AUTOSAR XML (schema 4-2-2)
standard types defined: boolean, sint8, uint16, uint32, uint8, boolean_CompuMethod, boolean_DataConstr, sint8_DataConstr, uint16_DataConstr, uint32_DataConstr
package /ApplicationDataTypes
  7 x app type, all with category=VALUE:
    CarModSts1_2: compu-method=CarModSts1_1, range raw 0..5
    FltEgyCns1_2: compu {0=FltEgyCns1_NoFlt, 1=FltEgyCns1_Flt; unit Unitless}, range raw 0..1
    Nr2_3: compu {phys=raw for raw 0..255; unit Unitless}, range phys 0..255
    Nr5_2: compu {identical; unit Unitless}, range phys 0..7
    UInt4_2: compu {identical; unit Unitless}, range phys 0..15
    UInt8_2: compu {identical; unit Unitless}, range phys 0..255
    UsgModSts1_2: compu-method=UsgModSts1_1, range raw 0..13
  application record data type VehCfgPrm_3: category=STRUCTURE
    8 x application record element, all with category=VALUE, type=Nr2_3:
      BlkIDBytePosn1
      CCPBytePosn{2..8}
  application record data type VehModMngtGlbSafe1_2: category=STRUCTURE
    10 x application record element, all with category=VALUE:
      UsgModSts: type=UsgModSts1_2
      CarModSts1: type=CarModSts1_2
      CarModSubtypWdCarModSubtyp: type=Nr5_2
      EgyLvlElecMai: type=UInt4_2
      EgyLvlElecSubtyp: type=UInt4_2
      PwrLvlElecMai: type=UInt4_2
      PwrLvlElecSubtyp: type=UInt4_2
      FltEgyCnsWdSts: type=FltEgyCns1_2
      Chks: type=UInt8_2
      Cntr: type=UInt4_2
package /BaseTypes
  21 x base type, all with category=FIXED_LENGTH:
    Boolean_2: base-type-size=1, base-type-encoding=BOOLEAN, native-declaration=boolean
    BRMBatteRatedCp_1: base-type-size=16, base-type-encoding=NONE, native-declaration=uint16
    CarTiGlb_2: base-type-size=32, base-type-encoding=NONE, native-declaration=uint32
    HvBattCellTNr_1: base-type-size=16, base-type-encoding=NONE, native-declaration=uint16
    HvBattNr_1: base-type-size=8, base-type-encoding=NONE, native-declaration=uint8
    HvR1_1: base-type-size=16, base-type-encoding=NONE, native-declaration=uint16
    HvT1_3: base-type-size=8, base-type-encoding=NONE, native-declaration=uint8
    Liner32Ah_1: base-type-size=32, base-type-encoding=NONE, native-declaration=uint32
    NGrdt1_2: base-type-size=16, base-type-encoding=2C, native-declaration=sint16
    Nr2_3: base-type-size=8, base-type-encoding=NONE, native-declaration=uint8
    Perc2_2: base-type-size=8, base-type-encoding=NONE, native-declaration=uint8
    Perc5_2: base-type-size=8, base-type-encoding=NONE, native-declaration=uint8
    PwrAtTime_1: base-type-size=16, base-type-encoding=NONE, native-declaration=uint16
    ScrRespOnEve_2: base-type-size=32, base-type-encoding=NONE, native-declaration=uint32
    T3_2: base-type-size=8, base-type-encoding=NONE, native-declaration=uint8
    TempAtTime_1: base-type-size=8, base-type-encoding=NONE, native-declaration=uint8
    TimeDesForSWDL_2: base-type-size=16, base-type-encoding=NONE, native-declaration=uint16
    TrsmVehSpd_2: base-type-size=16, base-type-encoding=NONE, native-declaration=uint16
    U1_2: base-type-size=8, base-type-encoding=NONE, native-declaration=uint8
    UInt16_2: base-type-size=16, base-type-encoding=NONE, native-declaration=uint16
    UInt8_2: base-type-size=8, base-type-encoding=NONE, native-declaration=uint8
package /BMS_ASW/ApplicationDataTypes
  40 x application array data type, all with category=ARRAY:
    AhCpAry: sw-calibration-access=READ-ONLY
      element Element: category=VALUE, type=AhCp, array-size-semantics=FIXED-SIZE, max-number-of-elements=120
    AswCellTmpAry: sw-calibration-access=READ-ONLY
      element Element: category=VALUE, type=AswCellTmp, array-size-semantics=FIXED-SIZE, max-number-of-elements=40
    AswCellVltAry: sw-calibration-access=READ-ONLY
      element Element: category=VALUE, type=AswCellVlt, array-size-semantics=FIXED-SIZE, max-number-of-elements=120
    AswCscTmpAry: sw-calibration-access=READ-ONLY
      element Element: category=VALUE, type=AswCscTmp, array-size-semantics=FIXED-SIZE, max-number-of-elements=40
    AswCscVoltAry: sw-calibration-access=READ-ONLY
      element Element: category=VALUE, type=AswCscVolt, array-size-semantics=FIXED-SIZE, max-number-of-elements=40
    BECMdevelpsignalgroup1
      element Element: category=VALUE, type=BECMdevelpsignalgroup1Functiondevpsignalgroup1_int, array-size-semantics=FIXED-SIZE, max-number-of-elements=8
    BECMdevelpsignalgroup2
      element Element: category=VALUE, type=BECMdevelpsignalgroup2Functiondevpsignalgroup1_int, array-size-semantics=FIXED-SIZE, max-number-of-elements=8
    BECMdevelpsignalgroup3
      element Element: category=VALUE, type=BECMdevelpsignalgroup3Functiondevpsignalgroup1_int, array-size-semantics=FIXED-SIZE, max-number-of-elements=8
    BECMdevelpsignalgroup4
      element Element: category=VALUE, type=BECMdevelpsignalgroup4Functiondevpsignalgroup1_int, array-size-semantics=FIXED-SIZE, max-number-of-elements=8
    BswCellTmpAry: sw-calibration-access=READ-ONLY
      element Element: category=VALUE, type=BswCellTmp, array-size-semantics=FIXED-SIZE, max-number-of-elements=40
    BswCellVltAry: sw-calibration-access=READ-ONLY
      element Element: category=VALUE, type=BswCellVlt, array-size-semantics=FIXED-SIZE, max-number-of-elements=120
    BswCscVoltAry: sw-calibration-access=READ-ONLY
      element Element: category=VALUE, type=BswCscVolt, array-size-semantics=FIXED-SIZE, max-number-of-elements=40
    CarCfgInValVal
      element Element: category=VALUE, type=uint8_BMS, array-size-semantics=FIXED-SIZE, max-number-of-elements=2
    CeBRActvDIDAry: sw-calibration-access=READ-ONLY
      element Element: category=VALUE, type=uint32_BMS, array-size-semantics=FIXED-SIZE, max-number-of-elements=4
    CellmAhAry: sw-calibration-access=READ-ONLY
      element Element: category=VALUE, type=CellmAh, array-size-semantics=FIXED-SIZE, max-number-of-elements=120
    CellTVldAry: sw-calibration-access=READ-ONLY
      element Element: category=VALUE, type=SigVldFlg, array-size-semantics=FIXED-SIZE, max-number-of-elements=40
    CellUSamplBrkAry: sw-calibration-access=READ-ONLY
      element Element: category=VALUE, type=FltFlg, array-size-semantics=FIXED-SIZE, max-number-of-elements=120
    CellVoltVldAry: sw-calibration-access=READ-ONLY
      element Element: category=VALUE, type=SigVldFlg, array-size-semantics=FIXED-SIZE, max-number-of-elements=120
    CfgInValPosn
      element Element: category=VALUE, type=uint16_BMS, array-size-semantics=FIXED-SIZE, max-number-of-elements=2
    CpInmAsAry: sw-calibration-access=READ-ONLY
      element Element: category=VALUE, type=CpInmAs, array-size-semantics=FIXED-SIZE, max-number-of-elements=120
    CscBdTVldAry: sw-calibration-access=READ-ONLY
      element Element: category=VALUE, type=SigVldFlg, array-size-semantics=FIXED-SIZE, max-number-of-elements=40
    FlgAry: sw-calibration-access=READ-ONLY
      element Element: category=VALUE, type=boolean, array-size-semantics=FIXED-SIZE, max-number-of-elements=120
    GBCodeArray: sw-calibration-access=READ-ONLY
      element Element: category=VALUE, type=uint8_BMS, array-size-semantics=FIXED-SIZE, max-number-of-elements=24
    HSDPortAry: sw-calibration-access=READ-ONLY
      element Element: category=VALUE, type=HSDPort, array-size-semantics=FIXED-SIZE, max-number-of-elements=7
    HvBattCod
      element Element: category=VALUE, type=HvBattCodPackCodeX1_int, array-size-semantics=FIXED-SIZE, max-number-of-elements=7
    HvBattT
      element Element: category=VALUE, type=HvBattTAvg_int, array-size-semantics=FIXED-SIZE, max-number-of-elements=3
    KalPAry
      element Element: category=VALUE, type=KalP, array-size-semantics=FIXED-SIZE, max-number-of-elements=120
    nrAFERstAry: sw-calibration-access=READ-ONLY
      element Element: category=VALUE, type=uint16_BMS, array-size-semantics=FIXED-SIZE, max-number-of-elements=4
    nrCurRange: sw-calibration-access=READ-ONLY
      element Element: category=VALUE, type=uint32_BMS, array-size-semantics=FIXED-SIZE, max-number-of-elements=4
    RlyCurAry: sw-calibration-access=READ-ONLY
      element Element: category=VALUE, type=RlyCur, array-size-semantics=FIXED-SIZE, max-number-of-elements=3
    SocPercAry: sw-calibration-access=READ-ONLY
      element Element: category=VALUE, type=cellsocperc, array-size-semantics=FIXED-SIZE, max-number-of-elements=120
    SohPercAry: sw-calibration-access=READ-ONLY
      element Element: category=VALUE, type=SohPerc, array-size-semantics=FIXED-SIZE, max-number-of-elements=120
    SwtStsAry: sw-calibration-access=READ-ONLY
      element Element: category=VALUE, type=SwtSts, array-size-semantics=FIXED-SIZE, max-number-of-elements=120
    TimeInSecAry: sw-calibration-access=READ-ONLY
      element Element: category=VALUE, type=TimeInSec, array-size-semantics=FIXED-SIZE, max-number-of-elements=120
    VehCfgPrm
      element Element: category=VALUE, type=VehCfgPrmBlkIDBytePosn1_int, array-size-semantics=FIXED-SIZE, max-number-of-elements=8
    VehCfgPrmExt
      element Element: category=VALUE, type=VehCfgPrmExtBlkIDBytePosn1_int, array-size-semantics=FIXED-SIZE, max-number-of-elements=8
    VehCfgPrmToASW
      element Element: category=VALUE, type=uint8_BMS, array-size-semantics=FIXED-SIZE, max-number-of-elements=8
    Vin
      element Element: category=VALUE, type=VinBlockNr_int, array-size-semantics=FIXED-SIZE, max-number-of-elements=8
    VINCodeAry: sw-calibration-access=READ-ONLY
      element Element: category=VALUE, type=VINCode, array-size-semantics=FIXED-SIZE, max-number-of-elements=17
    VinToASW
      element Element: category=VALUE, type=uint8_BMS, array-size-semantics=FIXED-SIZE, max-number-of-elements=8
  469 x app type:
    AcChrgEgywh: category=VALUE
    AcChrgnSts: category=VALUE, compu {0=AcChrg_Start, 1=AcChrg_Finish}
    AcChrgnToTar: category=VALUE
    AcChrgPwrw: category=VALUE
    AcMod: category=VALUE, compu-method=AcMod
    AcReqCurr: category=VALUE
    AcReqVlt: category=VALUE
    ActvFlg: category=VALUE, compu {0=ActvFlgFalse, 1=ActvFlgTrue}
    AfeMdCtrl: category=VALUE, sw-calibration-access=READ-WRITE, compu {0=AfeMdCtrl_Normal, 1=AfeMdCtrl_Sleep, 2=AfeMdCtrl_ShuntDown; unit NoUint}
    AfeStsFd: category=VALUE, sw-calibration-access=READ-WRITE, compu {0=AfeStsFd_Init, 1=AfeStsFd_Ready, 2=AfeStsFd_Sleep, 3=AfeStsFd_Shutdown; unit NoUint}
    AhCp: category=VALUE, compu {phys=raw for raw -32768..32767; unit cAh}, unit=cAh
    AmbTEstimdAmbTEstimd: category=VALUE, compu {phys=raw*0.1-70 for raw 0..2047; unit degC}
    AmbTEstimdAmbTEstimd_ASW: category=VALUE
    AmbTEstimdQf: category=BOOLEAN, compu {0=HvacTIfQf_SnsrDataNotOk, 1=HvacTIfQf_SnsrDataOk; unit Unitless}
    AmbTEstimdQf_ASW: category=BOOLEAN
    AmbTRawAmbTVal: category=VALUE, compu {phys=raw*0.1-70 for raw 0..2047; unit degC}
    AmbTRawAmbTVal_ASW: category=VALUE
    AmbTRawQly: category=VALUE, compu-method=GenQf1_1
    AmbTRawQly_ASW: category=VALUE
    AswCellTmp: category=VALUE, compu {phys=raw for raw -600..1250; unit 0.1degC}
    AswCellVlt: category=VALUE, compu {phys=raw for raw 0..65535; unit mV}
    AswCscTmp: category=VALUE, sw-calibration-access=READ-ONLY, compu {phys=raw for raw -600..1250; unit mV}
    AswCscVolt: category=VALUE, sw-calibration-access=READ-ONLY, compu {phys=raw for raw -INF..INF; unit mV}
    BalOperMod: category=VALUE, compu {0=BalDefault, 1=BalIdle, 2=BalUpdateTi, 3=BalBalancing, 4=BalAbort}
    BalTiCalcMod: category=VALUE, compu {0=BalTiCalcIdle, 1..8=DriveMod1..DriveMod8, 9=RTCMod, 255=NVMInvldMod}
    BATIOperMod: category=VALUE, compu {0=Default, 1=Initial, 2=InitialFinish, 3=OfsCalFinish, 4=On}
    BattClimaPwr: category=VALUE, compu {phys=raw for raw 0..65535; unit W}
    BclCurrReq: category=VALUE, compu {phys=raw for raw 0..65535; unit A}
    BclVoltReq: category=VALUE, compu {phys=raw for raw 0..65535; unit V}
    BcpBattNomEgy: category=VALUE, sw-calibration-access=READ-ONLY, compu {phys=raw for raw 0..65535; unit kWh}
    BecmDcChgRlyCmd: category=VALUE, sw-calibration-access=READ-ONLY, compu {0=ChgRlyCmd_NoReq, 1=ChgRlyCmd_Close, 2=ChgRlyCmd_Open, 3=ChgRlyCmd_KeepSt; unit Unitless}
    BECMdevelpsignalgroup{1..4}Functiondevpsignalgroup1_int: category=VALUE, compu {identical; unit Unitless}, range phys 0..255, raw 0..255
    BkpOfDstTrvld: category=VALUE, compu {phys=raw for raw 0..2000000; unit km}
    BkpOfDstTrvld_ASW: category=VALUE
    BMSSts: category=VALUE, compu {0=BMSSts_init, 1=BMSSts_Standby, 2=BMSSts_PreChrg, 3=BMSSts_Ready, 4=BMSSts_ACChrgn, 5=BMSSts_DCChrgn, 6=BMSSts_EmgyShtDwn, 7=BMSSts_FltMod, 8=BMSSts_PreSleep, 9=BMSSts_Sleep, 10=BMSSts_IntegrityTest, 11=BMSSts_RTCWakeUp, 12=BMSSts_EOLMod}
    BookChrgTarValLnr: category=VALUE, compu {phys=raw*0.05 for raw 0..2000; unit %}
    BookChrgTarValLnr_ASW: category=VALUE, sw-calibration-access=READ-ONLY, compu {phys=raw for raw 0..2000; unit %}, unit=%
    boolean: category=VALUE, compu {0=Disable, 1=Enable}
    BpsOverAbsThresholdFlgH: category=VALUE, compu {identical}, range raw 0..1
    BpsOverAbsThresholdFlgH_ASW: category=VALUE
    BpsOverAbsThresholdFlgL: category=VALUE, compu {0=Cx0_No_Fault (No Fault), 1=Cx1_Pressure_Out_of_Absolute_Threshold_Value (Pressure Out of Absolute Threshold Value)}, range raw 0..1
    BpsOverAbsThresholdFlgL_ASW: category=VALUE
    BpsOverSlopeThresholdFlgH: category=VALUE, compu {identical}, range raw 0..1
    BpsOverSlopeThresholdFlgH_ASW: category=VALUE
    BpsOverSlopeThresholdFlgL: category=VALUE, compu {0=Cx0_No_Fault (No Fault), 1=Cx1_Over_the_Slope_Threshold_Value (Over the Slope Threshold Value)}, range raw 0..1
    BpsOverSlopeThresholdFlgL_ASW: category=VALUE
    BpsPressureDataH: category=VALUE, compu {phys=raw*0.1 for raw 0..4095; unit kPa}
    BpsPressureDataH_ASW: category=VALUE
    BpsPressureDataL: category=VALUE, compu {phys=raw*0.1 for raw 0..4095; unit kPa}
    BpsPressureDataL_ASW: category=VALUE
    BrmSysRateCp: category=VALUE, compu {phys=raw for raw 0..65535; unit Ah}
    BswCellTmp: category=VALUE, compu {phys=raw for raw -999999..999999; unit mV}
    BswCellVlt: category=VALUE, compu {phys=raw for raw -999999..999999; unit mV}
    BswCscVolt: category=VALUE, sw-calibration-access=READ-ONLY, compu {phys=raw for raw -INF..INF; unit mV}
    CarCfgModSts: category=VALUE, compu {0=VCG_stDftSts, 1=VCG_stValCfgSts, 2=VCG_stBulkSts; unit figure}
    CarTiGlb: category=VALUE, compu {phys=raw*0.1 for raw 0..4294967295; unit s}
    CarTiGlb_ASW: category=VALUE
    CellmAh: category=VALUE, compu {phys=raw for raw -INF..INF; unit mAh}
    cellsocperc: category=VALUE, compu {phys=raw for raw -32768..32767; unit %}
    CellUMax: category=VALUE, compu {phys=raw*0.001 for raw 0..5000; unit Volt}
    CellUMaxId: category=VALUE, compu {phys=raw for raw 0..250; unit Unitless}
    CellUMaxLim: category=VALUE, compu {phys=raw*0.001 for raw 0..5000; unit Volt}
    CellUMin: category=VALUE, compu {phys=raw*0.001 for raw 0..5000; unit Volt}
    CellUMinId: category=VALUE, compu {phys=raw for raw 0..250; unit Unitless}
    CellVlt: category=VALUE, sw-calibration-access=READ-ONLY, compu {phys=raw for raw 0..65535; unit mV}
    CfgPrmVal: category=VALUE, compu {phys=raw for raw 0..255; unit figure}
    Chks: category=VALUE, sw-calibration-access=READ-ONLY, compu {phys=raw for raw 0..65524; unit NoUint}
    ChrgEquipIDc: category=VALUE, compu {phys=raw*0.1-1638 for raw 0..32767; unit A}
    ChrgEquipIDcL2: category=VALUE, sw-calibration-access=READ-ONLY, compu {phys=raw*0.1-1638 for raw 0..32767; unit A}
    ChrgEquipIDcL2_ASW: category=VALUE, sw-calibration-access=READ-ONLY
    ChrgnSts: category=VALUE, sw-calibration-access=READ-ONLY
    ChrgSts: category=VALUE, compu {0=ChrgSts_NotReady, 1=ChrgSts_ReadyToChrgn, 2=ChrgSts_Chrgn, 3=ChrgSts_ChrgErr, 4=ChrgSts_ChrgOK}
    CM_SetEventStatus: category=VALUE, sw-calibration-access=READ-ONLY, compu-method=CM_SetEventStatus
    Cmd: category=VALUE, compu {0=Open, 1=Clsd}
    CmplFlg: category=VALUE, compu {0=CmplFlg_OK, 1=CmplFlg_NOK}
    CmptmtCoolgSts: category=VALUE, compu-method=CmptmtCoolgSts_1
    Cntr: category=VALUE, compu {phys=raw for raw 0..65535; unit NoUint}
    cofshnt: category=VALUE, compu {phys=raw for raw -100000000..100000000; unit figure}
    ComQly: category=VALUE, compu {0=ComQlyNOk, 1=ComQlyOk}
    CoolgLvlReq: category=VALUE, compu {0=NotReqd, 1=LoReq, 2=MedReq, 3=HiReq}
    CooltFlow: category=VALUE, compu {phys=raw for raw 0..51.1; unit L / min}
    CooltLvlFlg: category=VALUE, compu {0=Full, 1=Empty}
    CooltTSigForDtElec: category=VALUE, compu {phys=raw*0.1-40 for raw 0..1800; unit degC}
    CooltTSigForDtElec_ASW: category=VALUE
    CpInmAs: category=VALUE, compu {phys=raw for raw 0..INF; unit mAs}
    CPSRFallFlg: category=VALUE, sw-calibration-access=READ-ONLY
    CPSRU: category=VALUE, compu {phys=raw*0.1 for raw 0..250; unit Volt}
    CrashStsSafeChks: category=VALUE, compu {identical; unit Unitless}
    CrashStsSafeCntr: category=VALUE, compu {identical; unit Unitless}
    CrashStsSafeSts: category=BOOLEAN, compu {0=CrashSts2_NoCrash, 1=CrashSts2_Crash; unit Unitless}
    CurrtInA: category=VALUE, compu {phys=raw for raw -1500..1500; unit A}
    CurrtInmA: category=VALUE, compu {phys=raw for raw -1500000..1500000; unit mA}
    DCChaPwrAct: category=VALUE, sw-calibration-access=READ-ONLY, compu {phys=raw*0.25 for raw 0..2047; unit kW}
    DCChaPwrAct_ASW: category=VALUE, sw-calibration-access=READ-ONLY
    DCChgRlyStuckDetct: category=VALUE, sw-calibration-access=READ-ONLY, compu {0=RlyStuckDetct_NoReq, 1=RlyStuckDetct_RelayStuckDetect; unit Unitless}
    DCChgStopSTS: category=VALUE, compu-method=DCChgStopSTS
    DCChrgnHndlSts: category=VALUE, compu-method=DCChrgnHndlSts
    DCChrgnNegPortT: category=VALUE, compu {phys=raw-50 for raw 0..250; unit degC}
    DcChrgnOn: category=VALUE, compu {0=DcChrg_Start, 1=DcChrg_Finish}
    DCChrgnPosPortT: category=VALUE, compu {phys=raw-50 for raw 0..250; unit degC}
    DCChrgSt_ASW: category=VALUE, compu-method=DCChrgSt_ASW
    DchaPwrAllwd: category=VALUE, sw-calibration-access=READ-ONLY, compu {phys=raw*20 for raw 0..65535; unit W}
    DchrgnIntSckState: category=VALUE, sw-calibration-access=READ-ONLY
    DchrgnIntState: category=VALUE, sw-calibration-access=READ-ONLY
    DChrgTarValLnr: category=VALUE, compu {phys=raw*0.05 for raw 0..2000; unit %}
    DChrgTarValLnr_ASW: category=VALUE
    DCPreHeatgReq: category=VALUE, compu {0=NoPreHeat, 1=PreHeat, 2=PreHeatErr}
    DemFltSts: category=VALUE, sw-calibration-access=READ-WRITE, compu {phys=raw for raw 0..255; unit NoUint}
    DenoOfDiagcRateGen: category=BOOLEAN, compu {0=Boolean_FALSE, 1=Boolean_TRUE; unit Unitless}
    DispHvBattLvlOfChrg: category=VALUE, sw-calibration-access=READ-ONLY, compu {phys=raw*0.1 for raw 0..1023; unit %}
    DispHvBattLvlOfChrg_ASW: category=VALUE, sw-calibration-access=READ-ONLY
    DrvgCyc: category=BOOLEAN, compu {0=OnOff1_Off, 1=OnOff1_On; unit Unitless}
    DrvgCycToClrPrmntDtc: category=BOOLEAN, compu {0=Boolean_FALSE, 1=Boolean_TRUE; unit Unitless}
    Duty: category=VALUE, compu {phys=raw for raw 0..255; unit %}
    Egyah: category=VALUE, compu {phys=raw for raw -INF..INF; unit Ah}
    Egykwh: category=VALUE, compu {phys=raw for raw -INF..INF; unit NoUint}
    Egywh: category=VALUE, compu {phys=raw for raw -INF..INF; unit Wh}
    Egywh_uint32: category=VALUE, compu {phys=raw for raw -INF..INF; unit Wh}
    EngAmbTCalcd: category=VALUE, compu {phys=raw*0.5-60 for raw 0..511; unit Unitless}
    EngAmbTCalcd_ASW: category=VALUE
    EngNSafeEngN: category=VALUE, compu {phys=raw*0.5 for raw 0..32767; unit rpm}
    EngNSafeEngN_ASW: category=VALUE
    EngNSafeEngNChks: category=VALUE, compu {identical; unit Unitless}
    EngNSafeEngNChks_ASW: category=VALUE
    EngNSafeEngNCntr: category=VALUE, compu {identical; unit Unitless}
    EngNSafeEngNCntr_ASW: category=VALUE
    EngNSafeEngNGrdt: category=VALUE, compu {phys=raw for raw -30000..32767; unit RpmPerSec}
    EngNSafeEngNGrdt_ASW: category=VALUE
    EngOnReq: category=BOOLEAN, compu {0=OnOff1_Off, 1=OnOff1_On; unit Unitless}
    EngSt1WdStsChks: category=VALUE, compu {identical; unit Unitless}
    EngSt1WdStsCntr: category=VALUE, compu {identical; unit Unitless}
    EngSt1WdStsEngSt1WdSts: category=VALUE, compu-method=EngSt1_1
    EngTEngT: category=VALUE, compu {phys=raw-50 for raw 0..250; unit degC}
    EngTEngT_ASW: category=VALUE
    EngTiOn: category=VALUE, compu {phys=raw for raw 0..65535; unit s}
    EngTiOn_ASW: category=VALUE
    EngTQf: category=VALUE, compu-method=Qf1_1
    EngTQf_ASW: category=VALUE
    EolMod: category=VALUE, compu {0=EntryEOLCmd, 1=ExitEOLCmd}
    EOLSts: category=VALUE, compu {0=Forbid, 1=Permit}
    EstimPwr: category=VALUE, compu {phys=raw for raw 0..4294967295; unit W}
    Factor: category=VALUE, compu {phys=raw for raw 0..100; unit NoUint}
    FastChrgnLEDIndctn: category=VALUE, compu-method=FastChrgnLEDIndctn
    FastChrgnLockCtrl: category=VALUE, compu {0=OnOff1_Off, 1=OnOff1_On; unit Unitless}
    filmHeatingSts: category=VALUE, compu-method=filmHeatingSts
    float32_BMS_2: category=VALUE, sw-calibration-access=READ-ONLY
    FltFlg: category=VALUE, compu {0=False, 1=True}
    FltLvl: category=VALUE, compu {0=SigOk, 1..5=Lvl1..Lvl5}
    Frq: category=VALUE, compu {phys=raw for raw 0..65535; unit Hz}
    GpsStatus: category=VALUE, sw-calibration-access=READ-ONLY
    HeatGen: category=VALUE, compu {phys=raw for raw 0..65535; unit W}
    HeatgLvlReq: category=VALUE, compu {0=NotReqd, 1=LoReq, 2=MedReq, 3=HiReq}
    HeatModReq: category=VALUE, compu {0=Close, 1=Cool, 2=Heat, 3=Cycle}
    HiVlt: category=VALUE, compu {phys=raw for raw -INF..INF; unit mV}
    HsdFlt: category=VALUE, compu {0=HsdFlt1}
    HSDMod: category=VALUE, compu {0=GPIOMod, 1=SPIMod}
    HSDPort: category=VALUE, compu {0=False, 1=Ture}
    HvAuxActPwr: category=VALUE, sw-calibration-access=READ-ONLY, compu {phys=raw*20 for raw 0..INF; unit W}
    HvBattBalFlg: category=BOOLEAN, compu {0=OnOff1_Off, 1=OnOff1_On; unit Unitless}
    HvBattCap: category=VALUE, compu {phys=raw*0.1 for raw 0..65535; unit Ah}
    HvBattCellTInfoHvBattSnsrT: category=VALUE, compu {phys=raw-40 for raw 0..255; unit degC}
    HvBattCellTInfoHvBattTMax: category=VALUE, compu {phys=raw-40 for raw 0..255; unit degC}
    HvBattCellTInfoHvBattTMin: category=VALUE, compu {phys=raw-40 for raw 0..255; unit degC}
    HvBattCellTInfoHvBattTSnsrNr: category=VALUE, compu {identical; unit Unitless}
    HvBattCellTInfoHvTempSnsrTMaxsSerlNr: category=VALUE, compu {identical; unit Unitless}
    HvBattCellTInfoHvTempSnsrTMinSerlNr: category=VALUE, compu {identical; unit Unitless}
    HvBattCellTNr: category=VALUE, compu {phys=raw for raw 0..65531; unit Unitless}
    HvBattCellUInfoU{1..4}: category=VALUE, compu {identical; unit Unitless}
    HvBattChrgnCmd: category=VALUE, sw-calibration-access=READ-ONLY
    HvBattChrgnCmpl: category=BOOLEAN, compu {0=NoYes1_No, 1=NoYes1_Yes; unit Unitless}
    HvBattChrgnEgyCnsAllwd1: category=VALUE, compu {phys=raw*20 for raw 0..8191; unit Wh}
    HvBattChrgnILim: category=VALUE, compu {phys=raw*0.1 for raw 0..8191; unit A}
    HvBattChrgnPwrAllwd1: category=VALUE, sw-calibration-access=READ-ONLY, compu {phys=raw*20 for raw 0..8191; unit W}
    HvBattChrgnPwrCns1: category=VALUE, compu {phys=raw*100 for raw 0..2047; unit W}
    HvBattChrgnPwrCritDes1: category=VALUE, compu {phys=raw*100 for raw 0..2047; unit W}
    HvBattChrgnPwrNormDes1: category=VALUE, compu {phys=raw*100 for raw 0..2047; unit W}
    HvBattClimaPwr: category=VALUE, compu {phys=raw*100 for raw 0..2047; unit W}
    HvBattClrRdyReq: category=BOOLEAN, compu {0=OnOff1_Off, 1=OnOff1_On; unit Unitless}
    HvBattCodLen: category=VALUE, compu {phys=raw for raw 0..250; unit Unitless}
    HvBattCodPackCodeX1_int: category=VALUE, compu {identical; unit Unitless}, range phys 0..255, raw 0..255
    HvBattCoolgCmd: category=VALUE, compu-method=HVBattChargnCmd_1
    HvBattCoolgEgyCnsAllwd1: category=VALUE, compu {phys=raw*20 for raw 0..1023; unit Wh}
    HvBattCoolgEgyCnsAllwd1_ASW: category=VALUE
    HvBattCoolgEgyReq1: category=VALUE, compu {phys=raw*20 for raw 0..1023; unit Wh}
    HvBattCoolgReq: category=VALUE, compu-method=HvBattCoolgReq_1
    HvBattCoolgSts: category=BOOLEAN, compu {0=ClimaSts_Start, 1=ClimaSts_Finish; unit Unitless}
    HvBattCooltFlowReq: category=VALUE, compu {phys=raw*0.1 for raw 0..511; unit L / min}
    HvBattCooltLvl: category=BOOLEAN, compu {0=HvBattCooltLvl_Full, 1=HvBattCooltLvl_Empty; unit Unitless}
    HvBattCooltMaxTReq: category=VALUE, compu {phys=raw-50 for raw 0..250; unit degC}
    HvBattCooltMinTReq: category=VALUE, compu {phys=raw-50 for raw 0..250; unit degC}
    HvBattCooltOutletT: category=VALUE, compu {phys=raw*0.1-60 for raw 0..1850; unit degC}
    HvBattCooltT: category=VALUE, compu {phys=raw*0.1-60 for raw 0..1850; unit degC}
    HvBattCooltTReq: category=VALUE, compu {phys=raw-50 for raw 0..250; unit degC}
    HvBattEgyAvlChrg1: category=VALUE, compu {phys=raw*20 for raw 0..8191; unit Wh}
    HvBattEgyAvlDcha1: category=VALUE, compu {phys=raw*20 for raw 0..8191; unit Wh}
    HvBattEgyCdn: category=VALUE, compu {phys=raw*0.5 for raw 0..200; unit %}
    HvBattErrIndcnReq: category=BOOLEAN, compu {0=OnOff1_Off, 1=OnOff1_On; unit Unitless}
    HvBattFlwEstmd: category=VALUE, compu {phys=raw*0.1 for raw 0..511; unit L / min}
    HvBattFlwEstmd_ASW: category=VALUE
    HvBattHeatgEgyReq: category=VALUE, compu {phys=raw*20 for raw 0..1023; unit Wh}
    HvBattHeatGenn: category=VALUE, compu {phys=raw*100 for raw 0..2047; unit W}
    HvBattHeatgPwr: category=VALUE, compu {phys=raw*100 for raw 0..2047; unit W}
    HvBattIDc1: category=VALUE, compu {phys=raw*0.1-1638 for raw 0..32767; unit A}
    HvBattILim: category=VALUE, compu {phys=raw*0.1 for raw 0..8191; unit A}
    HvBattLimnIndcn: category=VALUE, compu {identical; unit Unitless}
    HvBattMismatchFlt: category=BOOLEAN, compu {0=DevErrSts2_NoFlt, 1=DevErrSts2_Flt; unit Unitless}
    HvBattNr: category=VALUE, compu {phys=raw for raw 0..250; unit Unitless}
    HvBattPreChrgReq: category=BOOLEAN, compu {0=OnOff1_Off, 1=OnOff1_On; unit Unitless}
    HvBattPulseHeatSts: category=VALUE, compu {0=HeatDefault, 1=HeatComplete, 2=HeatReserve1, 3=HeatReserve2}
    HvBattPVal: category=VALUE, compu {phys=raw*0.05 for raw 0..8191; unit KiloPa}
    HvBattPwrCdn: category=VALUE, compu {phys=raw*0.5 for raw 0..200; unit %}
    HvBattPwrLimChrg1: category=VALUE, compu {phys=raw*0.25 for raw 0..2047; unit kW}
    HvBattPwrLimDcha1: category=VALUE, compu {phys=raw*0.25 for raw 0..2047; unit kW}
    HvBattPwrLimDchaSoft: category=VALUE, compu {phys=raw*0.25 for raw 0..2047; unit kW}
    HvBattSoc: category=VALUE, compu {phys=raw*0.05 for raw 0..2000; unit %}
    HvBattSocLimHi: category=VALUE, compu {phys=raw*0.05 for raw 0..2000; unit %}
    HvBattSocLimLo: category=VALUE, compu {phys=raw*0.05 for raw 0..2000; unit %}
    HvBattSocLimMax: category=VALUE, compu {phys=raw*0.05 for raw 0..2000; unit %}
    HvBattSocLimMin: category=VALUE, compu {phys=raw*0.05 for raw 0..2000; unit %}
    HvBattTAvg_int: category=VALUE, compu {phys=raw*0.1 for raw -2560..2559; unit degC}, range phys 0..255, raw 0..255
    HvBattThermInfoInFuturePwrAtTime: category=VALUE, sw-calibration-access=READ-WRITE, compu {phys=raw*50-25000 for raw 0..1000; unit W}
    HvBattThermInfoInFuturePwrAtTime_ASW: category=VALUE, sw-calibration-access=READ-WRITE
    HvBattThermInfoInFutureSequenceNo: category=VALUE, sw-calibration-access=READ-WRITE
    HvBattThermInfoInFutureSequenceNo_ASW: category=VALUE, sw-calibration-access=READ-WRITE
    HvBattThermInfoInFutureTempAtTime: category=VALUE, sw-calibration-access=READ-ONLY, compu {phys=raw-50 for raw 0..255; unit degC}
    HvBattThermInfoInFutureTempAtTime_ASW: category=VALUE, sw-calibration-access=READ-ONLY
    HvBattThermInfoInFutureThermModAtTime: category=VALUE, sw-calibration-access=READ-WRITE
    HvBattThermInfoInFutureThermModAtTime_ASW: category=VALUE, sw-calibration-access=READ-WRITE
    HvBattThermInfoInFutureTime: category=VALUE, sw-calibration-access=READ-WRITE
    HvBattThermInfoInFutureTime_ASW: category=VALUE, sw-calibration-access=READ-WRITE
    HvBattThermInfoInFutureVersionNo: category=VALUE, sw-calibration-access=READ-WRITE
    HvBattThermInfoInFutureVersionNo_ASW: category=VALUE, sw-calibration-access=READ-WRITE
    HvBattThermMod: category=VALUE, compu-method=HvBattThermMod_2
    HvBattThermReqFb: category=VALUE, compu-method=HvBattThermReqFb_3
    HvBattTMaxSerlNr: category=VALUE, compu {phys=raw for raw 0..250; unit Unitless}
    HvBattTMinSerlNr: category=VALUE, compu {phys=raw for raw 0..250; unit Unitless}
    HvBattUDc: category=VALUE, compu {phys=raw*0.25 for raw 0..2044; unit Volt}
    HvBattUDynMaxLim: category=VALUE, compu {phys=raw*0.25 for raw 0..2044; unit Volt}
    HvBattUDynMinLim: category=VALUE, compu {phys=raw*0.25 for raw 0..2044; unit Volt}
    HvBattULim: category=VALUE, compu {phys=raw*0.25 for raw 0..2044; unit Volt}
    HvBattVoltMaxSerlNr: category=VALUE, compu {phys=raw for raw 0..250; unit Unitless}
    HvBattVoltMinSerlNr: category=VALUE, compu {phys=raw for raw 0..250; unit Unitless}
    HvBattWMDSts: category=VALUE, compu {identical; unit Unitless}
    HVCCOperMod: category=VALUE, compu {0=HVCCOperMod_Init, 1=HVCCOperMod_Standby, 2=HVCCOperMod_PrecOngoing, 3=HVCCOperMod_HVOnPrfmd, 4=HVCCOperMod_PrecTiOut, 5=HVCCOperMod_PrecOvCurr, 6=HVCCOperMod_Shutdown, 7=HVCCOperMod_IntegrityTest, 8=HVCCOperMod_RlyFlt, 9=EmgyShutdown, 10=HVCCOperMod_Reserve}
    HvCellTDifFlt: category=VALUE, compu-method=FauLevel_2
    HvCellTOverFlt: category=VALUE, compu-method=FauLevel_2
    HvCellUDifFlt: category=VALUE, compu-method=FauLevel_2
    HvCellUOverFlt: category=VALUE, compu-method=FauLevel_2
    HvCellUUnderFlt: category=VALUE, compu-method=FauLevel_2
    HvchSts: category=VALUE, sw-calibration-access=READ-ONLY
    HVCnctSts: category=VALUE, compu {0=Init, 1=HVPre, 2=HVON, 3=Invalid}
    HVIL{1..3}Sts: category=BOOLEAN, compu {0=OpenClose_Open, 1=OpenClose_Close; unit Unitless}
    HvilFlt: category=BOOLEAN, compu {0=DevErrSts2_NoFlt, 1=DevErrSts2_Flt; unit Unitless}
    HVILSts: category=VALUE, compu-method=HVILSts
    HvIsoFlt: category=VALUE, compu-method=FauLevel_2
    HvIsoR: category=VALUE, compu {phys=raw for raw 0..60000; unit kOhm}
    HvIsoSts: category=VALUE, compu-method=HvIsoSts_2
    HvOnMaiReq: category=VALUE, compu-method=HvActvnSts_1
    HvPackOverChrgFlt: category=VALUE, compu-method=FauLevel_2
    HvPackUOverFlt: category=VALUE, compu-method=FauLevel_2
    HvPackUUnderFlt: category=VALUE, compu-method=FauLevel_2
    HvSocHiFlt: category=VALUE, compu-method=FauLevel_2
    HvSocHopFlt: category=VALUE, compu-method=FauLevel_2
    HvSocLoFlt: category=VALUE, compu-method=FauLevel_2
    HVSts: category=VALUE, compu {0=HVSts_HVOff, 1=HVSts_PreChrg, 2=HVSts_HVOn, 3=HVSts_FailHVOn}
    HvSysActvnInhb: category=BOOLEAN, compu {0=OkNotOk1_Ok, 1=OkNotOk1_NotOk; unit Unitless}
    HvSysCrashFb: category=VALUE, compu-method=CrashFb_1
    HvSysLimnIndcn: category=VALUE, compu {identical; unit Unitless}
    HvSysPwrOff: category=BOOLEAN, compu {0=OkNotOk1_Ok, 1=OkNotOk1_NotOk; unit Unitless}
    HvSysRlyStsChks: category=VALUE, compu {identical; unit Unitless}
    HvSysRlyStsCntr: category=VALUE, compu {identical; unit Unitless}
    HvSysRlyStsHvSysRlySts: category=VALUE, compu-method=HvActvnSts_1
    HvSysSts: category=VALUE, compu {0=HvSysSts_Inin, 1=HvSysSts_Test, 2=HvSysSts_Rdy; unit Unitless}
    Index: category=VALUE, compu {phys=raw for raw 0..255; unit NoUint}
    InfoVers: category=VALUE, compu {phys=raw for raw 0..255; unit ver}
    IntegritTestSts: category=VALUE, compu {0=IntegritTestSts_Inin, 1=IntegritTestSts_Test, 2=IntegritTestSts_Rdy}
    IsgCooltT: category=VALUE, compu {phys=raw-40 for raw 0..255; unit degC}
    IsgCooltT_ASW: category=VALUE
    IsgModSts: category=VALUE, compu-method=IsgModTyp2_3
    IsgUDc: category=VALUE, compu {phys=raw*0.25 for raw 0..2044; unit Volt}
    IsgUDc_ASW: category=VALUE
    IsgVehPulseHeatModSts: category=VALUE, compu {0=OnOff1_Off, 1=OnOff1_On}
    IsoCrshSts: category=VALUE, compu-method=IsoCrshSts
    IsoDIDWrResSts: category=VALUE, compu {phys=raw for raw 0..255; unit figure}
    IsoFlt: category=VALUE, compu {0=IsoDefault, 1=OneLevelFlt, 2=TwoLevelFlt}
    IsoFltSts: category=VALUE, compu-method=IsoFltSts
    IsoMod: category=VALUE, compu {0=Default, 1=LvMode, 2=HvMode, 3=ChargingMode}
    IsoSts: category=VALUE, compu-method=IsoSts
    IuprDenominatorInhb: category=BOOLEAN, compu {0=InhibitSts_NotInhibited, 1=InhibitSts_Inhibited; unit Unitless}
    KalP: category=VALUE, compu {phys=raw for raw -500..500; unit NoUint}
    LoadValCalcd: category=VALUE, compu {phys=raw*0.3921568627 for raw 0..255; unit %}
    LoadValCalcd_ASW: category=VALUE
    LoDCChrgSt: category=VALUE, compu-method=LoDCChrgSt
    LosLimnIndcn: category=VALUE, compu {phys=raw for raw 0..65535; unit NoUint}
    LowVlt: category=VALUE, compu {phys=raw for raw -999999..999999; unit mV}
    LsdFlt: category=VALUE, compu {0=LsdFlt1}
    MaintainBattTCtrl: category=VALUE, sw-calibration-access=READ-ONLY
    MemQly: category=VALUE, compu {0=MemQlyNOk, 1=MemQlyOk}
    MntnBattTFbSts: category=VALUE, compu-method=MntnBattTFbSts
    MntnBattTTimin: category=VALUE
    MonrCycCmpl: category=BOOLEAN, compu {0=NotCmpl1_NotCmpl, 1=NotCmpl1_Cmpl; unit Unitless}
    MonrSts: category=VALUE, compu {0=MonrSts1, 1=MonrSts2}
    MultiCurrt: category=VALUE, compu {phys=raw for raw 0..100; unit NoUint}
    Number: category=VALUE, compu {phys=raw for raw 0..255; unit NoUint}
    OdpDcChgRlyState: category=VALUE, sw-calibration-access=READ-ONLY
    Ohm_HVIL: category=VALUE, compu {phys=raw for raw 0..100000000; unit Ohm}
    OnBdChrgrCurrA: category=VALUE, sw-calibration-access=READ-ONLY, compu {phys=raw for raw -200..200; unit A}, unit=A
    OnBdChrgrHndlSts1: category=VALUE, sw-calibration-access=READ-ONLY
    OnBdChrgrIDc: category=VALUE, sw-calibration-access=READ-ONLY, compu {phys=raw*0.1-200 for raw 0..4000; unit A}
    OnBdChrgrSt: category=VALUE, sw-calibration-access=READ-ONLY
    OnBdChrgrUDc: category=VALUE, sw-calibration-access=READ-ONLY, compu {phys=raw*0.2 for raw 0..6000; unit V}
    OnBdIntDischrgrSt: category=VALUE, sw-calibration-access=READ-ONLY, compu {0=DischrgrSt_Idle, 1=DischrgrSt_PreStrt, 2=DischrgrSt_Dischrgn, 3=DischrgrSt_Alrm, 4=DischrgrSt_ShutDown, 5=DischrgrSt_Rstrt; unit Unitless}
    OnOffNoReq: category=VALUE, compu {0=OnOffNoReq_NoReq, 1=OnOffNoReq_On, 2=OnOffNoReq_Off}
    OperMod: category=VALUE, compu {0=OperMod_init, 1=OperMod_Standby, 2=OperMod_PreChrg, 3=OperMod_Ready, 4=OperMod_ACChrgn, 5=OperMod_DCChrgn, 6=OperMod_EmgyShtDwn, 7=OperMod_FltMod, 8=OperMod_PreSleep, 9=OperMod_Sleep, 10=OperMod_IntegrityTest, 11=OperMod_StandbyOCV, 12=OperMod_UpdateSOC, 13=OperMod_EOLMod, 14=OperMod_Idle, 15=OperMod_Reinit, 16=OperMod_Cnt, 17=OperMod_RlyOpen, 18=OperMod_RlyCls}
    PackAirPVal: category=VALUE, compu {phys=raw for raw 0..65535; unit Pa}
    PackNr: category=VALUE, compu {phys=raw for raw 0..250; unit Unitless}
    PakRes: category=VALUE, sw-calibration-access=READ-ONLY, unit=Ohm
    PCHMSts: category=VALUE, compu-method=PCHMSts
    Perc: category=VALUE, compu {phys=raw for raw 0..65535; unit NoUint}
    PreHeatgReq: category=VALUE, compu {0=PreHeatgReq_Default (CompuScale), 1=PreHeatgReq_On (CompuScale), 2=PreHeatgReq_Off (CompuScale), 3=PreHeatgReq_Reserved (CompuScale)}
    PreHeatSts: category=VALUE, compu {phys=raw for raw 0..255; unit NoUint}
    PreSocOperMod: category=VALUE, compu {0=AhCalcn, 1=ChgKal, 2=DisKal}
    PressfloatVal: category=VALUE, compu {phys=raw for raw -INF..INF; unit kPa}
    PressVal: category=VALUE, compu {phys=raw for raw 0..INF; unit kPa}
    PrpsnFbLimnIndcn: category=VALUE, compu {identical; unit Unitless}
    PrpsnSysActv: category=BOOLEAN, compu {0=NotCmpl1_NotCmpl, 1=NotCmpl1_Cmpl; unit Unitless}
    PulseHeatTsts: category=VALUE, compu-method=PulseHeatTsts
    Pwr: category=VALUE, compu {phys=raw for raw -INF..INF; unit kw}
    PwrEgyMgrAvl: category=VALUE, sw-calibration-access=READ-ONLY, compu {phys=raw*20 for raw 0..2047; unit W}
    RadFanCoolgSts: category=VALUE, compu {identical; unit Unitless}
    RlyCur: category=VALUE, sw-calibration-access=READ-ONLY
    RlySts: category=VALUE, compu {0=Open, 1=Clsd, 2=KeepSt, 3=OpenAndReqActvDcha}
    RoutCtlFlg: category=VALUE, compu {0=RoutCtlFalse (RoutctlFalse), 1=RoutCtlTrue}
    RTCSleepTi: category=VALUE, compu {phys=raw for raw 0..INF; unit min}
    RTCTi: category=VALUE, compu {phys=raw for raw 0..65535; unit figure}
    Rval: category=VALUE, compu {phys=raw for raw -INF..INF; unit kOhm}
    SbcSafeStFlg: category=VALUE, compu {0=SBCNormal, 1=SBCNotNormal}
    SeqNr: category=VALUE, compu {phys=raw for raw 0..255; unit NoUint}
    SigInvldFlg: category=VALUE, compu {0=False, 1=True}
    SigQly: category=VALUE, compu {0=Default, 1=NOK, 2=Degrated, 3=OK}
    SigVldFlg: category=VALUE, compu {0=False, 1=True}
    SocOperMod: category=VALUE, compu-method=SocOperMod
    SohPerc: category=VALUE, compu {raw=phys for phys 0..65535; unit ?}, unit=?
    stsAFEFltSts: category=VALUE, sw-calibration-access=READ-WRITE, compu {phys=raw for raw 0..255; unit NoUint}
    stsPNCStatus: category=VALUE, sw-calibration-access=READ-WRITE, compu {phys=raw for raw 0..4294967296; unit NoUint}
    SwtSts: category=VALUE, compu {0=Disable, 1=Enable}
    TelmHVBattPlsHeatgReq: category=VALUE, sw-calibration-access=READ-ONLY
    ThermRunawayWakeUpCntr: category=VALUE, compu {phys=raw for raw 0..255; unit NoUint}
    THMDOperMod: category=VALUE, compu-method=THMDOperMod
    ThrPos: category=VALUE, compu {phys=raw*0.5 for raw 0..200; unit %}
    ThrPos_ASW: category=VALUE
    TimeInMin: category=VALUE, compu {phys=raw for raw 0..255; unit min}
    TimeInSec: category=VALUE, compu {phys=raw for raw 0..INF; unit s}
    Tmp: category=VALUE, compu {phys=raw for raw -600..1250; unit 0.1degC}
    TotChrgCap: category=VALUE, compu {phys=raw*0.01 for raw 0..4294967295; unit Ah}
    TotChrgDischTime: category=VALUE, sw-calibration-access=READ-ONLY
    TotChrgEgy: category=VALUE, compu {phys=raw for raw 0..4294967295; unit Unitless}
    TotDchaCap: category=VALUE, compu {phys=raw*0.01 for raw 0..4294967295; unit Ah}
    TotDchaEgy: category=VALUE, compu {phys=raw for raw 0..4294967295; unit Unitless}
    TotSingleChrgEgy: category=VALUE, sw-calibration-access=READ-ONLY, compu {phys=raw*0.1 for raw 0..2047; unit KwH_1}
    TotSingleChrgEgy_ASW: category=VALUE, sw-calibration-access=READ-ONLY
    TrsmVehSpd: category=VALUE, compu {phys=raw*0.01 for raw 0..65535; unit Km/h}
    TrsmVehSpd_ASW: category=VALUE
    uint16_BMS: category=VALUE, sw-calibration-access=READ-ONLY
    uint32_BMS: category=VALUE, sw-calibration-access=READ-ONLY, compu {phys=raw for raw 0..4294967295; unit NoUint}
    uint8_BMS: category=VALUE, sw-calibration-access=READ-ONLY, compu {phys=raw for raw 0..255; unit figure}
    VehBattUSysU: category=VALUE, compu {phys=raw*0.1 for raw 0..250; unit Volt}
    VehBattUSysU_ASW: category=VALUE
    VehBattUSysUQf: category=VALUE, compu-method=GenQf1_1
    VehBattUSysUQf_ASW: category=VALUE
    VehCfgPrmBlkIDBytePosn1_int: category=VALUE, compu {phys=raw for raw 0..255; unit Unitless}, range phys 0..255, raw 0..255
    VehCfgPrmExtBlkIDBytePosn1_int: category=VALUE, compu {phys=raw for raw 0..255; unit Unitless}, range phys 0..255, raw 0..255
    VehModMngtGlbSafe1CarModSts1: category=VALUE, compu-method=CarModSts1_1
    VehModMngtGlbSafe1CarModSubtypWdCarModSubtyp: category=VALUE, compu {identical; unit Unitless}
    VehModMngtGlbSafe1Chks: category=VALUE, compu {identical; unit Unitless}
    VehModMngtGlbSafe1Cntr: category=VALUE, compu {identical; unit Unitless}
    VehModMngtGlbSafe1EgyLvlElecMai: category=VALUE, compu {identical; unit Unitless}
    VehModMngtGlbSafe1EgyLvlElecSubtyp: category=VALUE, compu {identical; unit Unitless}
    VehModMngtGlbSafe1FltEgyCnsWdSts: category=BOOLEAN, compu {0=FltEgyCns1_NoFlt, 1=FltEgyCns1_Flt; unit Unitless}
    VehModMngtGlbSafe1PwrLvlElecMai: category=VALUE, compu {identical; unit Unitless}
    VehModMngtGlbSafe1PwrLvlElecSubtyp: category=VALUE, compu {identical; unit Unitless}
    VehModMngtGlbSafe1UsgModSts: category=VALUE, compu-method=UsgModSts1_1
    VehPulseHeatAvl: category=VALUE, sw-calibration-access=READ-ONLY
    VehSpdLgtA: category=VALUE, compu {phys=raw*0.00391 for raw 0..31970; unit m/s}
    VehSpdLgtA_ASW: category=VALUE
    VehSpdLgtChks: category=VALUE, compu {identical; unit Unitless}
    VehSpdLgtChks_ASW: category=VALUE
    VehSpdLgtCntr: category=VALUE, compu {identical; unit Unitless}
    VehSpdLgtCntr_ASW: category=VALUE
    VehSpdLgtQf: category=VALUE, compu-method=GenQf1_1
    VehSpdLgtQf_ASW: category=VALUE
    VFCInfoEna: category=BOOLEAN, compu-method=EnableDisableCoding_1
    VFCVectorBECMBlockID: category=VALUE, compu {identical; unit Unitless}
    VFCVectorBECMVFCid0: category=BOOLEAN, compu {0=VFCOnOff_Off, 1=VFCOnOff_On; unit Unitless}
    VFCVectorBECMVFCid1: category=BOOLEAN, compu {0=VFCOnOff_Off, 1=VFCOnOff_On; unit Unitless}
    VFCVectorBECMVFCid{10..19}: category=BOOLEAN, compu {0=VFCOnOff_Off, 1=VFCOnOff_On; unit Unitless}
    VFCVectorBECMVFCid2: category=BOOLEAN, compu {0=VFCOnOff_Off, 1=VFCOnOff_On; unit Unitless}
    VFCVectorBECMVFCid{20..29}: category=BOOLEAN, compu {0=VFCOnOff_Off, 1=VFCOnOff_On; unit Unitless}
    VFCVectorBECMVFCid3: category=BOOLEAN, compu {0=VFCOnOff_Off, 1=VFCOnOff_On; unit Unitless}
    VFCVectorBECMVFCid{30..39}: category=BOOLEAN, compu {0=VFCOnOff_Off, 1=VFCOnOff_On; unit Unitless}
    VFCVectorBECMVFCid4: category=BOOLEAN, compu {0=VFCOnOff_Off, 1=VFCOnOff_On; unit Unitless}
    VFCVectorBECMVFCid{40..49}: category=BOOLEAN, compu {0=VFCOnOff_Off, 1=VFCOnOff_On; unit Unitless}
    VFCVectorBECMVFCid5: category=BOOLEAN, compu {0=VFCOnOff_Off, 1=VFCOnOff_On; unit Unitless}
    VFCVectorBECMVFCid{50..59}: category=BOOLEAN, compu {0=VFCOnOff_Off, 1=VFCOnOff_On; unit Unitless}
    VFCVectorBECMVFCid6: category=BOOLEAN, compu {0=VFCOnOff_Off, 1=VFCOnOff_On; unit Unitless}
    VFCVectorBECMVFCid60: category=BOOLEAN, compu {0=VFCOnOff_Off, 1=VFCOnOff_On; unit Unitless}
    VFCVectorBECMVFCid61: category=BOOLEAN, compu {0=VFCOnOff_Off, 1=VFCOnOff_On; unit Unitless}
    VFCVectorBECMVFCid{7..9}: category=BOOLEAN, compu {0=VFCOnOff_Off, 1=VFCOnOff_On; unit Unitless}
    VinBlockNr_int: category=VALUE, compu {phys=raw for raw 0..255; unit Unitless}, range phys 0..255, raw 0..255
    VINCode: category=VALUE, sw-calibration-access=READ-ONLY
    Vlt: category=VALUE, compu {phys=raw for raw 0..1000; unit V}
    WakeUpFlg: category=VALUE, compu {0=Sleep, 1=WakeUp}
    WhlMotSysCooltT: category=VALUE, compu {phys=raw-40 for raw 0..255; unit degC}
    WhlMotSysUdc: category=VALUE, compu {phys=raw*0.25 for raw 0..2044; unit Volt}
  70 x application record data type, all with category=STRUCTURE:
    AmbTEstimd
      application record element AmbTEstimdAmbTEstimd: category=VALUE, type=AmbTEstimdAmbTEstimd
      application record element AmbTEstimdQf: category=BOOLEAN, type=AmbTEstimdQf
    AmbTEstimd_ASW
      application record element AmbTEstimdAmbTEstimd_ASW: category=VALUE, type=AmbTEstimdAmbTEstimd_ASW
      application record element AmbTEstimdQf_ASW: category=BOOLEAN, type=AmbTEstimdQf_ASW
    AmbTRaw
      application record element AmbTRawAmbTVal: category=VALUE, type=AmbTRawAmbTVal
      application record element AmbTRawQly: category=VALUE, type=AmbTRawQly
    AmbTRaw_ASW
      application record element AmbTRawAmbTVal_ASW: category=VALUE, type=AmbTRawAmbTVal_ASW
      application record element AmbTRawQly_ASW: category=VALUE, type=AmbTRawQly_ASW
    CrashStsSafe
      application record element CrashStsSafeChks: category=VALUE, type=CrashStsSafeChks
      application record element CrashStsSafeCntr: category=VALUE, type=CrashStsSafeCntr
      application record element CrashStsSafeSts: category=BOOLEAN, type=CrashStsSafeSts
    EngNSafe
      4 x application record element, all with category=VALUE:
        EngNSafeEngN: type=EngNSafeEngN
        EngNSafeEngNChks: type=EngNSafeEngNChks
        EngNSafeEngNCntr: type=EngNSafeEngNCntr
        EngNSafeEngNGrdt: type=EngNSafeEngNGrdt
    EngNSafe_ASW
      4 x application record element, all with category=VALUE:
        EngNSafeEngN_ASW: type=EngNSafeEngN_ASW
        EngNSafeEngNChks_ASW: type=EngNSafeEngNChks_ASW
        EngNSafeEngNCntr_ASW: type=EngNSafeEngNCntr_ASW
        EngNSafeEngNGrdt_ASW: type=EngNSafeEngNGrdt_ASW
    EngSt1WdSts
      application record element EngSt1WdStsChks: category=VALUE, type=EngSt1WdStsChks
      application record element EngSt1WdStsCntr: category=VALUE, type=EngSt1WdStsCntr
      application record element EngSt1WdStsEngSt1WdSts: category=VALUE, type=EngSt1WdStsEngSt1WdSts
    EngT
      application record element EngTEngT: category=VALUE, type=EngTEngT
      application record element EngTQf: category=VALUE, type=EngTQf
    EngT_ASW
      application record element EngTEngT_ASW: category=VALUE, type=EngTEngT_ASW
      application record element EngTQf_ASW: category=VALUE, type=EngTQf_ASW
    HvBattCellTInfo
      6 x application record element, all with category=VALUE:
        HvBattCellTInfoHvBattSnsrT: type=HvBattCellTInfoHvBattSnsrT
        HvBattCellTInfoHvBattTMax: type=HvBattCellTInfoHvBattTMax
        HvBattCellTInfoHvBattTMin: type=HvBattCellTInfoHvBattTMin
        HvBattCellTInfoHvBattTSnsrNr: type=HvBattCellTInfoHvBattTSnsrNr
        HvBattCellTInfoHvTempSnsrTMaxsSerlNr: type=HvBattCellTInfoHvTempSnsrTMaxsSerlNr
        HvBattCellTInfoHvTempSnsrTMinSerlNr: type=HvBattCellTInfoHvTempSnsrTMinSerlNr
    HvBattCellUInfo
      4 x application record element, all with category=VALUE:
        HvBattCellUInfoU{1..4}: type=HvBattCellUInfoU{1..4}
    HvBattThermInfoInFuture: sw-calibration-access=READ-WRITE
      6 x application record element, all with category=VALUE:
        HvBattThermInfoInFuturePwrAtTime: type=HvBattThermInfoInFuturePwrAtTime
        HvBattThermInfoInFutureSequenceNo: type=HvBattThermInfoInFutureSequenceNo
        HvBattThermInfoInFutureTempAtTime: type=HvBattThermInfoInFutureTempAtTime
        HvBattThermInfoInFutureThermModAtTime: type=HvBattThermInfoInFutureThermModAtTime
        HvBattThermInfoInFutureTime: type=HvBattThermInfoInFutureTime
        HvBattThermInfoInFutureVersionNo: type=HvBattThermInfoInFutureVersionNo
    HvBattThermInfoInFuture_ASW: sw-calibration-access=READ-WRITE
      6 x application record element, all with category=VALUE:
        HvBattThermInfoInFuturePwrAtTime_ASW: type=HvBattThermInfoInFuturePwrAtTime_ASW
        HvBattThermInfoInFutureSequenceNo_ASW: type=HvBattThermInfoInFutureSequenceNo_ASW
        HvBattThermInfoInFutureTempAtTime_ASW: type=HvBattThermInfoInFutureTempAtTime_ASW
        HvBattThermInfoInFutureThermModAtTime_ASW: type=HvBattThermInfoInFutureThermModAtTime_ASW
        HvBattThermInfoInFutureTime_ASW: type=HvBattThermInfoInFutureTime_ASW
        HvBattThermInfoInFutureVersionNo_ASW: type=HvBattThermInfoInFutureVersionNo_ASW
    HvSysRlySts
      application record element HvSysRlyStsChks: category=VALUE, type=HvSysRlyStsChks
      application record element HvSysRlyStsCntr: category=VALUE, type=HvSysRlyStsCntr
      application record element HvSysRlyStsHvSysRlySts: category=VALUE, type=HvSysRlyStsHvSysRlySts
    strAbsltCp: sw-calibration-access=READ-ONLY
      application record element ahAbsltCpToBsw: category=VALUE, type=AhCp
      application record element Chks: category=VALUE, type=Chks
    strACCH: sw-calibration-access=READ-ONLY
      application record element tiTiToEndToBsw: category=VALUE, type=MntnBattTTimin
      application record element stChrgnToTarSocrToBsw: category=VALUE, type=AcChrgnToTar
      application record element Chks: category=VALUE, type=Chks
    strAFERest: sw-calibration-access=READ-ONLY
      application record element nrAFERest: category=ARRAY, type=nrAFERstAry
      application record element Chks: category=VALUE, type=Chks
    strBalFinishTimes: sw-calibration-access=READ-ONLY
      application record element nrBalFinishTimesToBsw: category=VALUE, type=uint16_BMS
      application record element Chks: category=VALUE, type=Chks
    strBalTiCalcMod: sw-calibration-access=READ-ONLY
      application record element stBalTiCalcModeToBsw: category=VALUE, type=BalTiCalcMod
      application record element Chks: category=VALUE, type=Chks
    strBalTotTime: sw-calibration-access=READ-ONLY
      application record element tiBalTotTimeToBsw: category=VALUE, type=uint32_BMS
      application record element Chks: category=VALUE, type=Chks
    strbEKFdisabled: sw-calibration-access=READ-ONLY
      application record element bEKFdisabledToBsw: category=VALUE, type=boolean
      application record element Chks: category=VALUE, type=Chks
    strBookChrgTarValLnr: sw-calibration-access=READ-ONLY
      application record element percBookChrgTarValLnrToBsw: category=VALUE, type=uint16_BMS
      application record element Chks: category=VALUE, type=Chks
    strCANCrashFlt: sw-calibration-access=READ-ONLY
      application record element bCANCrashFlt: category=VALUE, type=boolean
      application record element Chks: category=VALUE, type=Chks
    strCarCfgInVal: sw-calibration-access=READ-ONLY
      application record element nrCarCfgInValPosn: category=ARRAY, type=CfgInValPosn
      application record element nrCarCfgInValVal: category=ARRAY, type=CarCfgInValVal
      application record element Chks: category=VALUE, type=Chks
    strCpCalcnIniSoc: sw-calibration-access=READ-ONLY
      application record element percCpCalcnIniSocToBsw: category=ARRAY, type=SocPercAry
      application record element Chks: category=VALUE, type=Chks
    strCpCalcnStrt: sw-calibration-access=READ-ONLY
      application record element bCpCalcnStrtToBsw: category=VALUE, type=boolean
      application record element Chks: category=VALUE, type=Chks
    strCpExt: sw-calibration-access=READ-ONLY
      application record element ahCpExtToBsw: category=ARRAY, type=AhCpAry
      application record element Chks: category=VALUE, type=Chks
    strCpMeasTot: sw-calibration-access=READ-ONLY
      application record element nrCpMeasTotToBsw: category=VALUE, type=Cntr
      application record element Chks: category=VALUE, type=Chks
    strCRAHOK: sw-calibration-access=READ-ONLY
      application record element bReadCRSHOKFlg: category=VALUE, type=boolean
      application record element Chks: category=VALUE, type=Chks
    strCrashEvent: sw-calibration-access=READ-ONLY
      application record element bCrashEventFlg: category=VALUE, type=boolean
      application record element Chks: category=VALUE, type=Chks
    strCurrtInA: sw-calibration-access=READ-ONLY
      application record element iZeroDriftCurrtToBsw: category=VALUE, type=CurrtInA
      application record element Chks: category=VALUE, type=Chks
    strDisKal: sw-calibration-access=READ-ONLY
      13 x application record element, all with category=VALUE:
        nrCalcnNumHiToBsw: type=Cntr
        nrCalcnNumLoToBsw: type=Cntr
        vSumVoltHiToBsw: type=Vlt
        vSumVoltLoToBsw: type=Vlt
        iSumCurHiToBsw: type=CurrtInA
        iSumCurLoToBsw: type=CurrtInA
        iBndryCurrtToBsw: type=MultiCurrt
        tSumTemToBsw: type=Tmp
        facRateToBsw: type=Factor
        percSumSocHiToBsw: type=Perc
        percSumSocLoToBsw: type=Perc
        bPatchVtgStrtFlgToBsw: type=ActvFlg
        Chks: type=Chks
    strElecDrvLinePrm: sw-calibration-access=READ-ONLY
      application record element nrElecDrvLinePrmAvlArbd: category=VALUE, type=uint8_BMS
      application record element Chks: category=VALUE, type=Chks
    strElecVehInletPrm: sw-calibration-access=READ-ONLY
      application record element nrElecVehInletPrmAvlArbd: category=VALUE, type=uint8_BMS
      application record element Chks: category=VALUE, type=Chks
    strfacKalP: sw-calibration-access=READ-ONLY
      application record element facKalPToBsw: category=ARRAY, type=KalPAry
      application record element Chks: category=VALUE, type=Chks
    strFidStopSafely: sw-calibration-access=READ-ONLY
      application record element bFidStopSafely: category=VALUE, type=boolean
      application record element Chks: category=VALUE, type=Chks
    strFlg: sw-calibration-access=READ-ONLY
      application record element bIntegrityTestFlgToBsw: category=VALUE, type=ActvFlg
      application record element Chks: category=VALUE, type=Chks
    strHvBattOptmzHintForSoc: sw-calibration-access=READ-ONLY
      application record element bHvBattOptmzHintFlag: category=VALUE, type=boolean
      application record element cAhAccum4TrgFullChrgCorr: category=VALUE, type=uint16_BMS
      application record element Chks: category=VALUE, type=Chks
    strHvBattSoc: sw-calibration-access=READ-ONLY
      application record element percHvBattSocToNrm: category=VALUE, type=Perc
      application record element Chks: category=VALUE, type=Chks
    strHvNegRlyCur: sw-calibration-access=READ-ONLY
      application record element iHvNegRlyCurAry: category=ARRAY, type=RlyCurAry
      application record element Chks: category=VALUE, type=Chks
    strHvPosRlyCur: sw-calibration-access=READ-ONLY
      application record element iHvPosRlyCurAry: category=ARRAY, type=RlyCurAry
      application record element Chks: category=VALUE, type=Chks
    strHVRlyRemLife: sw-calibration-access=READ-ONLY
      application record element nrHVPosRlyRemLife: category=VALUE, type=uint32_BMS
      application record element nrHVNegRlyRemLife: category=VALUE, type=uint32_BMS
      application record element Chks: category=VALUE, type=Chks
    strHWCrashFlt: sw-calibration-access=READ-ONLY
      application record element bHWCrashFltFlg: category=VALUE, type=boolean
      application record element Chks: category=VALUE, type=Chks
    strPrecRlyClsToOpen: sw-calibration-access=READ-ONLY
      application record element iPrecRlyClsToOpenToBsw: category=VALUE, type=CurrtInA
      application record element Chks: category=VALUE, type=Chks
    strRelCp: sw-calibration-access=READ-ONLY
      application record element ahRelCpToBsw: category=VALUE, type=AhCp
      application record element Chks: category=VALUE, type=Chks
    strRlyClsToOpen: sw-calibration-access=READ-ONLY
      application record element iMainNegRlyClsToOpenToBsw: category=VALUE, type=CurrtInA
      application record element iMainPosRlyClsToOpenToBsw: category=VALUE, type=CurrtInA
      application record element Chks: category=VALUE, type=Chks
    strRlyOpenTimes: sw-calibration-access=READ-ONLY
      7 x application record element, all with category=VALUE:
        nrHVPosRlyOpenFst: type=uint8_BMS
        nrHVPosRlyOpenSnd: type=uint32_BMS
        nrHVPosRlyOpenTrd: type=uint32_BMS
        nrHVNegRlyOpenFst: type=uint8_BMS
        nrHVNegRlyOpenSnd: type=uint32_BMS
        nrHVNegRlyOpenTrd: type=uint32_BMS
        Chks: type=Chks
    strRlyVltDrpAbnrmCnt: sw-calibration-access=READ-ONLY
      application record element RlyVltDrpAbnrmCntToBsw: category=VALUE, type=uint32_BMS
      application record element Chks: category=VALUE, type=Chks
    strRTC: sw-calibration-access=READ-ONLY
      9 x application record element, all with category=VALUE:
        tiRTCSecToBsw: type=RTCTi
        tiRTCMinToBsw: type=RTCTi
        tiRTCHrToBsw: type=RTCTi
        tiRTCDayToBsw: type=RTCTi
        tiRTCMthToBsw: type=RTCTi
        tiRTCYearToBsw: type=RTCTi
        tiRunTotTiToBsw: type=RTCTi
        stiSleepTotTiToBsw: type=RTCTi
        Chks: type=Chks
    strShutCalAByUDS: sw-calibration-access=READ-ONLY
      application record element ShutCalAByUDSToBsw: category=VALUE, type=float32_BMS_2
    strShutCalBByUDS: sw-calibration-access=READ-ONLY
      application record element ShutCalBByUDSToBsw: category=VALUE, type=float32_BMS_2
    strShutCalCByUDS: sw-calibration-access=READ-ONLY
      application record element ShutCalCByUDSToBsw: category=VALUE, type=float32_BMS_2
    strShutCalR25ByUDS: sw-calibration-access=READ-ONLY
      application record element ShutCalR25ByUDSToBsw: category=VALUE, type=uint16_BMS
    strShutDown: sw-calibration-access=READ-ONLY
      10 x application record element:
        percMinCellSohToBsw: category=VALUE, type=Perc
        percSohPwrCdnToBsw: category=VALUE, type=Perc
        percSohEgyCdnToBsw: category=ARRAY, type=SohPercAry
        percMaxCellSohToBsw: category=VALUE, type=Perc
        percAvgCellSohToBsw: category=VALUE, type=Perc
        rIsoFinalCalcValRToBsw: category=VALUE, type=Rval
        dPakCapSohToBsw: category=VALUE, type=Perc
        dPakResSohToBsw: category=VALUE, type=Perc
        oPakResToBsw: category=VALUE, type=PakRes
        Chks: category=VALUE, type=Chks
    strSocPercAry: sw-calibration-access=READ-ONLY
      application record element percCellSocToBsw: category=ARRAY, type=SocPercAry
      application record element Chks: category=VALUE, type=Chks
    strSOCRangeLearn: sw-calibration-access=READ-ONLY
      4 x application record element, all with category=VALUE:
        percChrgAvgSOC: type=uint16_BMS
        nrChrgFinsTimes: type=uint8_BMS
        percTagtSOC: type=uint16_BMS
        Chks: type=Chks
    strSocStorage: sw-calibration-access=READ-ONLY
      7 x application record element, all with category=VALUE:
        tiStaticAccumTiToNrm: type=TimeInSec
        iCurrMultiAvgToNrm: type=CurrtInA
        bChrgFullToNrm: type=boolean
        bCellURebndDirToNrm: type=boolean
        uPackUDrop1ToNrm: type=Vlt
        uPackUDrop2ToNrm: type=Vlt
        Chks: type=Chks
    strSoeStorage: sw-calibration-access=READ-ONLY
      10 x application record element, all with category=VALUE:
        ahChrgFbCpTotToBsw: type=Egyah
        ahChrgCpTotToBsw: type=Egyah
        ahDchaCpTotToBsw: type=Egyah
        whDchaEgyAvlToBsw: type=Egywh_uint32
        whChrgEgyAvlToBsw: type=Egywh_uint32
        whChrgFbEgyTotToBsw: type=Egywh_uint32
        whDchaEgyTotToBsw: type=Egywh_uint32
        whChrgEgyTotToBsw: type=Egywh_uint32
        tAbtTToBsw: type=Tmp
        Chks: type=Chks
    strTimePeriod: sw-calibration-access=READ-ONLY
      8 x application record element:
        tiTimeRemainSecToBsw: category=ARRAY, type=TimeInSecAry
        ahAbsltCpToBsw: category=ARRAY, type=AhCpAry
        ahRelCpToBsw: category=ARRAY, type=AhCpAry
        percCpCalcnIniSocToBsw: category=ARRAY, type=SocPercAry
        ahCpExtToBsw: category=ARRAY, type=AhCpAry
        nrCpMeasTotToBsw: category=VALUE, type=Cntr
        bCpCalcnStrtToBsw: category=ARRAY, type=FlgAry
        Chks: category=VALUE, type=Chks
    strTimeRemain: sw-calibration-access=READ-ONLY
      application record element tiTimeRemainSecToBsw: category=ARRAY, type=CpInmAsAry
      application record element Chks: category=VALUE, type=Chks
    strTotChrgDischTime: sw-calibration-access=READ-ONLY
      application record element minTotChrgDischTime: category=VALUE, type=uint16_BMS
      application record element Chks: category=VALUE, type=Chks
    strTotSingleChrgEgy: sw-calibration-access=READ-ONLY
      application record element whOnePlgChrgEgyTot: category=VALUE, type=uint32_BMS
      application record element Chks: category=VALUE, type=Chks
    strVINCode: sw-calibration-access=READ-ONLY
      application record element nrVINCodeAry: category=ARRAY, type=VINCodeAry
      application record element Chks: category=VALUE, type=Chks
    VehBattU
      application record element VehBattUSysU: category=VALUE, type=VehBattUSysU
      application record element VehBattUSysUQf: category=VALUE, type=VehBattUSysUQf
    VehBattU_ASW
      application record element VehBattUSysU_ASW: category=VALUE, type=VehBattUSysU_ASW
      application record element VehBattUSysUQf_ASW: category=VALUE, type=VehBattUSysUQf_ASW
    VehModMngtGlbSafe1
      10 x application record element:
        VehModMngtGlbSafe1CarModSts1: category=VALUE, type=VehModMngtGlbSafe1CarModSts1
        VehModMngtGlbSafe1CarModSubtypWdCarModSubtyp: category=VALUE, type=VehModMngtGlbSafe1CarModSubtypWdCarModSubtyp
        VehModMngtGlbSafe1Chks: category=VALUE, type=VehModMngtGlbSafe1Chks
        VehModMngtGlbSafe1Cntr: category=VALUE, type=VehModMngtGlbSafe1Cntr
        VehModMngtGlbSafe1EgyLvlElecMai: category=VALUE, type=VehModMngtGlbSafe1EgyLvlElecMai
        VehModMngtGlbSafe1EgyLvlElecSubtyp: category=VALUE, type=VehModMngtGlbSafe1EgyLvlElecSubtyp
        VehModMngtGlbSafe1FltEgyCnsWdSts: category=BOOLEAN, type=VehModMngtGlbSafe1FltEgyCnsWdSts
        VehModMngtGlbSafe1PwrLvlElecMai: category=VALUE, type=VehModMngtGlbSafe1PwrLvlElecMai
        VehModMngtGlbSafe1PwrLvlElecSubtyp: category=VALUE, type=VehModMngtGlbSafe1PwrLvlElecSubtyp
        VehModMngtGlbSafe1UsgModSts: category=VALUE, type=VehModMngtGlbSafe1UsgModSts
    VehSpdLgt
      4 x application record element, all with category=VALUE:
        VehSpdLgtA: type=VehSpdLgtA
        VehSpdLgtChks: type=VehSpdLgtChks
        VehSpdLgtCntr: type=VehSpdLgtCntr
        VehSpdLgtQf: type=VehSpdLgtQf
    VehSpdLgt_ASW
      4 x application record element, all with category=VALUE:
        VehSpdLgtA_ASW: type=VehSpdLgtA_ASW
        VehSpdLgtChks_ASW: type=VehSpdLgtChks_ASW
        VehSpdLgtCntr_ASW: type=VehSpdLgtCntr_ASW
        VehSpdLgtQf_ASW: type=VehSpdLgtQf_ASW
    VFCVectorBECM
      63 x application record element:
        VFCVectorBECMBlockID: category=VALUE, type=VFCVectorBECMBlockID
        VFCVectorBECMVFCid{0..61}: category=BOOLEAN, type=VFCVectorBECMVFCid{0..61}
package /BMS_ASW/CompuMethods
  compu method AcMod: 0=AcMod_init (CompuScale), 1=AcMod_Standby (CompuScale), 2=AcMod_Ready (CompuScale), 3=AcMod_PreHeat (CompuScale), 4=AcMod_PreChrg (CompuScale), 5=AcMod_HeatStrt (CompuScale), 6=AcMod_HeatStop (CompuScale), 7=AcMod_ChrgnStrt (CompuScale), 8=AcMod_ChrgnStop (CompuScale), 9=AcMod_ChrgnDi (CompuScale), 10=AcMod_Deactvn (CompuScale)
  compu method HVILSts: 0=HVIL_Default_C, 1=HVIL_Normal_C, 2=HVIL_HighimpdFlt_C, 3=HVIL_OpenFlt_C, 4=HVIL_ShoPwrFlt_C, 5=HVIL_ShoGNDFlt_C, 6=HVIL_CurrSrcFlt_C, 7=HVIL_CurrSrcHiFlt_C
  compu method MntnBattTFbSts: 0=MntnBattTFbSts_Default (CompuScale), 1=MntnBattTFbSts_Success (CompuScale), 2=MntnBattTFbSts_Fail (CompuScale), 3=MntnBattTFbSts_Finish (CompuScale)
  compu method PulseHeatTsts: 0=PulseHeatTsts_NoReq, 1=PulseHeatTsts_Red, 2=PulseHeatTsts_Yellow, 3=PulseHeatTsts_Blue
package /BMS_ASW/DaseType
  7 x base type, all with category=FIXED_LENGTH:
    boolean_BMS: base-type-size=1, base-type-encoding=BOOLEAN, native-declaration=boolean
    float32_BMS: base-type-size=32, base-type-encoding=IEEE754, native-declaration=float32
    sint16_BMS: base-type-size=16, base-type-encoding=2C, native-declaration=sint16
    sint32_BMS: base-type-size=32, base-type-encoding=2C, native-declaration=sint32
    uint16_BMS: base-type-size=16, base-type-encoding=NONE, native-declaration=uint16
    uint32_BMS: base-type-size=32, base-type-encoding=NONE, native-declaration=uint32
    uint8_BMS: base-type-size=8, base-type-encoding=NONE, native-declaration=uint8
package /BMS_ASW/EnumCompuMethods
  compu method CM_SetEventStatus: 0=PASSED (DEM_EVENT_STATUS_PASSED), 1=FAILED (DEM_EVENT_STATUS_FAILED), 2=PREPASSED (DEM_EVENT_STATUS_PREPASSED), 3=PREFAILED (DEM_EVENT_STATUS_PREFAILED), 4=FDC_THRESHOLD_REACHED (DEM_EVENT_STATUS_FDC_THRESHOLD_REACHED), 5=PASSED_CONDITIONS_NOT_FULFILLED (DEM_EVENT_STATUS_PASSED_CONDITIONS_NOT_FULFILLED), 6=FAILED_CONDITIONS_NOT_FULFILLED (DEM_EVENT_STATUS_FAILED_CONDITIONS_NOT_FULFILLED), 7=PREPASSED_CONDITIONS_NOT_FULFILLED (DEM_EVENT_STATUS_PREPASSED_CONDITIONS_NOT_FULFILLED), 8=PREFAILED_CONDITIONS_NOT_FULFILLED (DEM_EVENT_STATUS_PREFAILED_CONDITIONS_NOT_FULFILLED), 255=UNDEFINED (DEM_EVENT_STATUS_UNDEFINED)
  compu method DCChgStopSTS: 0=stDefault, 1=stFullStop, 2=stVCUStop, 3=stBMSStop, 4=stUserStop, 5=stChargerStop, 6=stChPgStop, 7=stConFStop
  compu method DCChrgnHndlSts: 0=Disconnected, 1=ConnectedWithoutPower, 2=PowerAvailableButNotActivated, 3=ConnectedWithPower, 4=Init, 5=Fault
  compu method DCChrgSt_ASW: 0=Idle, 1=Prestart, 2=Charging, 3=DCCharingFaultvehicleside, 4=DCCharingFaultChargersideTempFault, 5=DCCharingFaultChargersideConnectedFault, 6=DCCharingFaultChargersideOtherFault, 7=DCCharingFaultChargersideEmergencyFault, 8=DCCharingFaultChargersideCommucationFault, 9=Bookcharging, 10=Shuntdown, 11=Heating, 12=SuperCharging, 13=SuperChargingEnd
  compu method FastChrgnLEDIndctn: 0=FastChrgnLEDIndctn_Default, 1..4=FastChrgnLEDIndctn_Green1..FastChrgnLEDIndctn_Green4, 5=FastChrgnLEDIndctn_Red, 6=FastChrgnLEDIndctn_Green5, 7=FastChrgnLEDIndctn_Reserved
  compu method IsoCrshSts: 0=IsoCrshSts_Idle, 1=IsoCrshSts_Evaluating, 2=IsoCrshSts_NOK, 3=IsoCrshSts_OK
  compu method IsoFltSts: 0=IsoDefault, 1=IsoSlfChkFlt, 2=IsoHVOnLevelOneFlt, 3=IsoHVOnLevelTwoFlt, 4=IsoHVOffLevelOneFlt, 5=IsoHVOffLevelTwoFlt, 6=IsoNormal, 7=IsoRstFlt, 8=IsoQuckTstFlt, 9=IsoChrgingLevelOneFlt, 10=IsoChrgingLevelTwoFlt, 11=IsoVltSmplVldFlt
  compu method IsoSts: 0=IsoSlfChkInit, 1=IsoSlfChkFlt, 2=IsoQuickTest, 3=IsoInit, 4=IsoCalMod, 5=IsoCalU1, 6=IsoCalU2, 7=IsoCalNP
  compu method LoDCChrgSt: 0=ChgIdle, 1=ChmRcv, 2=ChmTout, 3=CrmRcv, 4=CrmTout, 5=CrmRecog, 6=CrmReTout, 7=CmlRcv, 8=CmlTout, 9=PMatch, 10=PMatTout, 11=ChgRly, 12=CroRcv, 13=CroTout, 14=CroRedy, 15=CroRedyTout, 16=DCChrging, 17=CcsTout, 18=ChrgStop, 19=CstRcv, 20=CstTout, 21=CsdTout, 22=ChrgFin, 23=AbtByUsr, 24=ChrgTOut, 25=ReCon, 26=ReConFail, 27=ChrgOver
  compu method PCHMSts: 0=Init, 1=Standby, 2=ReqNegRlyCls, 3=ReqPrecRlyCls, 4=PrecRetry, 5=OvCurr, 6=PrecFinshd, 7=PrecFaild
  compu method SocOperMod: 0=Reserve, 1=stLoadNVM, 2=stNVMLoaded, 3=stIni, 4=stIniFinshd, 5=stIdle, 6=stCnt, 7=stSocCheck, 8=stCpEstimStrt, 9=stCpEstim, 10=stForcedIni, 11=stSocCheckFinshd, 12=stSocReIni, 13=stCpEstimStrted, 14=stCpEstimFinshd
  compu method THMDOperMod: 0=Idle, 1=ThermalBalancing, 2=PassiveHeating, 3=ActiveHeating, 4=PassiveCooling, 5=ActiveCooling, 6=CombinedCooling
package /BMS_ASW/ImplementationDataTypes
  582 x impl type:
    AcChrgEgywh: implementation-data-type=uint32_BMS, type-emitter=RTE
    AcChrgnSts: compu {0=AcChrg_Start, 1=AcChrg_Finish}, implementation-data-type=uint8_BMS, type-emitter=RTE
    AcChrgnToTar: implementation-data-type=uint16_BMS, type-emitter=RTE
    AcChrgPwrw: implementation-data-type=uint32_BMS, type-emitter=RTE
    AcMod: compu-method=AcMod, implementation-data-type=uint8_BMS, type-emitter=RTE
    AcReqCurr: implementation-data-type=uint16_BMS, type-emitter=RTE
    AcReqVlt: implementation-data-type=uint16_BMS, type-emitter=RTE
    ActvFlg: compu {0=ActvFlgFalse, 1=ActvFlgTrue}, implementation-data-type=boolean_BMS, type-emitter=RTE
    AfeMdCtrl: implementation-data-type=uint8_BMS, type-emitter=RTE
    AfeStsFd: implementation-data-type=uint8_BMS, type-emitter=RTE
    AhCp: implementation-data-type=sint16_BMS, type-emitter=RTE
    AhCpAry: category=ARRAY, sw-calibration-access=READ-ONLY, type-emitter=RTE
      element Element: array-size=120, array-size-semantics=FIXED-SIZE, range raw -32768..32767, implementation-data-type=sint16_BMS
    AmbTEstimd: category=STRUCTURE
      element AmbTEstimdAmbTEstimd: implementation-data-type=AmbTEstimdAmbTEstimd
      element AmbTEstimdQf: implementation-data-type=AmbTEstimdQf
    AmbTEstimd_ASW: category=STRUCTURE
      element AmbTEstimdAmbTEstimd_ASW: implementation-data-type=AmbTEstimdAmbTEstimd_ASW
      element AmbTEstimdQf_ASW: implementation-data-type=AmbTEstimdQf_ASW
    AmbTEstimdAmbTEstimd: category=VALUE, base-type=uint16_BMS
    AmbTEstimdAmbTEstimd_ASW: category=VALUE, base-type=float32_BMS
    AmbTEstimdQf: category=VALUE, base-type=uint8_BMS, compu {0=HvacTIfQf_SnsrDataNotOk, 1=HvacTIfQf_SnsrDataOk; unit Unitless}
    AmbTEstimdQf_ASW: category=VALUE, base-type=uint8_BMS
    AmbTRaw: category=STRUCTURE
      element AmbTRawAmbTVal: implementation-data-type=AmbTRawAmbTVal
      element AmbTRawQly: implementation-data-type=AmbTRawQly
    AmbTRaw_ASW: category=STRUCTURE
      element AmbTRawAmbTVal_ASW: implementation-data-type=AmbTRawAmbTVal_ASW
      element AmbTRawQly_ASW: implementation-data-type=AmbTRawQly_ASW
    AmbTRawAmbTVal: category=VALUE, base-type=uint16_BMS
    AmbTRawAmbTVal_ASW: category=VALUE, base-type=float32_BMS
    AmbTRawQly: category=VALUE, base-type=uint8_BMS, compu-method=GenQf1_1
    AmbTRawQly_ASW: category=VALUE, base-type=uint8_BMS
    AswCellTmp: category=VALUE, base-type=sint16_BMS, sw-calibration-access=READ-ONLY, type-emitter=RTE
    AswCellTmpAry: category=ARRAY, sw-calibration-access=READ-ONLY, type-emitter=RTE
      element AswCellTmpAry: array-size=40, array-size-semantics=FIXED-SIZE, implementation-data-type=AswCellTmp
    AswCellVlt: implementation-data-type=uint16_BMS, type-emitter=RTE
    AswCellVltAry: category=ARRAY, sw-calibration-access=READ-ONLY
      element AswCellVltAry: array-size=120, array-size-semantics=FIXED-SIZE, implementation-data-type=uint16_BMS
    AswCscTmpAry: category=ARRAY, sw-calibration-access=READ-ONLY, type-emitter=RTE
      element Element: array-size=40, array-size-semantics=FIXED-SIZE, implementation-data-type=AswCscTmp
    AswCscVoltAry: category=ARRAY, sw-calibration-access=READ-ONLY, type-emitter=RTE
      element Element: array-size=40, array-size-semantics=FIXED-SIZE, implementation-data-type=float32_BMS
    BalOperMod: implementation-data-type=uint8_BMS
    BalTiCalcMod: implementation-data-type=uint8_BMS
    BATIOperMod: implementation-data-type=uint8_BMS
    BattClimaPwr: implementation-data-type=float32_BMS, type-emitter=RTE
    BclCurrReq: implementation-data-type=float32_BMS, type-emitter=RTE
    BclVoltReq: implementation-data-type=float32_BMS, type-emitter=RTE
    BcpBattNomEgy: implementation-data-type=float32_BMS, invalid-value=0, type-emitter=RTE
    BecmDcChgRlyCmd: implementation-data-type=uint8_BMS, type-emitter=RTE
    BECMdevelpsignalgroup1: category=ARRAY
      element Element: array-size=8, array-size-semantics=FIXED-SIZE, implementation-data-type=BECMdevelpsignalgroup1ElementType
    BECMdevelpsignalgroup1ElementType: category=VALUE, base-type=uint8_BMS
    BECMdevelpsignalgroup2: category=ARRAY
      element Element: array-size=8, array-size-semantics=FIXED-SIZE, implementation-data-type=BECMdevelpsignalgroup2ElementType
    BECMdevelpsignalgroup2ElementType: category=VALUE, base-type=uint8_BMS
    BECMdevelpsignalgroup3: category=ARRAY
      element Element: array-size=8, array-size-semantics=FIXED-SIZE, implementation-data-type=BECMdevelpsignalgroup3ElementType
    BECMdevelpsignalgroup3ElementType: category=VALUE, base-type=uint8_BMS
    BECMdevelpsignalgroup4: category=ARRAY
      element Element: array-size=8, array-size-semantics=FIXED-SIZE, implementation-data-type=BECMdevelpsignalgroup4ElementType
    BECMdevelpsignalgroup4ElementType: category=VALUE, base-type=uint8_BMS
    BkpOfDstTrvld: category=VALUE, base-type=uint32_BMS
    BkpOfDstTrvld_ASW: implementation-data-type=uint32
    BMSSts: implementation-data-type=uint8_BMS
    BookChrgTarValLnr: category=VALUE, base-type=uint16_BMS
    BookChrgTarValLnr_ASW: implementation-data-type=float32_BMS, type-emitter=RTE
    boolean_BMS: category=VALUE, base-type=boolean_BMS, range raw 0..1, type-emitter=RTE  # boolean has the value space required to support the mathematical concept of binary-valued logic: {true, false}.
    BpsOverAbsThresholdFlgH: category=VALUE, base-type=boolean_BMS, type-emitter=RTE
    BpsOverAbsThresholdFlgH_ASW: category=VALUE, base-type=boolean_BMS, type-emitter=RTE
    BpsOverAbsThresholdFlgL: category=VALUE, base-type=boolean_BMS, type-emitter=RTE
    BpsOverAbsThresholdFlgL_ASW: category=VALUE, base-type=boolean_BMS, type-emitter=RTE
    BpsOverSlopeThresholdFlgH: category=VALUE, base-type=boolean_BMS, type-emitter=RTE
    BpsOverSlopeThresholdFlgH_ASW: category=VALUE, base-type=boolean_BMS, type-emitter=RTE
    BpsOverSlopeThresholdFlgL: category=VALUE, base-type=boolean_BMS, type-emitter=RTE
    BpsOverSlopeThresholdFlgL_ASW: category=VALUE, base-type=boolean_BMS, type-emitter=RTE
    BpsPressureDataH: category=VALUE, base-type=uint16_BMS, type-emitter=RTE
    BpsPressureDataH_ASW: category=VALUE, base-type=float32_BMS, type-emitter=RTE
    BpsPressureDataL: category=VALUE, base-type=uint16_BMS, type-emitter=RTE
    BpsPressureDataL_ASW: category=VALUE, base-type=float32_BMS, type-emitter=RTE
    BrmSysRateCp: implementation-data-type=float32_BMS, invalid-value=0, type-emitter=RTE
    BswCellTmp: category=VALUE, base-type=uint16_BMS, sw-calibration-access=READ-ONLY, type-emitter=RTE
    BswCellTmpAry: category=ARRAY, sw-calibration-access=READ-ONLY, type-emitter=RTE
      element BswCellTmpAry: array-size=40, array-size-semantics=FIXED-SIZE, implementation-data-type=uint16_BMS
    BswCellVlt: implementation-data-type=uint16_BMS, type-emitter=RTE
    BswCellVltAry: category=ARRAY, sw-calibration-access=READ-ONLY
      element BswCellVltAry: array-size=120, array-size-semantics=FIXED-SIZE, implementation-data-type=uint16_BMS
    BswCscVolt: category=VALUE, base-type=float32_BMS, sw-calibration-access=READ-ONLY, type-emitter=RTE
    BswCscVoltAry: category=ARRAY, sw-calibration-access=READ-ONLY, type-emitter=RTE
      element Element: array-size=40, array-size-semantics=FIXED-SIZE, implementation-data-type=uint32_BMS
    CarCfgInValVal: category=ARRAY, sw-calibration-access=READ-ONLY, type-emitter=RTE
      element CarCfgInValVal: array-size=2, array-size-semantics=FIXED-SIZE, implementation-data-type=uint8_BMS
    CarCfgModSts: compu {0=VCG_stDftSts, 1=VCG_stValCfgSts, 2=VCG_stBulkSts; unit figure}, implementation-data-type=uint8_BMS, type-emitter=RTE
    CarTiGlb: category=VALUE, base-type=CarTiGlb_2
    CarTiGlb_ASW: category=VALUE, base-type=float32_BMS
    CeBRActvDIDAry: category=ARRAY, sw-calibration-access=READ-ONLY, type-emitter=RTE
      element Element: array-size=4, array-size-semantics=FIXED-SIZE, implementation-data-type=uint32_BMS
    CellmAh: implementation-data-type=float32_BMS, type-emitter=RTE
    CellmAhAry: category=ARRAY, sw-calibration-access=READ-ONLY
      element CellmAhAry: array-size=120, array-size-semantics=FIXED-SIZE, implementation-data-type=float32_BMS
    cellsocperc: implementation-data-type=sint16_BMS, type-emitter=RTE
    CellTVldAry: category=ARRAY, sw-calibration-access=READ-ONLY
      element CellTVldAry: array-size=40, array-size-semantics=FIXED-SIZE, implementation-data-type=boolean_BMS
    CellUMax: category=VALUE, base-type=uint16_BMS
    CellUMaxId: category=VALUE, base-type=HvBattNr_1
    CellUMaxLim: category=VALUE, base-type=uint16_BMS
    CellUMin: category=VALUE, base-type=uint16_BMS
    CellUMinId: category=VALUE, base-type=HvBattNr_1
    CellUSamplBrkAry: category=ARRAY, sw-calibration-access=READ-ONLY, type-emitter=RTE
      element CellUSamplBrkAry: array-size=120, array-size-semantics=FIXED-SIZE, implementation-data-type=boolean_BMS
    CellVlt: category=VALUE, base-type=uint16_BMS, sw-calibration-access=READ-ONLY, type-emitter=RTE
    CellVoltVldAry: category=ARRAY, sw-calibration-access=READ-ONLY
      element CellVoltVldAry: array-size=120, array-size-semantics=FIXED-SIZE, implementation-data-type=boolean_BMS
    CfgInValPosn: category=ARRAY, sw-calibration-access=READ-ONLY, type-emitter=RTE
      element CfgInValPosn: array-size=2, array-size-semantics=FIXED-SIZE, implementation-data-type=uint16_BMS
    CfgPrmVal: category=VALUE, base-type=uint8_BMS, sw-calibration-access=READ-ONLY, type-emitter=RTE
    Chks: category=VALUE, base-type=uint16_BMS, sw-calibration-access=READ-ONLY, type-emitter=RTE
    ChrgEquipIDc: category=VALUE, base-type=uint16_BMS
    ChrgEquipIDcL2: implementation-data-type=uint16_BMS, type-emitter=RTE
    ChrgEquipIDcL2_ASW: implementation-data-type=float32_BMS, type-emitter=RTE
    ChrgnSts: range raw 0..7, implementation-data-type=uint8
    ChrgSts: implementation-data-type=uint8_BMS
    CM_SetEventStatus: compu-method=CM_SetEventStatus, implementation-data-type=uint8_BMS, type-emitter=RTE
    Cmd: compu {0=Open, 1=Clsd}, implementation-data-type=boolean_BMS
    CmplFlg: compu {0=CmplFlg_OK, 1=CmplFlg_NOK}, implementation-data-type=boolean_BMS, type-emitter=RTE
    CmptmtCoolgSts: category=VALUE, base-type=uint8_BMS, compu-method=CmptmtCoolgSts_1
    Cntr: implementation-data-type=uint16_BMS, type-emitter=RTE
    cofshnt: category=VALUE, base-type=float32_BMS, sw-calibration-access=READ-ONLY, type-emitter=RTE
    ComQly: compu {0=ComQlyNOk, 1=ComQlyOk}, implementation-data-type=uint8_BMS, type-emitter=RTE
    CoolgLvlReq: compu {0=NotReqd, 1=LoReq, 2=MedReq, 3=HiReq}, implementation-data-type=uint8_BMS, type-emitter=RTE
    CooltFlow: implementation-data-type=float32_BMS, type-emitter=RTE
    CooltLvlFlg: compu {0=Full, 1=Empty}, implementation-data-type=boolean_BMS, type-emitter=RTE
    CooltTSigForDtElec: category=VALUE, base-type=uint16_BMS
    CooltTSigForDtElec_ASW: implementation-data-type=float32_BMS
    CpInmAs: implementation-data-type=float32_BMS
    CpInmAsAry: category=ARRAY, sw-calibration-access=READ-ONLY, type-emitter=RTE
      element Element: array-size=120, array-size-semantics=FIXED-SIZE, implementation-data-type=CpInmAs
    CPSRFallFlg: category=VALUE, base-type=boolean_BMS, sw-calibration-access=READ-ONLY, type-emitter=RTE
    CPSRU: category=VALUE, base-type=U1_2
    CrashStsSafe: category=STRUCTURE
      element CrashStsSafeChks: implementation-data-type=CrashStsSafeChks
      element CrashStsSafeCntr: implementation-data-type=CrashStsSafeCntr
      element CrashStsSafeSts: implementation-data-type=CrashStsSafeSts
    CrashStsSafeChks: category=VALUE, base-type=UInt8_2
    CrashStsSafeCntr: category=VALUE, base-type=uint8_BMS
    CrashStsSafeSts: category=VALUE, base-type=boolean_BMS, compu {0=CrashSts2_NoCrash, 1=CrashSts2_Crash; unit Unitless}
    CscBdTVldAry: category=ARRAY, sw-calibration-access=READ-ONLY
      element CscBdTVldAry: array-size=40, array-size-semantics=FIXED-SIZE, implementation-data-type=boolean_BMS
    CurrtInA: implementation-data-type=float32_BMS, type-emitter=RTE
    CurrtInmA: implementation-data-type=sint32_BMS, type-emitter=RTE
    DCChaPwrAct: implementation-data-type=uint16_BMS, type-emitter=RTE
    DCChaPwrAct_ASW: implementation-data-type=float32_BMS, type-emitter=RTE
    DCChgRlyStuckDetct: implementation-data-type=boolean_BMS, type-emitter=RTE
    DCChgStopSTS: compu-method=DCChgStopSTS, implementation-data-type=uint8_BMS, type-emitter=RTE
    DCChrgnHndlSts: compu-method=DCChrgnHndlSts, range raw 0..7, implementation-data-type=uint8
    DCChrgnNegPortT: category=VALUE, base-type=T3_2
    DcChrgnOn: compu {0=DcChrg_Start, 1=DcChrg_Finish}, implementation-data-type=uint8_BMS, type-emitter=RTE
    DCChrgnPosPortT: category=VALUE, base-type=T3_2
    DCChrgSt_ASW: compu-method=DCChrgSt_ASW, implementation-data-type=uint8_BMS
    DchaPwrAllwd: range raw 0..1023, implementation-data-type=uint16
    DchrgnIntSckState: range raw 0..1, implementation-data-type=uint8
    DchrgnIntState: range raw 0..7, implementation-data-type=uint8
    DChrgTarValLnr: category=VALUE, base-type=uint16_BMS
    DChrgTarValLnr_ASW: category=VALUE, base-type=float32_BMS
    DCPreHeatgReq: compu {0=NoPreHeat, 1=PreHeat, 2=PreHeatErr}, implementation-data-type=uint8_BMS, type-emitter=RTE
    DemFltSts: implementation-data-type=uint8_BMS, type-emitter=RTE
    DenoOfDiagcRateGen: category=VALUE, base-type=Boolean_2, compu {0=Boolean_FALSE, 1=Boolean_TRUE; unit Unitless}
    DispHvBattLvlOfChrg: range raw 0..1023, implementation-data-type=uint16
    DispHvBattLvlOfChrg_ASW: implementation-data-type=float32_BMS
    DrvgCyc: category=VALUE, base-type=boolean_BMS, compu {0=OnOff1_Off, 1=OnOff1_On; unit Unitless}
    DrvgCycToClrPrmntDtc: category=VALUE, base-type=Boolean_2, compu {0=Boolean_FALSE, 1=Boolean_TRUE; unit Unitless}
    Duty: implementation-data-type=uint8_BMS, type-emitter=RTE
    Egyah: implementation-data-type=float32_BMS
    Egykwh: implementation-data-type=single_BMS
    Egywh: implementation-data-type=float32_BMS, type-emitter=RTE
    Egywh_uint32: implementation-data-type=uint32_BMS, type-emitter=RTE
    EngAmbTCalcd: category=VALUE, base-type=uint16_BMS
    EngAmbTCalcd_ASW: implementation-data-type=float32_BMS
    EngNSafe: category=STRUCTURE
      4 x element, all with category=TYPE_REFERENCE:
        EngNSafeEngN: implementation-data-type=EngNSafeEngN
        EngNSafeEngNChks: implementation-data-type=EngNSafeEngNChks
        EngNSafeEngNCntr: implementation-data-type=EngNSafeEngNCntr
        EngNSafeEngNGrdt: implementation-data-type=EngNSafeEngNGrdt
    EngNSafe_ASW: category=STRUCTURE
      4 x element, all with category=TYPE_REFERENCE:
        EngNSafeEngN_ASW: implementation-data-type=EngNSafeEngN_ASW
        EngNSafeEngNChks_ASW: implementation-data-type=EngNSafeEngNChks_ASW
        EngNSafeEngNCntr_ASW: implementation-data-type=EngNSafeEngNCntr_ASW
        EngNSafeEngNGrdt_ASW: implementation-data-type=EngNSafeEngNGrdt_ASW
    EngNSafeEngN: category=VALUE, base-type=uint16_BMS
    EngNSafeEngN_ASW: category=VALUE, base-type=float32_BMS
    EngNSafeEngNChks: category=VALUE, base-type=UInt8_2
    EngNSafeEngNChks_ASW: category=VALUE, base-type=uint8_BMS
    EngNSafeEngNCntr: category=VALUE, base-type=uint8_BMS
    EngNSafeEngNCntr_ASW: category=VALUE, base-type=uint8_BMS
    EngNSafeEngNGrdt: category=VALUE, base-type=NGrdt1_2
    EngNSafeEngNGrdt_ASW: category=VALUE, base-type=sint16_BMS
    EngOnReq: category=VALUE, base-type=boolean_BMS, compu {0=OnOff1_Off, 1=OnOff1_On; unit Unitless}
    EngSt1WdSts: category=STRUCTURE
      element EngSt1WdStsChks: implementation-data-type=EngSt1WdStsChks
      element EngSt1WdStsCntr: implementation-data-type=EngSt1WdStsCntr
      element EngSt1WdStsEngSt1WdSts: implementation-data-type=EngSt1WdStsEngSt1WdSts
    EngSt1WdStsChks: category=VALUE, base-type=UInt8_2
    EngSt1WdStsCntr: category=VALUE, base-type=uint8_BMS
    EngSt1WdStsEngSt1WdSts: category=VALUE, base-type=uint8_BMS, compu-method=EngSt1_1
    EngT: category=STRUCTURE
      element EngTEngT: implementation-data-type=EngTEngT
      element EngTQf: implementation-data-type=EngTQf
    EngT_ASW: category=STRUCTURE
      element EngTEngT_ASW: implementation-data-type=EngTEngT_ASW
      element EngTQf_ASW: implementation-data-type=EngTQf_ASW
    EngTEngT: category=VALUE, base-type=T3_2
    EngTEngT_ASW: category=VALUE, base-type=float32_BMS
    EngTiOn: category=VALUE, base-type=TimeDesForSWDL_2
    EngTiOn_ASW: implementation-data-type=float32_BMS
    EngTQf: category=VALUE, base-type=uint8_BMS, compu-method=Qf1_1
    EngTQf_ASW: category=VALUE, base-type=uint8_BMS
    EolMod: compu {0=EntryEOLCmd, 1=ExitEOLCmd}, implementation-data-type=uint8_BMS, type-emitter=RTE
    EOLSts: implementation-data-type=uint8_BMS
    EstimPwr: implementation-data-type=uint32_BMS, type-emitter=RTE
    Factor: implementation-data-type=float32_BMS, type-emitter=RTE
    FastChrgnLEDIndctn: compu-method=FastChrgnLEDIndctn, range raw 0..7, implementation-data-type=uint8
    FastChrgnLockCtrl: category=VALUE, base-type=boolean_BMS, compu {0=OnOff1_Off, 1=OnOff1_On; unit Unitless}
    filmHeatingSts: category=VALUE, base-type=uint8_BMS, sw-calibration-access=READ-ONLY, compu-method=filmHeatingSts, type-emitter=RTE
    FlgAry: category=ARRAY, sw-calibration-access=READ-ONLY, type-emitter=RTE
      element Element: array-size=120, array-size-semantics=FIXED-SIZE, implementation-data-type=boolean_BMS
    float32_BMS: category=VALUE, base-type=float32_BMS, range raw -INF..INF, type-emitter=RTE
    float32_BMS_2: category=VALUE, base-type=float32_BMS, type-emitter=RTE
    FltFlg: compu {0=False, 1=True}, implementation-data-type=boolean_BMS, type-emitter=RTE
    FltLvl: implementation-data-type=uint8_BMS
    Frq: category=VALUE, base-type=uint16_BMS, sw-calibration-access=READ-ONLY, type-emitter=RTE
    GBCodeArray: category=ARRAY, sw-calibration-access=READ-ONLY, type-emitter=RTE
      element GBCodeArray: array-size=24, array-size-semantics=FIXED-SIZE, implementation-data-type=uint8_BMS
    GpsStatus: category=VALUE, base-type=boolean_BMS, compu {0=NoYes1_No, 1=NoYes1_Yes; unit Unitless}
    HeatGen: implementation-data-type=float32_BMS, type-emitter=RTE
    HeatgLvlReq: compu {0=NotReqd, 1=LoReq, 2=MedReq, 3=HiReq}, implementation-data-type=uint8_BMS, type-emitter=RTE
    HeatModReq: compu {0=Close, 1=Cool, 2=Heat, 3=Cycle}, implementation-data-type=uint8_BMS, type-emitter=RTE
    HiVlt: implementation-data-type=uint32_BMS, type-emitter=RTE
    HsdFlt: compu {0=HsdFlt1}, implementation-data-type=uint8_BMS, type-emitter=RTE
    HSDMod: compu {0=GPIOMod, 1=SPIMod}, implementation-data-type=uint8_BMS, type-emitter=RTE
    HSDPort: category=VALUE, base-type=boolean_BMS, sw-calibration-access=READ-ONLY, type-emitter=RTE
    HSDPortAry: category=ARRAY, sw-calibration-access=READ-ONLY, type-emitter=RTE
      element HSDPortAry: array-size=7, array-size-semantics=FIXED-SIZE, implementation-data-type=boolean_BMS
    HvAuxActPwr: range raw 0..1023, implementation-data-type=uint16
    HvBattBalFlg: category=VALUE, base-type=boolean_BMS, compu {0=OnOff1_Off, 1=OnOff1_On; unit Unitless}
    HvBattCap: category=VALUE, base-type=BRMBatteRatedCp_1
    HvBattCellTInfo: category=STRUCTURE
      6 x element, all with category=TYPE_REFERENCE:
        HvBattCellTInfoHvBattSnsrT: implementation-data-type=HvBattCellTInfoHvBattSnsrT
        HvBattCellTInfoHvBattTMax: implementation-data-type=HvBattCellTInfoHvBattTMax
        HvBattCellTInfoHvBattTMin: implementation-data-type=HvBattCellTInfoHvBattTMin
        HvBattCellTInfoHvBattTSnsrNr: implementation-data-type=HvBattCellTInfoHvBattTSnsrNr
        HvBattCellTInfoHvTempSnsrTMaxsSerlNr: implementation-data-type=HvBattCellTInfoHvTempSnsrTMaxsSerlNr
        HvBattCellTInfoHvTempSnsrTMinSerlNr: implementation-data-type=HvBattCellTInfoHvTempSnsrTMinSerlNr
    HvBattCellTInfoHvBattSnsrT: category=VALUE, base-type=HvT1_3
    HvBattCellTInfoHvBattTMax: category=VALUE, base-type=HvT1_3
    HvBattCellTInfoHvBattTMin: category=VALUE, base-type=HvT1_3
    HvBattCellTInfoHvBattTSnsrNr: category=VALUE, base-type=UInt8_2
    HvBattCellTInfoHvTempSnsrTMaxsSerlNr: category=VALUE, base-type=UInt8_2
    HvBattCellTInfoHvTempSnsrTMinSerlNr: category=VALUE, base-type=UInt8_2
    HvBattCellTNr: category=VALUE, base-type=HvBattCellTNr_1
    HvBattCellUInfo: category=STRUCTURE
      4 x element, all with category=TYPE_REFERENCE:
        HvBattCellUInfoU{1..4}: implementation-data-type=HvBattCellUInfoU{1..4}
    HvBattCellUInfoU{1..3}: category=VALUE, base-type=UInt8_2
    HvBattCellUInfoU4: category=VALUE, base-type=uint16_BMS
    HvBattChrgnCmd: category=VALUE, base-type=uint8_BMS, compu-method=HVBattChargnCmd_1
    HvBattChrgnCmpl: category=VALUE, base-type=boolean_BMS, compu {0=NoYes1_No, 1=NoYes1_Yes; unit Unitless}
    HvBattChrgnEgyCnsAllwd1: category=VALUE, base-type=uint16_BMS
    HvBattChrgnILim: category=VALUE, base-type=uint16_BMS
    HvBattChrgnPwrAllwd1: range raw 0..8191, implementation-data-type=uint16
    HvBattChrgnPwrCns1: category=VALUE, base-type=uint16_BMS
    HvBattChrgnPwrCritDes1: category=VALUE, base-type=uint16_BMS
    HvBattChrgnPwrNormDes1: category=VALUE, base-type=uint16_BMS
    HvBattClimaPwr: category=VALUE, base-type=uint16_BMS
    HvBattClrRdyReq: category=VALUE, base-type=boolean_BMS, compu {0=OnOff1_Off, 1=OnOff1_On; unit Unitless}
    HvBattCod: category=ARRAY
      element Element: array-size=7, array-size-semantics=FIXED-SIZE, implementation-data-type=HvBattCodElementType
    HvBattCodElementType: category=VALUE, base-type=UInt8_2
    HvBattCodLen: category=VALUE, base-type=HvBattNr_1
    HvBattCoolgCmd: category=VALUE, base-type=uint8_BMS, compu-method=HVBattChargnCmd_1
    HvBattCoolgEgyCnsAllwd1: category=VALUE, base-type=uint16_BMS
    HvBattCoolgEgyCnsAllwd1_ASW: implementation-data-type=float32_BMS
    HvBattCoolgEgyReq1: category=VALUE, base-type=uint16_BMS
    HvBattCoolgReq: category=VALUE, base-type=uint8_BMS, compu-method=HvBattCoolgReq_1
    HvBattCoolgSts: category=VALUE, base-type=boolean_BMS, compu {0=ClimaSts_Start, 1=ClimaSts_Finish; unit Unitless}
    HvBattCooltFlowReq: category=VALUE, base-type=uint16_BMS
    HvBattCooltLvl: category=VALUE, base-type=boolean_BMS, compu {0=HvBattCooltLvl_Full, 1=HvBattCooltLvl_Empty; unit Unitless}
    HvBattCooltMaxTReq: category=VALUE, base-type=T3_2
    HvBattCooltMinTReq: category=VALUE, base-type=T3_2
    HvBattCooltOutletT: category=VALUE, base-type=uint16_BMS
    HvBattCooltT: category=VALUE, base-type=uint16_BMS
    HvBattCooltTReq: category=VALUE, base-type=T3_2
    HvBattEgyAvlChrg1: category=VALUE, base-type=uint16_BMS
    HvBattEgyAvlDcha1: category=VALUE, base-type=uint16_BMS
    HvBattEgyCdn: category=VALUE, base-type=Perc2_2
    HvBattErrIndcnReq: category=VALUE, base-type=boolean_BMS, compu {0=OnOff1_Off, 1=OnOff1_On; unit Unitless}
    HvBattFlwEstmd: category=VALUE, base-type=uint16_BMS
    HvBattFlwEstmd_ASW: implementation-data-type=float32_BMS
    HvBattHeatgEgyReq: category=VALUE, base-type=uint16_BMS
    HvBattHeatGenn: category=VALUE, base-type=uint16_BMS
    HvBattHeatgPwr: category=VALUE, base-type=uint16_BMS
    HvBattIDc1: category=VALUE, base-type=uint16_BMS
    HvBattILim: category=VALUE, base-type=uint16_BMS
    HvBattLimnIndcn: category=VALUE, base-type=UInt16_2
    HvBattMismatchFlt: category=VALUE, base-type=boolean_BMS, compu {0=DevErrSts2_NoFlt, 1=DevErrSts2_Flt; unit Unitless}
    HvBattNr: category=VALUE, base-type=HvBattNr_1
    HvBattPreChrgReq: category=VALUE, base-type=boolean_BMS, compu {0=OnOff1_Off, 1=OnOff1_On; unit Unitless}
    HvBattPulseHeatSts: category=VALUE, base-type=uint8_BMS, compu {0=HeatDefault, 1=HeatComplete, 2=HeatReserve1, 3=HeatReserve2}, type-emitter=RTE
    HvBattPVal: category=VALUE, base-type=uint16_BMS
    HvBattPwrCdn: category=VALUE, base-type=Perc2_2
    HvBattPwrLimChrg1: category=VALUE, base-type=uint16_BMS
    HvBattPwrLimDcha1: category=VALUE, base-type=uint16_BMS
    HvBattPwrLimDchaSoft: category=VALUE, base-type=uint16_BMS
    HvBattSoc: category=VALUE, base-type=uint16_BMS
    HvBattSocLimHi: category=VALUE, base-type=uint16_BMS
    HvBattSocLimLo: category=VALUE, base-type=uint16_BMS
    HvBattSocLimMax: category=VALUE, base-type=uint16_BMS
    HvBattSocLimMin: category=VALUE, base-type=uint16_BMS
    HvBattT: category=ARRAY
      element Element: array-size=3, array-size-semantics=FIXED-SIZE, range raw 0..8191, implementation-data-type=HvBattTElementType
    HvBattTElementType: category=VALUE, base-type=sint16_BMS
    HvBattThermInfoInFuture: category=STRUCTURE
      6 x element, all with category=TYPE_REFERENCE:
        HvBattThermInfoInFuturePwrAtTime: implementation-data-type=HvBattThermInfoInFuturePwrAtTime
        HvBattThermInfoInFutureSequenceNo: range raw 0..31, implementation-data-type=HvBattThermInfoInFutureSequenceNo
        HvBattThermInfoInFutureTempAtTime: implementation-data-type=HvBattThermInfoInFutureTempAtTime
        HvBattThermInfoInFutureThermModAtTime: range raw 0..7, implementation-data-type=HvBattThermInfoInFutureThermModAtTime
        HvBattThermInfoInFutureTime: implementation-data-type=HvBattThermInfoInFutureTime
        HvBattThermInfoInFutureVersionNo: range raw 0..7, implementation-data-type=HvBattThermInfoInFutureVersionNo
    HvBattThermInfoInFuture_ASW: category=STRUCTURE
      6 x element, all with category=TYPE_REFERENCE:
        HvBattThermInfoInFuturePwrAtTime_ASW: implementation-data-type=HvBattThermInfoInFuturePwrAtTime_ASW
        HvBattThermInfoInFutureSequenceNo_ASW: implementation-data-type=HvBattThermInfoInFutureSequenceNo_ASW
        HvBattThermInfoInFutureTempAtTime_ASW: implementation-data-type=HvBattThermInfoInFutureTempAtTime_ASW
        HvBattThermInfoInFutureThermModAtTime_ASW: implementation-data-type=HvBattThermInfoInFutureThermModAtTime_ASW
        HvBattThermInfoInFutureTime_ASW: implementation-data-type=HvBattThermInfoInFutureTime_ASW
        HvBattThermInfoInFutureVersionNo_ASW: implementation-data-type=HvBattThermInfoInFutureVersionNo_ASW
    HvBattThermInfoInFuturePwrAtTime: category=VALUE, base-type=PwrAtTime_1
    HvBattThermInfoInFuturePwrAtTime_ASW: category=VALUE, base-type=sint16_BMS
    HvBattThermInfoInFutureSequenceNo: category=VALUE, base-type=uint8_BMS
    HvBattThermInfoInFutureSequenceNo_ASW: category=VALUE, base-type=uint8_BMS
    HvBattThermInfoInFutureTempAtTime: category=VALUE, base-type=TempAtTime_1
    HvBattThermInfoInFutureTempAtTime_ASW: category=VALUE, base-type=sint16_BMS
    HvBattThermInfoInFutureThermModAtTime: category=VALUE, base-type=uint8_BMS
    HvBattThermInfoInFutureThermModAtTime_ASW: category=VALUE, base-type=uint8_BMS
    HvBattThermInfoInFutureTime: category=VALUE, base-type=UInt8_2
    HvBattThermInfoInFutureTime_ASW: category=VALUE, base-type=UInt8_2
    HvBattThermInfoInFutureVersionNo: category=VALUE, base-type=uint8_BMS
    HvBattThermInfoInFutureVersionNo_ASW: category=VALUE, base-type=uint8_BMS
    HvBattThermMod: category=VALUE, base-type=uint8_BMS, compu-method=HvBattThermMod_2
    HvBattThermReqFb: category=VALUE, base-type=uint8_BMS, compu-method=HvBattThermReqFb_3
    HvBattTMaxSerlNr: category=VALUE, base-type=HvBattNr_1
    HvBattTMinSerlNr: category=VALUE, base-type=HvBattNr_1
    HvBattUDc: category=VALUE, base-type=uint16_BMS
    HvBattUDynMaxLim: category=VALUE, base-type=uint16_BMS
    HvBattUDynMinLim: category=VALUE, base-type=uint16_BMS
    HvBattULim: category=VALUE, base-type=uint16_BMS
    HvBattVoltMaxSerlNr: category=VALUE, base-type=HvBattNr_1
    HvBattVoltMinSerlNr: category=VALUE, base-type=HvBattNr_1
    HvBattWMDSts: category=VALUE, base-type=uint8_BMS
    HVCCOperMod: implementation-data-type=uint8_BMS
    HvCellTDifFlt: category=VALUE, base-type=uint8_BMS, compu-method=FauLevel_2
    HvCellTOverFlt: category=VALUE, base-type=uint8_BMS, compu-method=FauLevel_2
    HvCellUDifFlt: category=VALUE, base-type=uint8_BMS, compu-method=FauLevel_2
    HvCellUOverFlt: category=VALUE, base-type=uint8_BMS, compu-method=FauLevel_2
    HvCellUUnderFlt: category=VALUE, base-type=uint8_BMS, compu-method=FauLevel_2
    HvchSts: range raw 0..7, implementation-data-type=uint8
    HVCnctSts: implementation-data-type=uint8_BMS
    HVIL{1..3}Sts: category=VALUE, base-type=boolean_BMS, compu {0=OpenClose_Open, 1=OpenClose_Close; unit Unitless}
    HvilFlt: category=VALUE, base-type=boolean_BMS, compu {0=DevErrSts2_NoFlt, 1=DevErrSts2_Flt; unit Unitless}
    HVILSts: compu-method=HVILSts, implementation-data-type=uint8_BMS, type-emitter=RTE
    HvIsoFlt: category=VALUE, base-type=uint8_BMS, compu-method=FauLevel_2
    HvIsoR: category=VALUE, base-type=HvR1_1
    HvIsoSts: category=VALUE, base-type=uint8_BMS, compu-method=HvIsoSts_2, type-emitter=RTE
    HvOnMaiReq: category=VALUE, base-type=uint8_BMS, compu-method=HvActvnSts_1
    HvPackOverChrgFlt: category=VALUE, base-type=uint8_BMS, compu-method=FauLevel_2
    HvPackUOverFlt: category=VALUE, base-type=uint8_BMS, compu-method=FauLevel_2
    HvPackUUnderFlt: category=VALUE, base-type=uint8_BMS, compu-method=FauLevel_2
    HvSocHiFlt: category=VALUE, base-type=uint8_BMS, compu-method=FauLevel_2
    HvSocHopFlt: category=VALUE, base-type=uint8_BMS, compu-method=FauLevel_2
    HvSocLoFlt: category=VALUE, base-type=uint8_BMS, compu-method=FauLevel_2
    HVSts: implementation-data-type=uint8_BMS
    HvSysActvnInhb: category=VALUE, base-type=boolean_BMS, compu {0=OkNotOk1_Ok, 1=OkNotOk1_NotOk; unit Unitless}
    HvSysCrashFb: category=VALUE, base-type=uint8_BMS, compu-method=CrashFb_1
    HvSysLimnIndcn: category=VALUE, base-type=UInt16_2
    HvSysPwrOff: category=VALUE, base-type=boolean_BMS, compu {0=OkNotOk1_Ok, 1=OkNotOk1_NotOk; unit Unitless}
    HvSysRlySts: category=STRUCTURE
      element HvSysRlyStsChks: implementation-data-type=HvSysRlyStsChks
      element HvSysRlyStsCntr: implementation-data-type=HvSysRlyStsCntr
      element HvSysRlyStsHvSysRlySts: implementation-data-type=HvSysRlyStsHvSysRlySts
    HvSysRlyStsChks: category=VALUE, base-type=UInt8_2
    HvSysRlyStsCntr: category=VALUE, base-type=uint8_BMS
    HvSysRlyStsHvSysRlySts: category=VALUE, base-type=uint8_BMS, compu-method=HvActvnSts_1
    HvSysSts: category=VALUE, base-type=uint8_BMS, compu {0=HvSysSts_Inin, 1=HvSysSts_Test, 2=HvSysSts_Rdy; unit Unitless}
    Index: implementation-data-type=uint8_BMS
    InfoVers: implementation-data-type=uint8_BMS, type-emitter=RTE
    IntegritTestSts: implementation-data-type=uint8_BMS
    IsgCooltT: category=VALUE, base-type=HvT1_3
    IsgCooltT_ASW: implementation-data-type=float32_BMS
    IsgModSts: category=VALUE, base-type=uint8_BMS, compu-method=IsgModTyp2_3
    IsgUDc: category=VALUE, base-type=uint16_BMS
    IsgUDc_ASW: implementation-data-type=float32_BMS
    IsgVehPulseHeatModSts: category=VALUE, base-type=uint8_BMS, type-emitter=RTE
    IsoCrshSts: compu-method=IsoCrshSts, implementation-data-type=uint8_BMS, type-emitter=RTE
    IsoDIDWrResSts: category=VALUE, base-type=uint8_BMS, sw-calibration-access=READ-ONLY, type-emitter=RTE
    IsoFlt: compu {0=IsoDefault, 1=OneLevelFlt, 2=TwoLevelFlt}, implementation-data-type=uint8_BMS, type-emitter=RTE
    IsoFltSts: compu-method=IsoFltSts, implementation-data-type=uint8_BMS, type-emitter=RTE
    IsoMod: compu {0=Default, 1=LvMode, 2=HvMode, 3=ChargingMode}, implementation-data-type=uint8_BMS, type-emitter=RTE
    IsoSts: compu-method=IsoSts, implementation-data-type=uint8_BMS, type-emitter=RTE
    IuprDenominatorInhb: category=VALUE, base-type=boolean_BMS, compu {0=InhibitSts_NotInhibited, 1=InhibitSts_Inhibited; unit Unitless}
    KalP: implementation-data-type=single_BMS, type-emitter=RTE
    KalPAry: category=ARRAY, sw-calibration-access=READ-ONLY, type-emitter=RTE
      element Element: array-size=120, array-size-semantics=FIXED-SIZE, implementation-data-type=KalP
    LoadValCalcd: category=VALUE, base-type=Perc5_2
    LoadValCalcd_ASW: implementation-data-type=float32_BMS
    LoDCChrgSt: compu-method=LoDCChrgSt, implementation-data-type=uint8_BMS, type-emitter=RTE
    LosLimnIndcn: implementation-data-type=uint16_BMS, type-emitter=RTE
    LowVlt: implementation-data-type=uint16_BMS, type-emitter=RTE
    LsdFlt: compu {0=LsdFlt1}, implementation-data-type=uint8_BMS, type-emitter=RTE
    MaintainBattTCtrl: category=VALUE, base-type=boolean_BMS, compu {0=OnOff1_Off, 1=OnOff1_On; unit Unitless}
    MemQly: compu {0=MemQlyNOk, 1=MemQlyOk}, implementation-data-type=boolean_BMS, type-emitter=RTE
    MntnBattTFbSts: compu-method=MntnBattTFbSts, implementation-data-type=uint8_BMS, type-emitter=RTE
    MntnBattTTimin: implementation-data-type=uint16_BMS, type-emitter=RTE
    MonrCycCmpl: category=VALUE, base-type=boolean_BMS, compu {0=NotCmpl1_NotCmpl, 1=NotCmpl1_Cmpl; unit Unitless}
    MonrSts: compu {0=MonrSts1, 1=MonrSts2}, implementation-data-type=uint8_BMS, type-emitter=RTE
    MultiCurrt: implementation-data-type=float32_BMS, type-emitter=RTE
    nrAFERstAry: category=ARRAY, sw-calibration-access=READ-ONLY, type-emitter=RTE
      element Element: array-size=4, array-size-semantics=FIXED-SIZE, implementation-data-type=uint16_BMS
    nrCurRange: category=ARRAY, sw-calibration-access=READ-ONLY, type-emitter=RTE
      element Element: array-size=4, array-size-semantics=FIXED-SIZE, implementation-data-type=uint32_BMS
    Number: implementation-data-type=uint8_BMS
    OdpDcChgRlyState: range raw 0..15, implementation-data-type=uint8
    Ohm_HVIL: implementation-data-type=single_BMS, type-emitter=RTE
    OnBdChrgrCurrA: implementation-data-type=float32_BMS, type-emitter=RTE
    OnBdChrgrHndlSts1: range raw 0..15, implementation-data-type=uint8
    OnBdChrgrIDc: range raw 0..4095, implementation-data-type=uint16
    OnBdChrgrSt: range raw 0..15, implementation-data-type=uint8
    OnBdChrgrUDc: range raw 0..8191, implementation-data-type=uint16
    OnBdIntDischrgrSt: implementation-data-type=uint8_BMS, type-emitter=RTE
    OnOffNoReq: compu {0=OnOffNoReq_NoReq, 1=OnOffNoReq_On, 2=OnOffNoReq_Off}, implementation-data-type=uint8_BMS, type-emitter=RTE
    OperMod: implementation-data-type=uint8_BMS
    PackAirPVal: implementation-data-type=float32_BMS, type-emitter=RTE
    PackNr: category=VALUE, base-type=HvBattNr_1
    PakRes: category=VALUE, base-type=float32_BMS, sw-calibration-access=READ-ONLY, type-emitter=RTE
    PCHMSts: compu-method=PCHMSts, implementation-data-type=uint8_BMS
    Perc: range raw 0..65535, implementation-data-type=uint16_BMS, type-emitter=RTE
    PreHeatgReq: implementation-data-type=uint8_BMS, type-emitter=RTE
    PreHeatSts: implementation-data-type=uint8_BMS, type-emitter=RTE
    PreSocOperMod: compu {0=AhCalcn, 1=ChgKal, 2=DisKal}, implementation-data-type=uint8_BMS, type-emitter=RTE
    PressfloatVal: implementation-data-type=float32_BMS, type-emitter=RTE
    PressVal: implementation-data-type=uint32_BMS, type-emitter=RTE
    PrpsnFbLimnIndcn: category=VALUE, base-type=uint8_BMS
    PrpsnSysActv: category=VALUE, base-type=boolean_BMS, compu {0=NotCmpl1_NotCmpl, 1=NotCmpl1_Cmpl; unit Unitless}
    PulseHeatTsts: category=VALUE, base-type=uint8_BMS, compu-method=PulseHeatTsts, type-emitter=RTE
    Pwr: implementation-data-type=float32_BMS
    PwrEgyMgrAvl: range raw 0..2047, implementation-data-type=uint16
    RadFanCoolgSts: category=VALUE, base-type=uint8_BMS
    RlyCur: category=VALUE, base-type=sint16_BMS, sw-calibration-access=READ-ONLY, type-emitter=RTE
    RlyCurAry: category=ARRAY, sw-calibration-access=READ-ONLY, type-emitter=RTE
      element Element: array-size=3, array-size-semantics=FIXED-SIZE, implementation-data-type=RlyCur
    RlySts: implementation-data-type=uint8_BMS
    RoutCtlFlg: compu {0=RoutCtlFalse (RoutctlFalse), 1=RoutCtlTrue}, implementation-data-type=boolean_BMS, type-emitter=RTE
    RTCSleepTi: implementation-data-type=uint32_BMS
    RTCTi: implementation-data-type=uint16_BMS, type-emitter=RTE
    Rval: implementation-data-type=single_BMS, type-emitter=RTE
    SbcSafeStFlg: compu {0=SBCNormal, 1=SBCNotNormal}, implementation-data-type=boolean_BMS, type-emitter=RTE
    SeqNr: implementation-data-type=uint8_BMS, type-emitter=RTE
    SigInvldFlg: implementation-data-type=boolean_BMS
    SigQly: implementation-data-type=uint8_BMS
    SigVldFlg: implementation-data-type=boolean_BMS
    single_BMS: category=VALUE, base-type=float32_BMS, range raw -INF..INF, type-emitter=RTE
    sint16_BMS: category=VALUE, base-type=sint16_BMS, range raw -32768..32767, type-emitter=RTE
    sint32_BMS: category=VALUE, base-type=sint32_BMS, range raw 0, type-emitter=RTE
    SocOperMod: compu-method=SocOperMod, implementation-data-type=uint8_BMS, type-emitter=RTE
    SocPercAry: category=ARRAY, sw-calibration-access=READ-ONLY, type-emitter=RTE
      element Element: array-size=120, array-size-semantics=FIXED-SIZE, range raw -32768..32767, implementation-data-type=sint16_BMS
    SohPerc: implementation-data-type=float32_BMS, type-emitter=RTE
    SohPercAry: category=ARRAY, sw-calibration-access=READ-ONLY
      element Perc: array-size=120, array-size-semantics=FIXED-SIZE, range raw 0..65535, implementation-data-type=SohPerc
    strAbsltCp: category=STRUCTURE, sw-calibration-access=READ-ONLY, type-emitter=RTE
      element ahAbsltCpToBsw: implementation-data-type=AhCp
      element Chks: implementation-data-type=Chks
    strACCH: category=STRUCTURE, sw-calibration-access=READ-ONLY, type-emitter=RTE
      element tiTiToEndToBsw: implementation-data-type=MntnBattTTimin
      element stChrgnToTarSocrToBsw: implementation-data-type=AcChrgnToTar
      element Chks: implementation-data-type=Chks
    strAFERest: category=STRUCTURE, sw-calibration-access=READ-ONLY, type-emitter=RTE
      element nrAFERest: implementation-data-type=nrAFERstAry
      element Chks: implementation-data-type=Chks
    strBalFinishTimes: category=STRUCTURE, sw-calibration-access=READ-ONLY, type-emitter=RTE
      element nrBalFinishTimesToBsw: implementation-data-type=uint16_BMS
      element Chks: implementation-data-type=Chks
    strBalTiCalcMod: category=STRUCTURE, sw-calibration-access=READ-ONLY, type-emitter=RTE
      element stBalTiCalcModeToBsw: implementation-data-type=BalTiCalcMod
      element Chks: implementation-data-type=Chks
    strBalTotTime: category=STRUCTURE, sw-calibration-access=READ-ONLY, type-emitter=RTE
      element tiBalTotTimeToBsw: implementation-data-type=uint32_BMS
      element Chks: implementation-data-type=Chks
    strbEKFdisabled: category=STRUCTURE, sw-calibration-access=READ-ONLY, type-emitter=RTE
      element bEKFdisabledToBsw: implementation-data-type=ImplementationDataTypes/boolean
      element Chks: implementation-data-type=Chks
    strBookChrgTarValLnr: category=STRUCTURE, sw-calibration-access=READ-ONLY, type-emitter=RTE
      element percBookChrgTarValLnrToBsw: implementation-data-type=uint16_BMS
      element Chks: implementation-data-type=Chks
    strCANCrashFlt: category=STRUCTURE, sw-calibration-access=READ-ONLY, type-emitter=RTE
      element bCANCrashFlt: implementation-data-type=ImplementationDataTypes/boolean
      element Chks: implementation-data-type=Chks
    strCarCfgInVal: category=STRUCTURE, sw-calibration-access=READ-ONLY, type-emitter=RTE
      element nrCarCfgInValPosn: implementation-data-type=CfgInValPosn
      element nrCarCfgInValVal: implementation-data-type=CarCfgInValVal
      element Chks: implementation-data-type=Chks
    strCpCalcnIniSoc: category=STRUCTURE, sw-calibration-access=READ-ONLY, type-emitter=RTE
      element percCpCalcnIniSocToBsw: implementation-data-type=SocPercAry
      element Chks: implementation-data-type=Chks
    strCpCalcnStrt: category=STRUCTURE, sw-calibration-access=READ-ONLY, type-emitter=RTE
      element bCpCalcnStrtToBsw: implementation-data-type=ImplementationDataTypes/boolean
      element Chks: implementation-data-type=Chks
    strCpExt: category=STRUCTURE, sw-calibration-access=READ-ONLY, type-emitter=RTE
      element ahCpExtToBsw: implementation-data-type=AhCpAry
      element Chks: implementation-data-type=Chks
    strCpMeasTot: category=STRUCTURE, sw-calibration-access=READ-ONLY, type-emitter=RTE
      element nrCpMeasTotToBsw: implementation-data-type=Cntr
      element Chks: implementation-data-type=Chks
    strCRAHOK: category=STRUCTURE, sw-calibration-access=READ-ONLY, type-emitter=RTE
      element bReadCRSHOKFlg: implementation-data-type=ImplementationDataTypes/boolean
      element Chks: implementation-data-type=Chks
    strCrashEvent: category=STRUCTURE, sw-calibration-access=READ-ONLY, type-emitter=RTE
      element bCrashEventFlg: implementation-data-type=ImplementationDataTypes/boolean
      element Chks: implementation-data-type=Chks
    strCurrtInA: category=STRUCTURE, sw-calibration-access=READ-ONLY, type-emitter=RTE
      element iZeroDriftCurrtToBsw: implementation-data-type=CurrtInA
      element Chks: implementation-data-type=Chks
    strDisKal: category=STRUCTURE, sw-calibration-access=READ-ONLY, type-emitter=RTE
      13 x element, all with category=TYPE_REFERENCE:
        nrCalcnNumHiToBsw: implementation-data-type=Cntr
        nrCalcnNumLoToBsw: implementation-data-type=Cntr
        vSumVoltHiToBsw: implementation-data-type=Vlt
        vSumVoltLoToBsw: implementation-data-type=Vlt
        iSumCurHiToBsw: implementation-data-type=CurrtInA
        iSumCurLoToBsw: implementation-data-type=CurrtInA
        iBndryCurrtToBsw: implementation-data-type=MultiCurrt
        tSumTemToBsw: implementation-data-type=Tmp
        facRateToBsw: implementation-data-type=Factor
        percSumSocHiToBsw: implementation-data-type=Perc
        percSumSocLoToBsw: implementation-data-type=Perc
        bPatchVtgStrtFlgToBsw: implementation-data-type=ActvFlg
        Chks: implementation-data-type=Chks
    strElecDrvLinePrm: category=STRUCTURE, sw-calibration-access=READ-ONLY, type-emitter=RTE
      element nrElecDrvLinePrmAvlArbd: implementation-data-type=uint8_BMS
      element Chks: implementation-data-type=Chks
    strElecVehInletPrm: category=STRUCTURE, sw-calibration-access=READ-ONLY, type-emitter=RTE
      element nrElecVehInletPrmAvlArbd: implementation-data-type=uint8_BMS
      element Chks: implementation-data-type=Chks
    strfacKalP: category=STRUCTURE, sw-calibration-access=READ-ONLY, type-emitter=RTE
      element facKalPToBsw: implementation-data-type=KalPAry
      element Chks: implementation-data-type=Chks
    strFidStopSafely: category=STRUCTURE, sw-calibration-access=READ-ONLY, type-emitter=RTE
      element bFidStopSafely: implementation-data-type=ImplementationDataTypes/boolean
      element Chks: implementation-data-type=Chks
    strFlg: category=STRUCTURE, sw-calibration-access=READ-ONLY, type-emitter=RTE
      element bIntegrityTestFlgToBsw: implementation-data-type=ActvFlg
      element Chks: implementation-data-type=Chks
    strHvBattOptmzHintForSoc: category=STRUCTURE, sw-calibration-access=READ-ONLY, type-emitter=RTE
      element bHvBattOptmzHintFlag: implementation-data-type=ImplementationDataTypes/boolean
      element cAhAccum4TrgFullChrgCorr: implementation-data-type=uint16_BMS
      element Chks: implementation-data-type=Chks
    strHvBattSoc: category=STRUCTURE, sw-calibration-access=READ-ONLY, type-emitter=RTE
      element percHvBattSocToNrm: implementation-data-type=Perc
      element Chks: implementation-data-type=Chks
    strHvNegRlyCur: category=STRUCTURE, sw-calibration-access=READ-ONLY, type-emitter=RTE
      element iHvNegRlyCurAry: implementation-data-type=RlyCurAry
      element Chks: implementation-data-type=Chks
    strHvPosRlyCur: category=STRUCTURE, sw-calibration-access=READ-ONLY, type-emitter=RTE
      element iHvPosRlyCurAry: implementation-data-type=RlyCurAry
      element Chks: implementation-data-type=Chks
    strHVRlyRemLife: category=STRUCTURE, sw-calibration-access=READ-ONLY, type-emitter=RTE
      element nrHVPosRlyRemLife: implementation-data-type=uint32_BMS
      element nrHVNegRlyRemLife: implementation-data-type=uint32_BMS
      element Chks: implementation-data-type=Chks
    strHWCrashFlt: category=STRUCTURE, sw-calibration-access=READ-ONLY, type-emitter=RTE
      element bHWCrashFltFlg: implementation-data-type=ImplementationDataTypes/boolean
      element Chks: implementation-data-type=Chks
    strPrecRlyClsToOpen: category=STRUCTURE, sw-calibration-access=READ-ONLY, type-emitter=RTE
      element iPrecRlyClsToOpenToBsw: implementation-data-type=CurrtInA
      element Chks: implementation-data-type=Chks
    strRelCp: category=STRUCTURE, sw-calibration-access=READ-ONLY, type-emitter=RTE
      element ahRelCpToBsw: implementation-data-type=AhCp
      element Chks: implementation-data-type=Chks
    strRlyClsToOpen: category=STRUCTURE, sw-calibration-access=READ-ONLY, type-emitter=RTE
      element iMainNegRlyClsToOpenToBsw: implementation-data-type=CurrtInA
      element iMainPosRlyClsToOpenToBsw: implementation-data-type=CurrtInA
      element Chks: implementation-data-type=Chks
    strRlyOpenTimes: category=STRUCTURE, sw-calibration-access=READ-ONLY, type-emitter=RTE
      7 x element, all with category=TYPE_REFERENCE:
        nrHVPosRlyOpenFst: implementation-data-type=uint8_BMS
        nrHVPosRlyOpenSnd: implementation-data-type=uint32_BMS
        nrHVPosRlyOpenTrd: implementation-data-type=uint32_BMS
        nrHVNegRlyOpenFst: implementation-data-type=uint8_BMS
        nrHVNegRlyOpenSnd: implementation-data-type=uint32_BMS
        nrHVNegRlyOpenTrd: implementation-data-type=uint32_BMS
        Chks: implementation-data-type=Chks
    strRlyVltDrpAbnrmCnt: category=STRUCTURE, sw-calibration-access=READ-ONLY, type-emitter=RTE
      element RlyVltDrpAbnrmCntToBsw: implementation-data-type=uint32_BMS
      element Chks: implementation-data-type=Chks
    strRTC: category=STRUCTURE, sw-calibration-access=READ-ONLY, type-emitter=RTE
      9 x element, all with category=TYPE_REFERENCE:
        tiRTCSecToBsw: implementation-data-type=RTCTi
        tiRTCMinToBsw: implementation-data-type=RTCTi
        tiRTCHrToBsw: implementation-data-type=RTCTi
        tiRTCDayToBsw: implementation-data-type=RTCTi
        tiRTCMthToBsw: implementation-data-type=RTCTi
        tiRTCYearToBsw: implementation-data-type=RTCTi
        tiRunTotTiToBsw: implementation-data-type=RTCTi
        stiSleepTotTiToBsw: implementation-data-type=RTCTi
        Chks: implementation-data-type=Chks
    strShutCalAByUDS: category=STRUCTURE, sw-calibration-access=READ-ONLY, type-emitter=RTE
      element ShutCalAByUDSToBsw: implementation-data-type=float32_BMS_2
    strShutCalBByUDS: category=STRUCTURE, sw-calibration-access=READ-ONLY, type-emitter=RTE
      element ShutCalBByUDSToBsw: implementation-data-type=float32_BMS_2
    strShutCalCByUDS: category=STRUCTURE, sw-calibration-access=READ-ONLY, type-emitter=RTE
      element ShutCalCByUDSToBsw: implementation-data-type=float32_BMS_2
    strShutCalR25ByUDS: category=STRUCTURE, sw-calibration-access=READ-ONLY, type-emitter=RTE
      element ShutCalR25ByUDSToBsw: implementation-data-type=uint16_BMS
    strShutDown: category=STRUCTURE, sw-calibration-access=READ-ONLY, type-emitter=RTE
      10 x element, all with category=TYPE_REFERENCE:
        percMinCellSohToBsw: implementation-data-type=Perc
        percSohPwrCdnToBsw: implementation-data-type=Perc
        percSohEgyCdnToBsw: implementation-data-type=SohPercAry
        percMaxCellSohToBsw: implementation-data-type=Perc
        percAvgCellSohToBsw: implementation-data-type=Perc
        rIsoFinalCalcValRToBsw: implementation-data-type=Rval
        dPakCapSohToBsw: implementation-data-type=Perc
        dPakResSohToBsw: implementation-data-type=Perc
        oPakResToBsw: implementation-data-type=PakRes
        Chks: implementation-data-type=Chks
    strSocPercAry: category=STRUCTURE, sw-calibration-access=READ-ONLY, type-emitter=RTE
      element percCellSocToBsw: implementation-data-type=SocPercAry
      element Chks: implementation-data-type=Chks
    strSOCRangeLearn: category=STRUCTURE, sw-calibration-access=READ-ONLY, type-emitter=RTE
      4 x element, all with category=TYPE_REFERENCE:
        percChrgAvgSOC: implementation-data-type=uint16_BMS
        nrChrgFinsTimes: implementation-data-type=uint8_BMS
        percTagtSOC: implementation-data-type=uint16_BMS
        Chks: implementation-data-type=Chks
    strSocStorage: category=STRUCTURE, sw-calibration-access=READ-ONLY, type-emitter=RTE
      7 x element, all with category=TYPE_REFERENCE:
        tiStaticAccumTiToNrm: implementation-data-type=TimeInSec
        iCurrMultiAvgToNrm: implementation-data-type=CurrtInA
        bChrgFullToNrm: implementation-data-type=ImplementationDataTypes/boolean
        bCellURebndDirToNrm: implementation-data-type=ImplementationDataTypes/boolean
        uPackUDrop1ToNrm: implementation-data-type=Vlt
        uPackUDrop2ToNrm: implementation-data-type=Vlt
        Chks: implementation-data-type=Chks
    strSoeStorage: category=STRUCTURE, sw-calibration-access=READ-ONLY, type-emitter=RTE
      10 x element, all with category=TYPE_REFERENCE:
        ahChrgFbCpTotToBsw: implementation-data-type=Egyah
        ahChrgCpTotToBsw: implementation-data-type=Egyah
        ahDchaCpTotToBsw: implementation-data-type=Egyah
        whDchaEgyAvlToBsw: implementation-data-type=Egywh_uint32
        whChrgEgyAvlToBsw: implementation-data-type=Egywh_uint32
        whChrgFbEgyTotToBsw: implementation-data-type=Egywh_uint32
        whDchaEgyTotToBsw: implementation-data-type=Egywh_uint32
        whChrgEgyTotToBsw: implementation-data-type=Egywh_uint32
        tAbtTToBsw: implementation-data-type=Tmp
        Chks: implementation-data-type=Chks
    strTimePeriod: category=STRUCTURE, sw-calibration-access=READ-ONLY, type-emitter=RTE
      8 x element, all with category=TYPE_REFERENCE:
        tiTimeRemainSecToBsw: implementation-data-type=TimeInSecAry
        ahAbsltCpToBsw: implementation-data-type=AhCpAry
        ahRelCpToBsw: implementation-data-type=AhCpAry
        percCpCalcnIniSocToBsw: implementation-data-type=SocPercAry
        ahCpExtToBsw: implementation-data-type=AhCpAry
        nrCpMeasTotToBsw: implementation-data-type=Cntr
        bCpCalcnStrtToBsw: implementation-data-type=FlgAry
        Chks: implementation-data-type=Chks
    strTimeRemain: category=STRUCTURE, sw-calibration-access=READ-ONLY, type-emitter=RTE
      element tiTimeRemainSecToBsw: implementation-data-type=CpInmAsAry
      element Chks: implementation-data-type=Chks
    strTotChrgDischTime: category=STRUCTURE, sw-calibration-access=READ-ONLY, type-emitter=RTE
      element minTotChrgDischTime: implementation-data-type=uint16_BMS
      element Chks: implementation-data-type=Chks
    strTotSingleChrgEgy: category=STRUCTURE, sw-calibration-access=READ-ONLY, type-emitter=RTE
      element whOnePlgChrgEgyTot: implementation-data-type=uint32_BMS
      element Chks: implementation-data-type=Chks
    strVINCode: category=STRUCTURE, sw-calibration-access=READ-ONLY, type-emitter=RTE
      element nrVINCodeAry: implementation-data-type=VINCodeAry
      element Chks: implementation-data-type=Chks
    stsAFEFltSts: implementation-data-type=uint8_BMS, type-emitter=RTE
    stsPNCStatus: implementation-data-type=uint32_BMS, type-emitter=RTE
    SwtSts: implementation-data-type=boolean_BMS, type-emitter=RTE
    SwtStsAry: category=ARRAY, sw-calibration-access=READ-ONLY, type-emitter=RTE
      element SwtStsAry: array-size=120, array-size-semantics=FIXED-SIZE, implementation-data-type=boolean_BMS
    TelmHVBattPlsHeatgReq: range raw 0..3, implementation-data-type=uint8
    ThermRunawayWakeUpCntr: implementation-data-type=uint8_BMS, type-emitter=RTE
    THMDOperMod: compu-method=THMDOperMod, implementation-data-type=uint8_BMS, type-emitter=RTE
    ThrPos: category=VALUE, base-type=Perc2_2
    ThrPos_ASW: implementation-data-type=float32_BMS
    TimeInMin: implementation-data-type=uint8_BMS, type-emitter=RTE
    TimeInSec: implementation-data-type=float32_BMS
    TimeInSecAry: category=ARRAY, sw-calibration-access=READ-ONLY, type-emitter=RTE
      element Element: array-size=120, array-size-semantics=FIXED-SIZE, implementation-data-type=TimeInSec
    Tmp: implementation-data-type=sint16_BMS, type-emitter=RTE
    TotChrgCap: category=VALUE, base-type=Liner32Ah_1
    TotChrgDischTime: implementation-data-type=uint16_BMS, type-emitter=RTE
    TotChrgEgy: category=VALUE, base-type=ScrRespOnEve_2
    TotDchaCap: category=VALUE, base-type=Liner32Ah_1
    TotDchaEgy: category=VALUE, base-type=ScrRespOnEve_2
    TotSingleChrgEgy: implementation-data-type=uint16_BMS, type-emitter=RTE
    TotSingleChrgEgy_ASW: implementation-data-type=float32_BMS, type-emitter=RTE
    TrsmVehSpd: category=VALUE, base-type=TrsmVehSpd_2
    TrsmVehSpd_ASW: implementation-data-type=float32_BMS
    uint16_BMS: category=VALUE, base-type=uint16_BMS, range raw 0..65535, type-emitter=RTE  # uint16 represents integers with a minimum value of 0 and a maximum value of 65535. The order-relation on uint16 is: x < y if y - x is positive. uint16 has a lexical representation consisting of a finite-length sequence of decimal digits (#x30-#x39). For example: 1, 0, 1267, +10000.
    uint32_BMS: category=VALUE, base-type=uint32_BMS, range raw 0..4294967295, type-emitter=RTE
    uint8_BMS: category=VALUE, base-type=uint8_BMS, type-emitter=RTE  # uint8 represents integers with a minimum value of 0 and a maximum value of 255. The order-relation on uint8 is: x < y if y - x is positive. uint8 has a lexical representation consisting of a finite-length sequence of decimal digits (#x30-#x39). For example: 1, 0, 126, +10.
    VehBattU: category=STRUCTURE
      element VehBattUSysU: implementation-data-type=VehBattUSysU
      element VehBattUSysUQf: implementation-data-type=VehBattUSysUQf
    VehBattU_ASW: category=STRUCTURE
      element VehBattUSysU_ASW: implementation-data-type=VehBattUSysU_ASW
      element VehBattUSysUQf_ASW: implementation-data-type=VehBattUSysUQf_ASW
    VehBattUSysU: category=VALUE, base-type=U1_2
    VehBattUSysU_ASW: category=VALUE, base-type=float32_BMS
    VehBattUSysUQf: category=VALUE, base-type=uint8_BMS, compu-method=GenQf1_1
    VehBattUSysUQf_ASW: category=VALUE, base-type=uint8_BMS
    VehCfgPrm: category=ARRAY
      element Element: array-size=8, array-size-semantics=FIXED-SIZE, implementation-data-type=VehCfgPrmElementType
    VehCfgPrmElementType: category=VALUE, base-type=Nr2_3
    VehCfgPrmExt: category=ARRAY
      element Element: array-size=8, array-size-semantics=FIXED-SIZE, implementation-data-type=VehCfgPrmExtElementType
    VehCfgPrmExtElementType: category=VALUE, base-type=Nr2_3
    VehCfgPrmToASW: category=ARRAY, type-emitter=RTE
      element Element: array-size=8, array-size-semantics=FIXED-SIZE, range raw 0..255, implementation-data-type=uint8_BMS
    VehModMngtGlbSafe1: category=STRUCTURE
      10 x element, all with category=TYPE_REFERENCE:
        VehModMngtGlbSafe1CarModSts1: implementation-data-type=VehModMngtGlbSafe1CarModSts1
        VehModMngtGlbSafe1CarModSubtypWdCarModSubtyp: implementation-data-type=VehModMngtGlbSafe1CarModSubtypWdCarModSubtyp
        VehModMngtGlbSafe1Chks: implementation-data-type=VehModMngtGlbSafe1Chks
        VehModMngtGlbSafe1Cntr: implementation-data-type=VehModMngtGlbSafe1Cntr
        VehModMngtGlbSafe1EgyLvlElecMai: implementation-data-type=VehModMngtGlbSafe1EgyLvlElecMai
        VehModMngtGlbSafe1EgyLvlElecSubtyp: implementation-data-type=VehModMngtGlbSafe1EgyLvlElecSubtyp
        VehModMngtGlbSafe1FltEgyCnsWdSts: implementation-data-type=VehModMngtGlbSafe1FltEgyCnsWdSts
        VehModMngtGlbSafe1PwrLvlElecMai: implementation-data-type=VehModMngtGlbSafe1PwrLvlElecMai
        VehModMngtGlbSafe1PwrLvlElecSubtyp: implementation-data-type=VehModMngtGlbSafe1PwrLvlElecSubtyp
        VehModMngtGlbSafe1UsgModSts: implementation-data-type=VehModMngtGlbSafe1UsgModSts
    VehModMngtGlbSafe1CarModSts1: category=VALUE, base-type=uint8_BMS, compu-method=CarModSts1_1
    VehModMngtGlbSafe1CarModSubtypWdCarModSubtyp: category=VALUE, base-type=uint8_BMS
    VehModMngtGlbSafe1Chks: category=VALUE, base-type=UInt8_2
    VehModMngtGlbSafe1Cntr: category=VALUE, base-type=uint8_BMS
    VehModMngtGlbSafe1EgyLvlElecMai: category=VALUE, base-type=uint8_BMS
    VehModMngtGlbSafe1EgyLvlElecSubtyp: category=VALUE, base-type=uint8_BMS
    VehModMngtGlbSafe1FltEgyCnsWdSts: category=VALUE, base-type=boolean_BMS, compu {0=FltEgyCns1_NoFlt, 1=FltEgyCns1_Flt; unit Unitless}
    VehModMngtGlbSafe1PwrLvlElecMai: category=VALUE, base-type=uint8_BMS
    VehModMngtGlbSafe1PwrLvlElecSubtyp: category=VALUE, base-type=uint8_BMS
    VehModMngtGlbSafe1UsgModSts: category=VALUE, base-type=uint8_BMS, compu-method=UsgModSts1_1
    VehPulseHeatAvl: range raw 0..1, implementation-data-type=uint8
    VehSpdLgt: category=STRUCTURE
      4 x element, all with category=TYPE_REFERENCE:
        VehSpdLgtA: implementation-data-type=VehSpdLgtA
        VehSpdLgtChks: implementation-data-type=VehSpdLgtChks
        VehSpdLgtCntr: implementation-data-type=VehSpdLgtCntr
        VehSpdLgtQf: implementation-data-type=VehSpdLgtQf
    VehSpdLgt_ASW: category=STRUCTURE
      4 x element, all with category=TYPE_REFERENCE:
        VehSpdLgtA_ASW: implementation-data-type=VehSpdLgtA_ASW
        VehSpdLgtChks_ASW: implementation-data-type=VehSpdLgtChks_ASW
        VehSpdLgtCntr_ASW: implementation-data-type=VehSpdLgtCntr_ASW
        VehSpdLgtQf_ASW: implementation-data-type=VehSpdLgtQf_ASW
    VehSpdLgtA: category=VALUE, base-type=uint16_BMS
    VehSpdLgtA_ASW: category=VALUE, base-type=float32_BMS
    VehSpdLgtChks: category=VALUE, base-type=UInt8_2
    VehSpdLgtChks_ASW: category=VALUE, base-type=uint8_BMS
    VehSpdLgtCntr: category=VALUE, base-type=uint8_BMS
    VehSpdLgtCntr_ASW: category=VALUE, base-type=uint8_BMS
    VehSpdLgtQf: category=VALUE, base-type=uint8_BMS, compu-method=GenQf1_1
    VehSpdLgtQf_ASW: category=VALUE, base-type=uint8_BMS
    VFCInfoEna: category=VALUE, base-type=boolean_BMS, compu-method=EnableDisableCoding_1
    VFCVectorBECM: category=STRUCTURE
      63 x element, all with category=TYPE_REFERENCE:
        VFCVectorBECMBlockID: implementation-data-type=VFCVectorBECMBlockID
        VFCVectorBECMVFCid{0..61}: implementation-data-type=VFCVectorBECMVFCid{0..61}
    VFCVectorBECMBlockID: category=VALUE, base-type=uint8_BMS
    VFCVectorBECMVFCid0: category=VALUE, base-type=boolean_BMS, compu {0=VFCOnOff_Off, 1=VFCOnOff_On; unit Unitless}
    VFCVectorBECMVFCid1: category=VALUE, base-type=boolean_BMS, compu {0=VFCOnOff_Off, 1=VFCOnOff_On; unit Unitless}
    VFCVectorBECMVFCid{10..19}: category=VALUE, base-type=boolean_BMS, compu {0=VFCOnOff_Off, 1=VFCOnOff_On; unit Unitless}
    VFCVectorBECMVFCid2: category=VALUE, base-type=boolean_BMS, compu {0=VFCOnOff_Off, 1=VFCOnOff_On; unit Unitless}
    VFCVectorBECMVFCid{20..29}: category=VALUE, base-type=boolean_BMS, compu {0=VFCOnOff_Off, 1=VFCOnOff_On; unit Unitless}
    VFCVectorBECMVFCid3: category=VALUE, base-type=boolean_BMS, compu {0=VFCOnOff_Off, 1=VFCOnOff_On; unit Unitless}
    VFCVectorBECMVFCid{30..39}: category=VALUE, base-type=boolean_BMS, compu {0=VFCOnOff_Off, 1=VFCOnOff_On; unit Unitless}
    VFCVectorBECMVFCid4: category=VALUE, base-type=boolean_BMS, compu {0=VFCOnOff_Off, 1=VFCOnOff_On; unit Unitless}
    VFCVectorBECMVFCid{40..49}: category=VALUE, base-type=boolean_BMS, compu {0=VFCOnOff_Off, 1=VFCOnOff_On; unit Unitless}
    VFCVectorBECMVFCid5: category=VALUE, base-type=boolean_BMS, compu {0=VFCOnOff_Off, 1=VFCOnOff_On; unit Unitless}
    VFCVectorBECMVFCid{50..59}: category=VALUE, base-type=boolean_BMS, compu {0=VFCOnOff_Off, 1=VFCOnOff_On; unit Unitless}
    VFCVectorBECMVFCid6: category=VALUE, base-type=boolean_BMS, compu {0=VFCOnOff_Off, 1=VFCOnOff_On; unit Unitless}
    VFCVectorBECMVFCid60: category=VALUE, base-type=boolean_BMS, compu {0=VFCOnOff_Off, 1=VFCOnOff_On; unit Unitless}
    VFCVectorBECMVFCid61: category=VALUE, base-type=boolean_BMS, compu {0=VFCOnOff_Off, 1=VFCOnOff_On; unit Unitless}
    VFCVectorBECMVFCid{7..9}: category=VALUE, base-type=boolean_BMS, compu {0=VFCOnOff_Off, 1=VFCOnOff_On; unit Unitless}
    Vin: category=ARRAY
      element Element: array-size=8, array-size-semantics=FIXED-SIZE, implementation-data-type=VinElementType
    VinBlockNr_int: implementation-data-type=uint8_BMS, type-emitter=RTE
    VINCode: implementation-data-type=uint8_BMS, type-emitter=RTE
    VINCodeAry: category=ARRAY, sw-calibration-access=READ-ONLY, type-emitter=RTE
      element Element: array-size=17, array-size-semantics=FIXED-SIZE, implementation-data-type=VINCode
    VinElementType: category=VALUE, base-type=Nr2_3
    VinToASW: category=ARRAY
      element Element: array-size=8, array-size-semantics=FIXED-SIZE, range raw 0..255, implementation-data-type=uint8_BMS
    Vlt: implementation-data-type=float32_BMS, type-emitter=RTE
    WakeUpFlg: compu {0=Sleep, 1=WakeUp}, implementation-data-type=boolean_BMS, type-emitter=RTE
    WhlMotSysCooltT: category=VALUE, base-type=HvT1_3
    WhlMotSysUdc: category=VALUE, base-type=uint16_BMS
package /BMS_ASW/Interfaces
  13 x sender receiver interface:
    CarModSts: invalidation-policy{data-element=CarModSts, handle-invalid=DONT-INVALIDATE}
      data CarModSts: sw-calibration-access=READ-WRITE, type=VehModMngtGlbSafe1CarModSts1
    CrashStsSafe: invalidation-policy{data-element=CrashStsSafe, handle-invalid=DONT-INVALIDATE}
      data CrashStsSafe: sw-calibration-access=READ-WRITE, type=CrashStsSafe
    Duty: invalidation-policy{data-element=Duty, handle-invalid=DONT-INVALIDATE}
      data Duty: sw-calibration-access=READ-WRITE, type=Duty
    Flg: invalidation-policy{data-element=boolean, handle-invalid=DONT-INVALIDATE}
      data boolean: sw-calibration-access=READ-WRITE, type=boolean
    FltFlg: invalidation-policy{data-element=FltFlg, handle-invalid=DONT-INVALIDATE}
      data FltFlg: sw-calibration-access=READ-WRITE, type=FltFlg
    Frq: invalidation-policy{data-element=Frq, handle-invalid=DONT-INVALIDATE}
      data Frq: sw-calibration-access=READ-WRITE, type=Frq
    GlbWinSt: invalidation-policy{data-element=GlbWinSt, handle-invalid=DONT-INVALIDATE}
      data GlbWinSt: sw-calibration-access=READ-WRITE, type=uint16_BMS
    HvSysCrashFb: invalidation-policy{data-element=HvSysCrashFb, handle-invalid=DONT-INVALIDATE}
      data HvSysCrashFb: sw-calibration-access=READ-WRITE, type=HvSysCrashFb
    MemQly: invalidation-policy{data-element=MemQly, handle-invalid=DONT-INVALIDATE}
      data MemQly: sw-calibration-access=READ-WRITE, type=MemQly
    SigInvldFlg: invalidation-policy{data-element=SigInvldFlg, handle-invalid=DONT-INVALIDATE}
      data SigInvldFlg: sw-calibration-access=READ-WRITE, type=SigInvldFlg
    SigVldFlg: invalidation-policy{data-element=SigVldFlg, handle-invalid=DONT-INVALIDATE}
      data SigVldFlg: sw-calibration-access=READ-WRITE, type=SigVldFlg
    uint32_BMS: invalidation-policy{data-element=uint32_BMS, handle-invalid=DONT-INVALIDATE}
      data uint32_BMS: sw-calibration-access=READ-WRITE, type=uint32_BMS
    Vlt: invalidation-policy{data-element=Vlt, handle-invalid=DONT-INVALIDATE}
      data Vlt: sw-calibration-access=READ-WRITE, type=Vlt
package /BMS_ASW/Swcs
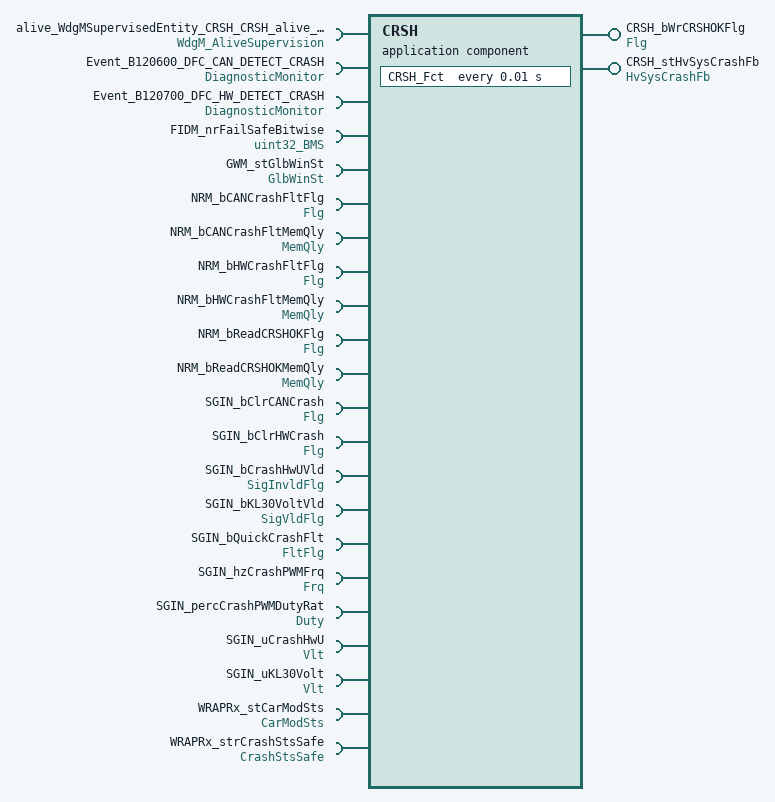
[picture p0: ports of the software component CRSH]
  application sw component type CRSH
    provide port CRSH_bWrCRSHOKFlg: nonqueued-sender-com-spec{data-element=boolean, init-value=0}, provided-interface=Flg
    provide port CRSH_stHvSysCrashFb: nonqueued-sender-com-spec{data-element=HvSysCrashFb, init-value=0}, provided-interface=HvSysCrashFb
    22 x require port:
      alive_WdgMSupervisedEntity_CRSH_CRSH_alive_CP0: client-com-spec=CheckpointReached, required-interface=WdgM_AliveSupervision
      Event_B120600_DFC_CAN_DETECT_CRASH: required-interface=DiagnosticMonitor
        required-com-specs:
          GetDTCOfEvent
          GetEventExtendedDataRecordEx
          GetEventFailed
          GetEventFreezeFrameDataEx
          GetEventStatus
          GetEventTested
          GetEventUdsStatus
          GetFaultDetectionCounter
          ResetEventDebounceStatus
          ResetEventStatus
          SetEventDisabled
          SetEventStatus
      Event_B120700_DFC_HW_DETECT_CRASH: required-interface=DiagnosticMonitor
        required-com-specs:
          GetDTCOfEvent
          GetEventExtendedDataRecordEx
          GetEventFailed
          GetEventFreezeFrameDataEx
          GetEventStatus
          GetEventTested
          GetEventUdsStatus
          GetFaultDetectionCounter
          ResetEventDebounceStatus
          ResetEventStatus
          SetEventDisabled
          SetEventStatus
      FIDM_nrFailSafeBitwise: nonqueued-receiver-com-spec{data-element=uint32_BMS, filter=data-filter-type=ALWAYS, init-value=0}, required-interface=uint32_BMS
      GWM_stGlbWinSt: nonqueued-receiver-com-spec{data-element=GlbWinSt, filter=data-filter-type=ALWAYS, init-value=0}, required-interface=GlbWinSt
      NRM_bCANCrashFltFlg: nonqueued-receiver-com-spec{data-element=boolean, filter=data-filter-type=ALWAYS, init-value=0}, required-interface=Flg
      NRM_bCANCrashFltMemQly: nonqueued-receiver-com-spec{data-element=MemQly, filter=data-filter-type=ALWAYS, init-value=0}, required-interface=MemQly
      NRM_bHWCrashFltFlg: nonqueued-receiver-com-spec{data-element=boolean, filter=data-filter-type=ALWAYS, init-value=0}, required-interface=Flg
      NRM_bHWCrashFltMemQly: nonqueued-receiver-com-spec{data-element=MemQly, filter=data-filter-type=ALWAYS, init-value=0}, required-interface=MemQly
      NRM_bReadCRSHOKFlg: nonqueued-receiver-com-spec{data-element=boolean, filter=data-filter-type=ALWAYS, init-value=0}, required-interface=Flg
      NRM_bReadCRSHOKMemQly: nonqueued-receiver-com-spec{data-element=MemQly, filter=data-filter-type=ALWAYS, init-value=0}, required-interface=MemQly
      SGIN_bClrCANCrash: nonqueued-receiver-com-spec{data-element=boolean, filter=data-filter-type=ALWAYS, init-value=0}, required-interface=Flg
      SGIN_bClrHWCrash: nonqueued-receiver-com-spec{data-element=boolean, filter=data-filter-type=ALWAYS, init-value=0}, required-interface=Flg
      SGIN_bCrashHwUVld: nonqueued-receiver-com-spec{data-element=SigInvldFlg, filter=data-filter-type=ALWAYS, init-value=0}, required-interface=SigInvldFlg
      SGIN_bKL30VoltVld: nonqueued-receiver-com-spec{data-element=SigVldFlg, filter=data-filter-type=ALWAYS, init-value=0}, required-interface=SigVldFlg
      SGIN_bQuickCrashFlt: nonqueued-receiver-com-spec{data-element=FltFlg, filter=data-filter-type=ALWAYS, init-value=0}, required-interface=FltFlg
      SGIN_hzCrashPWMFrq: nonqueued-receiver-com-spec{data-element=Frq, filter=data-filter-type=ALWAYS, init-value=0}, required-interface=Frq
      SGIN_percCrashPWMDutyRat: nonqueued-receiver-com-spec{data-element=Duty, filter=data-filter-type=ALWAYS, init-value=0}, required-interface=Duty
      SGIN_uCrashHwU: nonqueued-receiver-com-spec{data-element=Vlt, filter=data-filter-type=ALWAYS, init-value=0}, required-interface=Vlt
      SGIN_uKL30Volt: nonqueued-receiver-com-spec{data-element=Vlt, filter=data-filter-type=ALWAYS, init-value=0}, required-interface=Vlt
      WRAPRx_stCarModSts: nonqueued-receiver-com-spec{data-element=CarModSts, filter=data-filter-type=ALWAYS, init-value=0}, required-interface=CarModSts
      WRAPRx_strCrashStsSafe: nonqueued-receiver-com-spec{data-element=CrashStsSafe, filter=data-filter-type=ALWAYS, init-value=fields=[CrashStsSafeChks:255, CrashStsSafeCntr:0, CrashStsSafeSts:0]}, required-interface=CrashStsSafe
    behavior CRSH: data-type-mapping=[BMS_Map, defaultDataTypeMappingSet_CPFS, BMS_Map_1]
      timing event teCRSH10ms: start-on-event=CRSH_Fct, period=0.01
      runnable CRSH_Fct
        data-receive-point-by-arguments:
          19 x access:
            FIDM_nrFailSafeBitwise: accessed-variable=FIDM_nrFailSafeBitwise.uint32_BMS
            GWM_stGlbWinSt: accessed-variable=GWM_stGlbWinSt.GlbWinSt
            NRM_bCANCrashFltFlg: accessed-variable=NRM_bCANCrashFltFlg.boolean
            NRM_bCANCrashFltMemQly: accessed-variable=NRM_bCANCrashFltMemQly.MemQly
            NRM_bHWCrashFltFlg: accessed-variable=NRM_bHWCrashFltFlg.boolean
            NRM_bHWCrashFltMemQly: accessed-variable=NRM_bHWCrashFltMemQly.MemQly
            NRM_bReadCRSHOKFlg: accessed-variable=NRM_bReadCRSHOKFlg.boolean
            NRM_bReadCRSHOKMemQly: accessed-variable=NRM_bReadCRSHOKMemQly.MemQly
            SGIN_bClrCANCrash: accessed-variable=SGIN_bClrCANCrash.boolean
            SGIN_bClrHWCrash: accessed-variable=SGIN_bClrHWCrash.boolean
            SGIN_bCrashHwUVld: accessed-variable=SGIN_bCrashHwUVld.SigInvldFlg
            SGIN_bKL30VoltVld: accessed-variable=SGIN_bKL30VoltVld.SigVldFlg
            SGIN_bQuickCrashFlt: accessed-variable=SGIN_bQuickCrashFlt.FltFlg
            SGIN_hzCrashPWMFrq: accessed-variable=SGIN_hzCrashPWMFrq.Frq
            SGIN_percCrashPWMDutyRat: accessed-variable=SGIN_percCrashPWMDutyRat.Duty
            SGIN_uCrashHwU: accessed-variable=SGIN_uCrashHwU.Vlt
            SGIN_uKL30Volt: accessed-variable=SGIN_uKL30Volt.Vlt
            WRAPRx_stCarModSts: accessed-variable=WRAPRx_stCarModSts.CarModSts
            WRAPRx_strCrashStsSafe: accessed-variable=WRAPRx_strCrashStsSafe.CrashStsSafe
        data-send-points:
          access CRSH_bWrCRSHOKFlg: accessed-variable=CRSH_bWrCRSHOKFlg.boolean
          access CRSH_stHvSysCrashFb: accessed-variable=CRSH_stHvSysCrashFb.HvSysCrashFb
        sync call alive_WdgMSupervisedEntity_CRSH_CRSH_alive_CP0: operation=alive_WdgMSupervisedEntity_CRSH_CRSH_alive_CP0.CheckpointReached, timeout=0
        sync call SC_Event_B120600_DFC_CAN_DETECT_CRASH_SetEventStatus: operation=Event_B120600_DFC_CAN_DETECT_CRASH.SetEventStatus, timeout=0
        sync call SC_Event_B120700_DFC_HW_DETECT_CRASH_SetEventStatus: operation=Event_B120700_DFC_HW_DETECT_CRASH.SetEventStatus, timeout=0
  swc implementation CRSH_Implementation: behavior=CRSH
    code-descriptors:
      code Default: artifact-descriptors=autosar-engineering-object={short-label=Default, category=SWSRC}
package /BMS_ASW/Unit
  24 x unit, all with offset-si-to-unit=0:
    Ah: display-name=Ah, factor-si-to-unit=1
    Ampr: display-name=A, factor-si-to-unit=1
    cAh: display-name=cAh, factor-si-to-unit=1
    degC: display-name=degC, factor-si-to-unit=1
    dimi: display-name=?, factor-si-to-unit=10000  # one ten-thousandth
    Figure: display-name=figure, factor-si-to-unit=1
    Hz: display-name=Hz, factor-si-to-unit=1
    kOhm: display-name=kOhm, factor-si-to-unit=1
    kPa: factor-si-to-unit=1
    LPerMins: display-name=L / min, factor-si-to-unit=1
    mA: display-name=mA, factor-si-to-unit=1
    mAh: display-name=mAh, factor-si-to-unit=1
    mAs: display-name=mAs, factor-si-to-unit=1
    Min: display-name=min, factor-si-to-unit=1
    mVolt: display-name=mV, factor-si-to-unit=1
    NoUint: factor-si-to-unit=1
    Perc: display-name=%, factor-si-to-unit=1
    Press: display-name=Pa, factor-si-to-unit=1
    s: display-name=s, factor-si-to-unit=1
    Ver: display-name=ver, factor-si-to-unit=1
    Volt: display-name=V, factor-si-to-unit=1
    W: display-name=W, factor-si-to-unit=1
    Wh: display-name=Wh, factor-si-to-unit=1
    ZeroPointOneDegC: display-name=0.1degC, factor-si-to-unit=1
package /BSW/XcpCan/ImplementationDataTypes
  impl type CellUMaxId: implementation-data-type=uint8
package /BSWInterfaces/ApplicationDataTypes
  application array data type SecurityFixedByteArray: category=ARRAY, sw-calibration-access=READ-ONLY
    element Element: category=VALUE, type=uint8_BMS, array-size-semantics=FIXED-SIZE, max-number-of-elements=5
  5 x app type, all with category=VALUE:
    CellUMaxId: compu {phys=raw for raw 0..250; unit Unitless}
    DchaPwrAllwd_ASW: sw-calibration-access=READ-ONLY
    HvBattChrgnPwrAllwd1_ASW: sw-calibration-access=READ-ONLY
    PNC_NM_Status: sw-calibration-access=READ-ONLY, compu {0=COMM_PNC_NO_COMMUNICATION (CompuScale), 1=COMM_PNC_PREPARE_SLEEP (CompuScale), 2=COMM_PNC_READY_SLEEP (CompuScale), 3=COMM_PNC_REQUESTED (CompuScale), 4=COMM_PNC_REQUESTED_PASSIVE (CompuScale)}
    uint8: sw-calibration-access=READ-ONLY, compu {phys=raw for raw 0..255}
  application record data type strSecurityAccessAttemptCounter05: category=STRUCTURE, sw-calibration-access=READ-ONLY
    application record element SecurityAccessAttemptCounter05: category=VALUE, type=uint8_BMS
  application record data type strSecurityAccessAttemptCounter19: category=STRUCTURE, sw-calibration-access=READ-ONLY
    application record element SecurityAccessAttemptCounter19: category=VALUE, type=uint8_BMS
  application record data type strSecurityFixedByte19: category=STRUCTURE, sw-calibration-access=READ-ONLY
    application record element SecurityFixedByte19: category=ARRAY, type=SecurityFixedByteArray
    application record element Status: category=VALUE, type=uint8
package /BSWInterfaces/ImplementationDataTypes
  7 x impl type:
    DchaPwrAllwd_ASW: implementation-data-type=float32_BMS
    HvBattChrgnPwrAllwd1_ASW: implementation-data-type=float32_BMS
    PNC_NM_Status: range raw 0..255, implementation-data-type=uint8, type-emitter=RTE
    SecurityFixedByteArray: category=ARRAY, sw-calibration-access=READ-ONLY, type-emitter=RTE
      element SecurityFixedByteArray: array-size=5, array-size-semantics=FIXED-SIZE, implementation-data-type=uint8_BMS
    strSecurityAccessAttemptCounter05: category=STRUCTURE, sw-calibration-access=READ-ONLY, type-emitter=RTE
      element SecurityAccessAttemptCounter05: implementation-data-type=uint8_BMS
    strSecurityAccessAttemptCounter19: category=STRUCTURE, sw-calibration-access=READ-ONLY, type-emitter=RTE
      element SecurityAccessAttemptCounter19: implementation-data-type=uint8_BMS
    strSecurityFixedByte19: category=STRUCTURE, sw-calibration-access=READ-ONLY, type-emitter=RTE
      element SecurityFixedByte19: implementation-data-type=SecurityFixedByteArray
      element Status: implementation-data-type=uint8_BMS
package /BSWInterfaces/Units
  4 x unit, all with offset-si-to-unit=0:
    A: display-name=A, factor-si-to-unit=1
    No: display-name=-, factor-si-to-unit=1
    NoUnit: factor-si-to-unit=1
    V: display-name=V, factor-si-to-unit=0.1
package /CEVT/SharedElements/Units
  unit Ohm: display-name=Ohm, factor-si-to-unit=1, offset-si-to-unit=0
package /ComponentTypes/DataTypeMappingSets
  data type mapping set BMS_Map
  data type mapping set BMS_Map_1
    data-type-maps:
      application-data-type=VehCfgPrm_3, implementation-data-type=VehCfgPrm_3
      application-data-type=VehModMngtGlbSafe1_2, implementation-data-type=VehModMngtGlbSafe1_2
      application-data-type=AcChrgEgywh, implementation-data-type=AcChrgEgywh
      application-data-type=AcChrgnSts, implementation-data-type=AcChrgnSts
      application-data-type=AcChrgnToTar, implementation-data-type=AcChrgnToTar
      application-data-type=AcChrgPwrw, implementation-data-type=AcChrgPwrw
      application-data-type=AcMod, implementation-data-type=AcMod
      application-data-type=AcReqCurr, implementation-data-type=AcReqCurr
      application-data-type=AcReqVlt, implementation-data-type=AcReqVlt
      application-data-type=ActvFlg, implementation-data-type=ActvFlg
      application-data-type=AfeMdCtrl, implementation-data-type=AfeMdCtrl
      application-data-type=AfeStsFd, implementation-data-type=AfeStsFd
      application-data-type=AhCp, implementation-data-type=AhCp
      application-data-type=AhCpAry, implementation-data-type=AhCpAry
      application-data-type=AmbTEstimd_ASW, implementation-data-type=AmbTEstimd_ASW
      application-data-type=AmbTEstimdAmbTEstimd_ASW, implementation-data-type=AmbTEstimdAmbTEstimd_ASW
      application-data-type=AmbTEstimdQf_ASW, implementation-data-type=AmbTEstimdQf_ASW
      application-data-type=AmbTRaw_ASW, implementation-data-type=AmbTRaw_ASW
      application-data-type=AmbTRawAmbTVal_ASW, implementation-data-type=AmbTRawAmbTVal_ASW
      application-data-type=AmbTRawQly_ASW, implementation-data-type=AmbTRawQly_ASW
      application-data-type=AswCellTmp, implementation-data-type=AswCellTmp
      application-data-type=AswCellTmpAry, implementation-data-type=AswCellTmpAry
      application-data-type=AswCellVlt, implementation-data-type=AswCellVlt
      application-data-type=AswCellVltAry, implementation-data-type=AswCellVltAry
      application-data-type=AswCscTmp, implementation-data-type=AswCscTmp
      application-data-type=AswCscTmpAry, implementation-data-type=AswCscTmpAry
      application-data-type=AswCscVoltAry, implementation-data-type=AswCscVoltAry
      application-data-type=BalOperMod, implementation-data-type=BalOperMod
      application-data-type=BalTiCalcMod, implementation-data-type=BalTiCalcMod
      application-data-type=BATIOperMod, implementation-data-type=BATIOperMod
      application-data-type=BattClimaPwr, implementation-data-type=BattClimaPwr
      application-data-type=BclCurrReq, implementation-data-type=BclCurrReq
      application-data-type=BclVoltReq, implementation-data-type=BclVoltReq
      application-data-type=BcpBattNomEgy, implementation-data-type=BcpBattNomEgy
      application-data-type=BecmDcChgRlyCmd, implementation-data-type=BecmDcChgRlyCmd
      application-data-type=BkpOfDstTrvld_ASW, implementation-data-type=BkpOfDstTrvld_ASW
      application-data-type=BMSSts, implementation-data-type=BMSSts
      application-data-type=BookChrgTarValLnr, implementation-data-type=BookChrgTarValLnr
      application-data-type=BookChrgTarValLnr_ASW, implementation-data-type=BookChrgTarValLnr_ASW
      application-data-type=boolean, implementation-data-type=ImplementationDataTypes/boolean
      application-data-type=BpsOverAbsThresholdFlgH, implementation-data-type=BpsOverAbsThresholdFlgH
      application-data-type=BpsOverAbsThresholdFlgH_ASW, implementation-data-type=BpsOverAbsThresholdFlgH_ASW
      application-data-type=BpsOverAbsThresholdFlgL, implementation-data-type=BpsOverAbsThresholdFlgL
      application-data-type=BpsOverAbsThresholdFlgL_ASW, implementation-data-type=BpsOverAbsThresholdFlgL_ASW
      application-data-type=BpsOverSlopeThresholdFlgH, implementation-data-type=BpsOverSlopeThresholdFlgH
      application-data-type=BpsOverSlopeThresholdFlgH_ASW, implementation-data-type=BpsOverSlopeThresholdFlgH_ASW
      application-data-type=BpsOverSlopeThresholdFlgL, implementation-data-type=BpsOverSlopeThresholdFlgL
      application-data-type=BpsOverSlopeThresholdFlgL_ASW, implementation-data-type=BpsOverSlopeThresholdFlgL_ASW
      application-data-type=BpsPressureDataH, implementation-data-type=BpsPressureDataH
      application-data-type=BpsPressureDataH_ASW, implementation-data-type=BpsPressureDataH_ASW
      application-data-type=BpsPressureDataL, implementation-data-type=BpsPressureDataL
      application-data-type=BpsPressureDataL_ASW, implementation-data-type=BpsPressureDataL_ASW
      application-data-type=BrmSysRateCp, implementation-data-type=BrmSysRateCp
      application-data-type=BswCellTmp, implementation-data-type=BswCellTmp
      application-data-type=BswCellTmpAry, implementation-data-type=BswCellTmpAry
      application-data-type=BswCellVlt, implementation-data-type=BswCellVlt
      application-data-type=BswCellVltAry, implementation-data-type=BswCellVltAry
      application-data-type=BswCscVolt, implementation-data-type=BswCscVolt
      application-data-type=BswCscVoltAry, implementation-data-type=BswCscVoltAry
      application-data-type=CarCfgInValVal, implementation-data-type=CarCfgInValVal
      application-data-type=CarCfgModSts, implementation-data-type=CarCfgModSts
      application-data-type=CarTiGlb_ASW, implementation-data-type=CarTiGlb_ASW
      application-data-type=CeBRActvDIDAry, implementation-data-type=CeBRActvDIDAry
      application-data-type=CellmAh, implementation-data-type=CellmAh
      application-data-type=CellmAhAry, implementation-data-type=CellmAhAry
      application-data-type=cellsocperc, implementation-data-type=cellsocperc
      application-data-type=CellTVldAry, implementation-data-type=CellTVldAry
      application-data-type=CellUSamplBrkAry, implementation-data-type=CellUSamplBrkAry
      application-data-type=CellVlt, implementation-data-type=CellVlt
      application-data-type=CellVoltVldAry, implementation-data-type=CellVoltVldAry
      application-data-type=CfgInValPosn, implementation-data-type=CfgInValPosn
      application-data-type=CfgPrmVal, implementation-data-type=CfgPrmVal
      application-data-type=Chks, implementation-data-type=Chks
      application-data-type=ChrgEquipIDcL2, implementation-data-type=ChrgEquipIDcL2
      application-data-type=ChrgEquipIDcL2_ASW, implementation-data-type=ChrgEquipIDcL2_ASW
      application-data-type=ChrgnSts, implementation-data-type=ChrgnSts
      application-data-type=ChrgSts, implementation-data-type=ChrgSts
      application-data-type=CM_SetEventStatus, implementation-data-type=CM_SetEventStatus
      application-data-type=Cmd, implementation-data-type=Cmd
      application-data-type=CmplFlg, implementation-data-type=CmplFlg
      application-data-type=Cntr, implementation-data-type=Cntr
      application-data-type=cofshnt, implementation-data-type=cofshnt
      application-data-type=ComQly, implementation-data-type=ComQly
      application-data-type=CoolgLvlReq, implementation-data-type=CoolgLvlReq
      application-data-type=CooltFlow, implementation-data-type=CooltFlow
      application-data-type=CooltLvlFlg, implementation-data-type=CooltLvlFlg
      application-data-type=CooltTSigForDtElec_ASW, implementation-data-type=CooltTSigForDtElec_ASW
      application-data-type=CpInmAs, implementation-data-type=CpInmAs
      application-data-type=CpInmAsAry, implementation-data-type=CpInmAsAry
      application-data-type=CPSRFallFlg, implementation-data-type=CPSRFallFlg
      application-data-type=CscBdTVldAry, implementation-data-type=CscBdTVldAry
      application-data-type=CurrtInA, implementation-data-type=CurrtInA
      application-data-type=CurrtInmA, implementation-data-type=CurrtInmA
      application-data-type=DCChaPwrAct, implementation-data-type=DCChaPwrAct
      application-data-type=DCChaPwrAct_ASW, implementation-data-type=DCChaPwrAct_ASW
      application-data-type=DCChgRlyStuckDetct, implementation-data-type=DCChgRlyStuckDetct
      application-data-type=DCChgStopSTS, implementation-data-type=DCChgStopSTS
      application-data-type=DCChrgnHndlSts, implementation-data-type=DCChrgnHndlSts
      application-data-type=DcChrgnOn, implementation-data-type=DcChrgnOn
      application-data-type=DCChrgSt_ASW, implementation-data-type=DCChrgSt_ASW
      application-data-type=DchaPwrAllwd, implementation-data-type=DchaPwrAllwd
      application-data-type=DchrgnIntSckState, implementation-data-type=DchrgnIntSckState
      application-data-type=DchrgnIntState, implementation-data-type=DchrgnIntState
      application-data-type=DChrgTarValLnr, implementation-data-type=DChrgTarValLnr
      application-data-type=DChrgTarValLnr_ASW, implementation-data-type=DChrgTarValLnr_ASW
      application-data-type=DCPreHeatgReq, implementation-data-type=DCPreHeatgReq
      application-data-type=DemFltSts, implementation-data-type=DemFltSts
      application-data-type=DispHvBattLvlOfChrg, implementation-data-type=DispHvBattLvlOfChrg
      application-data-type=DispHvBattLvlOfChrg_ASW, implementation-data-type=DispHvBattLvlOfChrg_ASW
      application-data-type=Duty, implementation-data-type=Duty
      application-data-type=Egyah, implementation-data-type=Egyah
      application-data-type=Egykwh, implementation-data-type=Egykwh
      application-data-type=Egywh, implementation-data-type=Egywh
      application-data-type=Egywh_uint32, implementation-data-type=Egywh_uint32
      application-data-type=EngAmbTCalcd_ASW, implementation-data-type=EngAmbTCalcd_ASW
      application-data-type=EngNSafe_ASW, implementation-data-type=EngNSafe_ASW
      application-data-type=EngNSafeEngN_ASW, implementation-data-type=EngNSafeEngN_ASW
      application-data-type=EngNSafeEngNGrdt_ASW, implementation-data-type=EngNSafeEngNGrdt_ASW
      application-data-type=EngT_ASW, implementation-data-type=EngT_ASW
      application-data-type=EngTiOn_ASW, implementation-data-type=EngTiOn_ASW
      application-data-type=EolMod, implementation-data-type=EolMod
      application-data-type=EOLSts, implementation-data-type=EOLSts
      application-data-type=EstimPwr, implementation-data-type=EstimPwr
      application-data-type=Factor, implementation-data-type=Factor
      application-data-type=FastChrgnLEDIndctn, implementation-data-type=FastChrgnLEDIndctn
      application-data-type=FastChrgnLockCtrl, implementation-data-type=FastChrgnLockCtrl
      application-data-type=filmHeatingSts, implementation-data-type=filmHeatingSts
      application-data-type=FlgAry, implementation-data-type=FlgAry
      application-data-type=float32_BMS_2, implementation-data-type=float32_BMS_2
      application-data-type=FltFlg, implementation-data-type=FltFlg
      application-data-type=FltLvl, implementation-data-type=FltLvl
      application-data-type=Frq, implementation-data-type=Frq
      application-data-type=GBCodeArray, implementation-data-type=GBCodeArray
      application-data-type=GpsStatus, implementation-data-type=GpsStatus
      application-data-type=HeatGen, implementation-data-type=HeatGen
      application-data-type=HeatgLvlReq, implementation-data-type=HeatgLvlReq
      application-data-type=HeatModReq, implementation-data-type=HeatModReq
      application-data-type=HiVlt, implementation-data-type=HiVlt
      application-data-type=HsdFlt, implementation-data-type=HsdFlt
      application-data-type=HSDMod, implementation-data-type=HSDMod
      application-data-type=HSDPort, implementation-data-type=HSDPort
      application-data-type=HSDPortAry, implementation-data-type=HSDPortAry
      application-data-type=HvAuxActPwr, implementation-data-type=HvAuxActPwr
      application-data-type=HvBattChrgnCmd, implementation-data-type=HvBattChrgnCmd
      application-data-type=HvBattChrgnILim, implementation-data-type=HvBattChrgnILim
      application-data-type=HvBattChrgnPwrAllwd1, implementation-data-type=HvBattChrgnPwrAllwd1
      application-data-type=HvBattCoolgEgyCnsAllwd1_ASW, implementation-data-type=HvBattCoolgEgyCnsAllwd1_ASW
      application-data-type=HvBattFlwEstmd_ASW, implementation-data-type=HvBattFlwEstmd_ASW
      application-data-type=HvBattLimnIndcn, implementation-data-type=HvBattLimnIndcn
      application-data-type=HvBattPulseHeatSts, implementation-data-type=HvBattPulseHeatSts
      application-data-type=HvBattThermInfoInFuture, implementation-data-type=HvBattThermInfoInFuture
      application-data-type=HvBattThermInfoInFuture_ASW, implementation-data-type=HvBattThermInfoInFuture_ASW
      application-data-type=HvBattThermInfoInFuturePwrAtTime, implementation-data-type=HvBattThermInfoInFuturePwrAtTime
      application-data-type=HvBattThermInfoInFuturePwrAtTime_ASW, implementation-data-type=HvBattThermInfoInFuturePwrAtTime_ASW
      application-data-type=HvBattThermInfoInFutureSequenceNo, implementation-data-type=HvBattThermInfoInFutureSequenceNo
      application-data-type=HvBattThermInfoInFutureSequenceNo_ASW, implementation-data-type=HvBattThermInfoInFutureSequenceNo_ASW
      application-data-type=HvBattThermInfoInFutureTempAtTime, implementation-data-type=HvBattThermInfoInFutureTempAtTime
      application-data-type=HvBattThermInfoInFutureTempAtTime_ASW, implementation-data-type=HvBattThermInfoInFutureTempAtTime_ASW
      application-data-type=HvBattThermInfoInFutureThermModAtTime, implementation-data-type=HvBattThermInfoInFutureThermModAtTime
      application-data-type=HvBattThermInfoInFutureThermModAtTime_ASW, implementation-data-type=HvBattThermInfoInFutureThermModAtTime_ASW
      application-data-type=HvBattThermInfoInFutureTime, implementation-data-type=HvBattThermInfoInFutureTime
      application-data-type=HvBattThermInfoInFutureTime_ASW, implementation-data-type=HvBattThermInfoInFutureTime_ASW
      application-data-type=HvBattThermInfoInFutureVersionNo, implementation-data-type=HvBattThermInfoInFutureVersionNo
      application-data-type=HvBattThermInfoInFutureVersionNo_ASW, implementation-data-type=HvBattThermInfoInFutureVersionNo_ASW
      application-data-type=HVCCOperMod, implementation-data-type=HVCCOperMod
      application-data-type=HvchSts, implementation-data-type=HvchSts
      application-data-type=HVCnctSts, implementation-data-type=HVCnctSts
      application-data-type=HVILSts, implementation-data-type=HVILSts
      application-data-type=HvOnMaiReq, implementation-data-type=HvOnMaiReq
      application-data-type=HVSts, implementation-data-type=HVSts
      application-data-type=HvSysActvnInhb, implementation-data-type=HvSysActvnInhb
      application-data-type=HvSysLimnIndcn, implementation-data-type=HvSysLimnIndcn
      application-data-type=Index, implementation-data-type=Index
      application-data-type=InfoVers, implementation-data-type=InfoVers
      application-data-type=IntegritTestSts, implementation-data-type=IntegritTestSts
      application-data-type=IsgCooltT_ASW, implementation-data-type=IsgCooltT_ASW
      application-data-type=IsgUDc_ASW, implementation-data-type=IsgUDc_ASW
      application-data-type=IsgVehPulseHeatModSts, implementation-data-type=IsgVehPulseHeatModSts
      application-data-type=IsoCrshSts, implementation-data-type=IsoCrshSts
      application-data-type=IsoDIDWrResSts, implementation-data-type=IsoDIDWrResSts
      application-data-type=IsoFlt, implementation-data-type=IsoFlt
      application-data-type=IsoFltSts, implementation-data-type=IsoFltSts
      application-data-type=IsoMod, implementation-data-type=IsoMod
      application-data-type=IsoSts, implementation-data-type=IsoSts
      application-data-type=KalP, implementation-data-type=KalP
      application-data-type=KalPAry, implementation-data-type=KalPAry
      application-data-type=LoadValCalcd_ASW, implementation-data-type=LoadValCalcd_ASW
      application-data-type=LoDCChrgSt, implementation-data-type=LoDCChrgSt
      application-data-type=LosLimnIndcn, implementation-data-type=LosLimnIndcn
      application-data-type=LowVlt, implementation-data-type=LowVlt
      application-data-type=LsdFlt, implementation-data-type=LsdFlt
      application-data-type=MaintainBattTCtrl, implementation-data-type=MaintainBattTCtrl
      application-data-type=MemQly, implementation-data-type=MemQly
      application-data-type=MntnBattTFbSts, implementation-data-type=MntnBattTFbSts
      application-data-type=MntnBattTTimin, implementation-data-type=MntnBattTTimin
      application-data-type=MonrSts, implementation-data-type=MonrSts
      application-data-type=MultiCurrt, implementation-data-type=MultiCurrt
      application-data-type=nrAFERstAry, implementation-data-type=nrAFERstAry
      application-data-type=nrCurRange, implementation-data-type=nrCurRange
      application-data-type=Number, implementation-data-type=Number
      application-data-type=OdpDcChgRlyState, implementation-data-type=OdpDcChgRlyState
      application-data-type=Ohm_HVIL, implementation-data-type=Ohm_HVIL
      application-data-type=OnBdChrgrCurrA, implementation-data-type=OnBdChrgrCurrA
      application-data-type=OnBdChrgrHndlSts1, implementation-data-type=OnBdChrgrHndlSts1
      application-data-type=OnBdChrgrIDc, implementation-data-type=OnBdChrgrIDc
      application-data-type=OnBdChrgrSt, implementation-data-type=OnBdChrgrSt
      application-data-type=OnBdChrgrUDc, implementation-data-type=OnBdChrgrUDc
      application-data-type=OnBdIntDischrgrSt, implementation-data-type=OnBdIntDischrgrSt
      application-data-type=OnOffNoReq, implementation-data-type=OnOffNoReq
      application-data-type=OperMod, implementation-data-type=OperMod
      application-data-type=PackAirPVal, implementation-data-type=PackAirPVal
      application-data-type=PakRes, implementation-data-type=PakRes
      application-data-type=PCHMSts, implementation-data-type=PCHMSts
      application-data-type=Perc, implementation-data-type=Perc
      application-data-type=PreHeatgReq, implementation-data-type=PreHeatgReq
      application-data-type=PreHeatSts, implementation-data-type=PreHeatSts
      application-data-type=PreSocOperMod, implementation-data-type=PreSocOperMod
      application-data-type=PressfloatVal, implementation-data-type=PressfloatVal
      application-data-type=PressVal, implementation-data-type=PressVal
      application-data-type=PulseHeatTsts, implementation-data-type=PulseHeatTsts
      application-data-type=Pwr, implementation-data-type=Pwr
      application-data-type=PwrEgyMgrAvl, implementation-data-type=PwrEgyMgrAvl
      application-data-type=RlyCur, implementation-data-type=RlyCur
      application-data-type=RlyCurAry, implementation-data-type=RlyCurAry
      application-data-type=RlySts, implementation-data-type=RlySts
      application-data-type=RoutCtlFlg, implementation-data-type=RoutCtlFlg
      application-data-type=RTCSleepTi, implementation-data-type=RTCSleepTi
      application-data-type=RTCTi, implementation-data-type=RTCTi
      application-data-type=Rval, implementation-data-type=Rval
      application-data-type=SbcSafeStFlg, implementation-data-type=SbcSafeStFlg
      application-data-type=SeqNr, implementation-data-type=SeqNr
      application-data-type=SigInvldFlg, implementation-data-type=SigInvldFlg
      application-data-type=SigQly, implementation-data-type=SigQly
      application-data-type=SigVldFlg, implementation-data-type=SigVldFlg
      application-data-type=SocOperMod, implementation-data-type=SocOperMod
      application-data-type=SocPercAry, implementation-data-type=SocPercAry
      application-data-type=SohPerc, implementation-data-type=SohPerc
      application-data-type=SohPercAry, implementation-data-type=SohPercAry
      application-data-type=strAbsltCp, implementation-data-type=strAbsltCp
      application-data-type=strACCH, implementation-data-type=strACCH
      application-data-type=strAFERest, implementation-data-type=strAFERest
      application-data-type=strBalFinishTimes, implementation-data-type=strBalFinishTimes
      application-data-type=strBalTiCalcMod, implementation-data-type=strBalTiCalcMod
      application-data-type=strBalTotTime, implementation-data-type=strBalTotTime
      application-data-type=strbEKFdisabled, implementation-data-type=strbEKFdisabled
      application-data-type=strBookChrgTarValLnr, implementation-data-type=strBookChrgTarValLnr
      application-data-type=strCANCrashFlt, implementation-data-type=strCANCrashFlt
      application-data-type=strCarCfgInVal, implementation-data-type=strCarCfgInVal
      application-data-type=strCpCalcnIniSoc, implementation-data-type=strCpCalcnIniSoc
      application-data-type=strCpCalcnStrt, implementation-data-type=strCpCalcnStrt
      application-data-type=strCpExt, implementation-data-type=strCpExt
      application-data-type=strCpMeasTot, implementation-data-type=strCpMeasTot
      application-data-type=strCRAHOK, implementation-data-type=strCRAHOK
      application-data-type=strCrashEvent, implementation-data-type=strCrashEvent
      application-data-type=strCurrtInA, implementation-data-type=strCurrtInA
      application-data-type=strDisKal, implementation-data-type=strDisKal
      application-data-type=strElecDrvLinePrm, implementation-data-type=strElecDrvLinePrm
      application-data-type=strElecVehInletPrm, implementation-data-type=strElecVehInletPrm
      application-data-type=strfacKalP, implementation-data-type=strfacKalP
      application-data-type=strFidStopSafely, implementation-data-type=strFidStopSafely
      application-data-type=strFlg, implementation-data-type=strFlg
      application-data-type=strHvBattOptmzHintForSoc, implementation-data-type=strHvBattOptmzHintForSoc
      application-data-type=strHvBattSoc, implementation-data-type=strHvBattSoc
      application-data-type=strHvNegRlyCur, implementation-data-type=strHvNegRlyCur
      application-data-type=strHvPosRlyCur, implementation-data-type=strHvPosRlyCur
      application-data-type=strHVRlyRemLife, implementation-data-type=strHVRlyRemLife
      application-data-type=strHWCrashFlt, implementation-data-type=strHWCrashFlt
      application-data-type=strPrecRlyClsToOpen, implementation-data-type=strPrecRlyClsToOpen
      application-data-type=strRelCp, implementation-data-type=strRelCp
      application-data-type=strRlyClsToOpen, implementation-data-type=strRlyClsToOpen
      application-data-type=strRlyOpenTimes, implementation-data-type=strRlyOpenTimes
      application-data-type=strRlyVltDrpAbnrmCnt, implementation-data-type=strRlyVltDrpAbnrmCnt
      application-data-type=strRTC, implementation-data-type=strRTC
      application-data-type=strShutCalAByUDS, implementation-data-type=strShutCalAByUDS
      application-data-type=strShutCalBByUDS, implementation-data-type=strShutCalBByUDS
      application-data-type=strShutCalCByUDS, implementation-data-type=strShutCalCByUDS
      application-data-type=strShutCalR25ByUDS, implementation-data-type=strShutCalR25ByUDS
      application-data-type=strShutDown, implementation-data-type=strShutDown
      application-data-type=strSocPercAry, implementation-data-type=strSocPercAry
      application-data-type=strSOCRangeLearn, implementation-data-type=strSOCRangeLearn
      application-data-type=strSocStorage, implementation-data-type=strSocStorage
      application-data-type=strSoeStorage, implementation-data-type=strSoeStorage
      application-data-type=strTimePeriod, implementation-data-type=strTimePeriod
      application-data-type=strTimeRemain, implementation-data-type=strTimeRemain
      application-data-type=strTotChrgDischTime, implementation-data-type=strTotChrgDischTime
      application-data-type=strTotSingleChrgEgy, implementation-data-type=strTotSingleChrgEgy
      application-data-type=strVINCode, implementation-data-type=strVINCode
      application-data-type=stsAFEFltSts, implementation-data-type=stsAFEFltSts
      application-data-type=stsPNCStatus, implementation-data-type=stsPNCStatus
      application-data-type=SwtSts, implementation-data-type=SwtSts
      application-data-type=SwtStsAry, implementation-data-type=SwtStsAry
      application-data-type=TelmHVBattPlsHeatgReq, implementation-data-type=TelmHVBattPlsHeatgReq
      application-data-type=ThermRunawayWakeUpCntr, implementation-data-type=ThermRunawayWakeUpCntr
      application-data-type=THMDOperMod, implementation-data-type=THMDOperMod
      application-data-type=ThrPos_ASW, implementation-data-type=ThrPos_ASW
      application-data-type=TimeInMin, implementation-data-type=TimeInMin
      application-data-type=TimeInSec, implementation-data-type=TimeInSec
      application-data-type=TimeInSecAry, implementation-data-type=TimeInSecAry
      application-data-type=Tmp, implementation-data-type=Tmp
      application-data-type=TotChrgDischTime, implementation-data-type=TotChrgDischTime
      application-data-type=TotSingleChrgEgy, implementation-data-type=TotSingleChrgEgy
      application-data-type=TotSingleChrgEgy_ASW, implementation-data-type=TotSingleChrgEgy_ASW
      application-data-type=TrsmVehSpd_ASW, implementation-data-type=TrsmVehSpd_ASW
      application-data-type=uint16_BMS, implementation-data-type=uint16_BMS
      application-data-type=uint32_BMS, implementation-data-type=uint32_BMS
      application-data-type=uint8_BMS, implementation-data-type=uint8_BMS
      application-data-type=VehBattU_ASW, implementation-data-type=VehBattU_ASW
      application-data-type=VehCfgPrmToASW, implementation-data-type=VehCfgPrmToASW
      application-data-type=VehModMngtGlbSafe1CarModSts1, implementation-data-type=VehModMngtGlbSafe1CarModSts1
      application-data-type=VehModMngtGlbSafe1UsgModSts, implementation-data-type=VehModMngtGlbSafe1UsgModSts
      application-data-type=VehPulseHeatAvl, implementation-data-type=VehPulseHeatAvl
      application-data-type=VehSpdLgt_ASW, implementation-data-type=VehSpdLgt_ASW
      application-data-type=VehSpdLgtA_ASW, implementation-data-type=VehSpdLgtA_ASW
      application-data-type=VFCInfoEna, implementation-data-type=VFCInfoEna
      application-data-type=VFCVectorBECM, implementation-data-type=VFCVectorBECM
      application-data-type=VinBlockNr_int, implementation-data-type=VinBlockNr_int
      application-data-type=VINCode, implementation-data-type=VINCode
      application-data-type=VINCodeAry, implementation-data-type=VINCodeAry
      application-data-type=VinToASW, implementation-data-type=VinToASW
      application-data-type=Vlt, implementation-data-type=Vlt
      application-data-type=WakeUpFlg, implementation-data-type=WakeUpFlg
      application-data-type=DchaPwrAllwd_ASW, implementation-data-type=DchaPwrAllwd_ASW
      application-data-type=HvBattChrgnPwrAllwd1_ASW, implementation-data-type=HvBattChrgnPwrAllwd1_ASW
      application-data-type=PNC_NM_Status, implementation-data-type=PNC_NM_Status
      application-data-type=strSecurityAccessAttemptCounter05, implementation-data-type=strSecurityAccessAttemptCounter05
      application-data-type=strSecurityAccessAttemptCounter19, implementation-data-type=strSecurityAccessAttemptCounter19
      application-data-type=strSecurityFixedByte19, implementation-data-type=strSecurityFixedByte19
  data type mapping set defaultDataTypeMappingSet_CPFS
    data-type-maps:
      application-data-type=AmbTEstimd, implementation-data-type=AmbTEstimd
      application-data-type=AmbTEstimdAmbTEstimd, implementation-data-type=AmbTEstimdAmbTEstimd
      application-data-type=AmbTEstimdQf, implementation-data-type=AmbTEstimdQf
      application-data-type=AmbTRaw, implementation-data-type=AmbTRaw
      application-data-type=AmbTRawAmbTVal, implementation-data-type=AmbTRawAmbTVal
      application-data-type=AmbTRawQly, implementation-data-type=AmbTRawQly
      application-data-type=BECMdevelpsignalgroup1, implementation-data-type=BECMdevelpsignalgroup1
      application-data-type=BECMdevelpsignalgroup1Functiondevpsignalgroup1_int, implementation-data-type=BECMdevelpsignalgroup1ElementType
      application-data-type=BECMdevelpsignalgroup2, implementation-data-type=BECMdevelpsignalgroup2
      application-data-type=BECMdevelpsignalgroup2Functiondevpsignalgroup1_int, implementation-data-type=BECMdevelpsignalgroup2ElementType
      application-data-type=BECMdevelpsignalgroup3, implementation-data-type=BECMdevelpsignalgroup3
      application-data-type=BECMdevelpsignalgroup3Functiondevpsignalgroup1_int, implementation-data-type=BECMdevelpsignalgroup3ElementType
      application-data-type=BECMdevelpsignalgroup4, implementation-data-type=BECMdevelpsignalgroup4
      application-data-type=BECMdevelpsignalgroup4Functiondevpsignalgroup1_int, implementation-data-type=BECMdevelpsignalgroup4ElementType
      application-data-type=BkpOfDstTrvld, implementation-data-type=BkpOfDstTrvld
      application-data-type=BookChrgTarValLnr, implementation-data-type=BookChrgTarValLnr
      application-data-type=CarTiGlb, implementation-data-type=CarTiGlb
      application-data-type=CellUMax, implementation-data-type=CellUMax
      application-data-type=ApplicationDataTypes/CellUMaxId, implementation-data-type=ImplementationDataTypes/CellUMaxId
      application-data-type=CellUMaxLim, implementation-data-type=CellUMaxLim
      application-data-type=CellUMin, implementation-data-type=CellUMin
      application-data-type=CellUMinId, implementation-data-type=CellUMinId
      application-data-type=ChrgEquipIDc, implementation-data-type=ChrgEquipIDc
      application-data-type=CmptmtCoolgSts, implementation-data-type=CmptmtCoolgSts
      application-data-type=CooltTSigForDtElec, implementation-data-type=CooltTSigForDtElec
      application-data-type=CPSRU, implementation-data-type=CPSRU
      application-data-type=CrashStsSafe, implementation-data-type=CrashStsSafe
      application-data-type=CrashStsSafeChks, implementation-data-type=CrashStsSafeChks
      application-data-type=CrashStsSafeCntr, implementation-data-type=CrashStsSafeCntr
      application-data-type=CrashStsSafeSts, implementation-data-type=CrashStsSafeSts
      application-data-type=DCChrgnNegPortT, implementation-data-type=DCChrgnNegPortT
      application-data-type=DCChrgnPosPortT, implementation-data-type=DCChrgnPosPortT
      application-data-type=DChrgTarValLnr, implementation-data-type=DChrgTarValLnr
      application-data-type=DenoOfDiagcRateGen, implementation-data-type=DenoOfDiagcRateGen
      application-data-type=DrvgCyc, implementation-data-type=DrvgCyc
      application-data-type=DrvgCycToClrPrmntDtc, implementation-data-type=DrvgCycToClrPrmntDtc
      application-data-type=EngAmbTCalcd, implementation-data-type=EngAmbTCalcd
      application-data-type=EngNSafe, implementation-data-type=EngNSafe
      application-data-type=EngNSafeEngN, implementation-data-type=EngNSafeEngN
      application-data-type=EngNSafeEngNChks, implementation-data-type=EngNSafeEngNChks
      application-data-type=EngNSafeEngNCntr, implementation-data-type=EngNSafeEngNCntr
      application-data-type=EngNSafeEngNGrdt, implementation-data-type=EngNSafeEngNGrdt
      application-data-type=EngOnReq, implementation-data-type=EngOnReq
      application-data-type=EngSt1WdSts, implementation-data-type=EngSt1WdSts
      application-data-type=EngSt1WdStsChks, implementation-data-type=EngSt1WdStsChks
      application-data-type=EngSt1WdStsCntr, implementation-data-type=EngSt1WdStsCntr
      application-data-type=EngSt1WdStsEngSt1WdSts, implementation-data-type=EngSt1WdStsEngSt1WdSts
      application-data-type=EngT, implementation-data-type=EngT
      application-data-type=EngTEngT, implementation-data-type=EngTEngT
      application-data-type=EngTiOn, implementation-data-type=EngTiOn
      application-data-type=EngTQf, implementation-data-type=EngTQf
      application-data-type=HvBattBalFlg, implementation-data-type=HvBattBalFlg
      application-data-type=HvBattCap, implementation-data-type=HvBattCap
      application-data-type=HvBattCellTInfo, implementation-data-type=HvBattCellTInfo
      application-data-type=HvBattCellTInfoHvBattSnsrT, implementation-data-type=HvBattCellTInfoHvBattSnsrT
      application-data-type=HvBattCellTInfoHvBattTMax, implementation-data-type=HvBattCellTInfoHvBattTMax
      application-data-type=HvBattCellTInfoHvBattTMin, implementation-data-type=HvBattCellTInfoHvBattTMin
      application-data-type=HvBattCellTInfoHvBattTSnsrNr, implementation-data-type=HvBattCellTInfoHvBattTSnsrNr
      application-data-type=HvBattCellTInfoHvTempSnsrTMaxsSerlNr, implementation-data-type=HvBattCellTInfoHvTempSnsrTMaxsSerlNr
      application-data-type=HvBattCellTInfoHvTempSnsrTMinSerlNr, implementation-data-type=HvBattCellTInfoHvTempSnsrTMinSerlNr
      application-data-type=HvBattCellTNr, implementation-data-type=HvBattCellTNr
      application-data-type=HvBattCellUInfo, implementation-data-type=HvBattCellUInfo
      application-data-type=HvBattCellUInfoU{1..4}, implementation-data-type=HvBattCellUInfoU{1..4}
      application-data-type=HvBattChrgnCmpl, implementation-data-type=HvBattChrgnCmpl
      application-data-type=HvBattChrgnEgyCnsAllwd1, implementation-data-type=HvBattChrgnEgyCnsAllwd1
      application-data-type=HvBattChrgnILim, implementation-data-type=HvBattChrgnILim
      application-data-type=HvBattChrgnPwrCns1, implementation-data-type=HvBattChrgnPwrCns1
      application-data-type=HvBattChrgnPwrCritDes1, implementation-data-type=HvBattChrgnPwrCritDes1
      application-data-type=HvBattChrgnPwrNormDes1, implementation-data-type=HvBattChrgnPwrNormDes1
      application-data-type=HvBattClimaPwr, implementation-data-type=HvBattClimaPwr
      application-data-type=HvBattClrRdyReq, implementation-data-type=HvBattClrRdyReq
      application-data-type=HvBattCod, implementation-data-type=HvBattCod
      application-data-type=HvBattCodLen, implementation-data-type=HvBattCodLen
      application-data-type=HvBattCodPackCodeX1_int, implementation-data-type=HvBattCodElementType
      application-data-type=HvBattCoolgCmd, implementation-data-type=HvBattCoolgCmd
      application-data-type=HvBattCoolgEgyCnsAllwd1, implementation-data-type=HvBattCoolgEgyCnsAllwd1
      application-data-type=HvBattCoolgEgyReq1, implementation-data-type=HvBattCoolgEgyReq1
      application-data-type=HvBattCoolgReq, implementation-data-type=HvBattCoolgReq
      application-data-type=HvBattCoolgSts, implementation-data-type=HvBattCoolgSts
      application-data-type=HvBattCooltFlowReq, implementation-data-type=HvBattCooltFlowReq
      application-data-type=HvBattCooltLvl, implementation-data-type=HvBattCooltLvl
      application-data-type=HvBattCooltMaxTReq, implementation-data-type=HvBattCooltMaxTReq
      application-data-type=HvBattCooltMinTReq, implementation-data-type=HvBattCooltMinTReq
      application-data-type=HvBattCooltOutletT, implementation-data-type=HvBattCooltOutletT
      application-data-type=HvBattCooltT, implementation-data-type=HvBattCooltT
      application-data-type=HvBattCooltTReq, implementation-data-type=HvBattCooltTReq
      application-data-type=HvBattEgyAvlChrg1, implementation-data-type=HvBattEgyAvlChrg1
      application-data-type=HvBattEgyAvlDcha1, implementation-data-type=HvBattEgyAvlDcha1
      application-data-type=HvBattEgyCdn, implementation-data-type=HvBattEgyCdn
      application-data-type=HvBattErrIndcnReq, implementation-data-type=HvBattErrIndcnReq
      application-data-type=HvBattFlwEstmd, implementation-data-type=HvBattFlwEstmd
      application-data-type=HvBattHeatgEgyReq, implementation-data-type=HvBattHeatgEgyReq
      application-data-type=HvBattHeatGenn, implementation-data-type=HvBattHeatGenn
      application-data-type=HvBattHeatgPwr, implementation-data-type=HvBattHeatgPwr
      application-data-type=HvBattIDc1, implementation-data-type=HvBattIDc1
      application-data-type=HvBattILim, implementation-data-type=HvBattILim
      application-data-type=HvBattLimnIndcn, implementation-data-type=HvBattLimnIndcn
      application-data-type=HvBattMismatchFlt, implementation-data-type=HvBattMismatchFlt
      application-data-type=HvBattNr, implementation-data-type=HvBattNr
      application-data-type=HvBattPreChrgReq, implementation-data-type=HvBattPreChrgReq
      application-data-type=HvBattPVal, implementation-data-type=HvBattPVal
      application-data-type=HvBattPwrCdn, implementation-data-type=HvBattPwrCdn
      application-data-type=HvBattPwrLimChrg1, implementation-data-type=HvBattPwrLimChrg1
      application-data-type=HvBattPwrLimDcha1, implementation-data-type=HvBattPwrLimDcha1
      application-data-type=HvBattPwrLimDchaSoft, implementation-data-type=HvBattPwrLimDchaSoft
      application-data-type=HvBattSoc, implementation-data-type=HvBattSoc
      application-data-type=HvBattSocLimHi, implementation-data-type=HvBattSocLimHi
      application-data-type=HvBattSocLimLo, implementation-data-type=HvBattSocLimLo
      application-data-type=HvBattSocLimMax, implementation-data-type=HvBattSocLimMax
      application-data-type=HvBattSocLimMin, implementation-data-type=HvBattSocLimMin
      application-data-type=HvBattT, implementation-data-type=HvBattT
      application-data-type=HvBattTAvg_int, implementation-data-type=uint16_BMS
      application-data-type=HvBattThermMod, implementation-data-type=HvBattThermMod
      application-data-type=HvBattThermReqFb, implementation-data-type=HvBattThermReqFb
      application-data-type=HvBattTMaxSerlNr, implementation-data-type=HvBattTMaxSerlNr
      application-data-type=HvBattTMinSerlNr, implementation-data-type=HvBattTMinSerlNr
      application-data-type=HvBattUDc, implementation-data-type=HvBattUDc
      application-data-type=HvBattUDynMaxLim, implementation-data-type=HvBattUDynMaxLim
      application-data-type=HvBattUDynMinLim, implementation-data-type=HvBattUDynMinLim
      application-data-type=HvBattULim, implementation-data-type=HvBattULim
      application-data-type=HvBattVoltMaxSerlNr, implementation-data-type=HvBattVoltMaxSerlNr
      application-data-type=HvBattVoltMinSerlNr, implementation-data-type=HvBattVoltMinSerlNr
      application-data-type=HvBattWMDSts, implementation-data-type=HvBattWMDSts
      application-data-type=HvCellTDifFlt, implementation-data-type=HvCellTDifFlt
      application-data-type=HvCellTOverFlt, implementation-data-type=HvCellTOverFlt
      application-data-type=HvCellUDifFlt, implementation-data-type=HvCellUDifFlt
      application-data-type=HvCellUOverFlt, implementation-data-type=HvCellUOverFlt
      application-data-type=HvCellUUnderFlt, implementation-data-type=HvCellUUnderFlt
      application-data-type=HVIL{1..3}Sts, implementation-data-type=HVIL{1..3}Sts
      application-data-type=HvilFlt, implementation-data-type=HvilFlt
      application-data-type=HvIsoFlt, implementation-data-type=HvIsoFlt
      application-data-type=HvIsoR, implementation-data-type=HvIsoR
      application-data-type=HvIsoSts, implementation-data-type=HvIsoSts
      application-data-type=HvOnMaiReq, implementation-data-type=HvOnMaiReq
      application-data-type=HvPackOverChrgFlt, implementation-data-type=HvPackOverChrgFlt
      application-data-type=HvPackUOverFlt, implementation-data-type=HvPackUOverFlt
      application-data-type=HvPackUUnderFlt, implementation-data-type=HvPackUUnderFlt
      application-data-type=HvSocHiFlt, implementation-data-type=HvSocHiFlt
      application-data-type=HvSocHopFlt, implementation-data-type=HvSocHopFlt
      application-data-type=HvSocLoFlt, implementation-data-type=HvSocLoFlt
      application-data-type=HvSysActvnInhb, implementation-data-type=HvSysActvnInhb
      application-data-type=HvSysCrashFb, implementation-data-type=HvSysCrashFb
      application-data-type=HvSysLimnIndcn, implementation-data-type=HvSysLimnIndcn
      application-data-type=HvSysPwrOff, implementation-data-type=HvSysPwrOff
      application-data-type=HvSysRlySts, implementation-data-type=HvSysRlySts
      application-data-type=HvSysRlyStsChks, implementation-data-type=HvSysRlyStsChks
      application-data-type=HvSysRlyStsCntr, implementation-data-type=HvSysRlyStsCntr
      application-data-type=HvSysRlyStsHvSysRlySts, implementation-data-type=HvSysRlyStsHvSysRlySts
      application-data-type=HvSysSts, implementation-data-type=HvSysSts
      application-data-type=IsgCooltT, implementation-data-type=IsgCooltT
      application-data-type=IsgModSts, implementation-data-type=IsgModSts
      application-data-type=IsgUDc, implementation-data-type=IsgUDc
      application-data-type=IuprDenominatorInhb, implementation-data-type=IuprDenominatorInhb
      application-data-type=LoadValCalcd, implementation-data-type=LoadValCalcd
      application-data-type=MonrCycCmpl, implementation-data-type=MonrCycCmpl
      application-data-type=PackNr, implementation-data-type=PackNr
      application-data-type=PrpsnFbLimnIndcn, implementation-data-type=PrpsnFbLimnIndcn
      application-data-type=PrpsnSysActv, implementation-data-type=PrpsnSysActv
      application-data-type=RadFanCoolgSts, implementation-data-type=RadFanCoolgSts
      application-data-type=ThrPos, implementation-data-type=ThrPos
      application-data-type=TotChrgCap, implementation-data-type=TotChrgCap
      application-data-type=TotChrgEgy, implementation-data-type=TotChrgEgy
      application-data-type=TotDchaCap, implementation-data-type=TotDchaCap
      application-data-type=TotDchaEgy, implementation-data-type=TotDchaEgy
      application-data-type=TrsmVehSpd, implementation-data-type=TrsmVehSpd
      application-data-type=VehBattU, implementation-data-type=VehBattU
      application-data-type=VehBattUSysU, implementation-data-type=VehBattUSysU
      application-data-type=VehBattUSysUQf, implementation-data-type=VehBattUSysUQf
      application-data-type=VehCfgPrm, implementation-data-type=VehCfgPrm
      application-data-type=VehCfgPrmBlkIDBytePosn1_int, implementation-data-type=VehCfgPrmElementType
      application-data-type=VehCfgPrmExt, implementation-data-type=VehCfgPrmExt
      application-data-type=VehCfgPrmExtBlkIDBytePosn1_int, implementation-data-type=VehCfgPrmExtElementType
      application-data-type=VehModMngtGlbSafe1, implementation-data-type=VehModMngtGlbSafe1
      application-data-type=VehModMngtGlbSafe1CarModSts1, implementation-data-type=VehModMngtGlbSafe1CarModSts1
      application-data-type=VehModMngtGlbSafe1CarModSubtypWdCarModSubtyp, implementation-data-type=VehModMngtGlbSafe1CarModSubtypWdCarModSubtyp
      application-data-type=VehModMngtGlbSafe1Chks, implementation-data-type=VehModMngtGlbSafe1Chks
      application-data-type=VehModMngtGlbSafe1Cntr, implementation-data-type=VehModMngtGlbSafe1Cntr
      application-data-type=VehModMngtGlbSafe1EgyLvlElecMai, implementation-data-type=VehModMngtGlbSafe1EgyLvlElecMai
      application-data-type=VehModMngtGlbSafe1EgyLvlElecSubtyp, implementation-data-type=VehModMngtGlbSafe1EgyLvlElecSubtyp
      application-data-type=VehModMngtGlbSafe1FltEgyCnsWdSts, implementation-data-type=VehModMngtGlbSafe1FltEgyCnsWdSts
      application-data-type=VehModMngtGlbSafe1PwrLvlElecMai, implementation-data-type=VehModMngtGlbSafe1PwrLvlElecMai
      application-data-type=VehModMngtGlbSafe1PwrLvlElecSubtyp, implementation-data-type=VehModMngtGlbSafe1PwrLvlElecSubtyp
      application-data-type=VehModMngtGlbSafe1UsgModSts, implementation-data-type=VehModMngtGlbSafe1UsgModSts
      application-data-type=VehSpdLgt, implementation-data-type=VehSpdLgt
      application-data-type=VehSpdLgtA, implementation-data-type=VehSpdLgtA
      application-data-type=VehSpdLgtChks, implementation-data-type=VehSpdLgtChks
      application-data-type=VehSpdLgtCntr, implementation-data-type=VehSpdLgtCntr
      application-data-type=VehSpdLgtQf, implementation-data-type=VehSpdLgtQf
      application-data-type=VFCInfoEna, implementation-data-type=VFCInfoEna
      application-data-type=VFCVectorBECM, implementation-data-type=VFCVectorBECM
      application-data-type=VFCVectorBECMBlockID, implementation-data-type=VFCVectorBECMBlockID
      application-data-type=VFCVectorBECMVFCid0, implementation-data-type=VFCVectorBECMVFCid0
      application-data-type=VFCVectorBECMVFCid1, implementation-data-type=VFCVectorBECMVFCid1
      application-data-type=VFCVectorBECMVFCid{10..19}, implementation-data-type=VFCVectorBECMVFCid{10..19}
      application-data-type=VFCVectorBECMVFCid2, implementation-data-type=VFCVectorBECMVFCid2
      application-data-type=VFCVectorBECMVFCid{20..29}, implementation-data-type=VFCVectorBECMVFCid{20..29}
      application-data-type=VFCVectorBECMVFCid3, implementation-data-type=VFCVectorBECMVFCid3
      application-data-type=VFCVectorBECMVFCid{30..39}, implementation-data-type=VFCVectorBECMVFCid{30..39}
      application-data-type=VFCVectorBECMVFCid4, implementation-data-type=VFCVectorBECMVFCid4
      application-data-type=VFCVectorBECMVFCid{40..49}, implementation-data-type=VFCVectorBECMVFCid{40..49}
      application-data-type=VFCVectorBECMVFCid5, implementation-data-type=VFCVectorBECMVFCid5
      application-data-type=VFCVectorBECMVFCid{50..59}, implementation-data-type=VFCVectorBECMVFCid{50..59}
      application-data-type=VFCVectorBECMVFCid6, implementation-data-type=VFCVectorBECMVFCid6
      application-data-type=VFCVectorBECMVFCid60, implementation-data-type=VFCVectorBECMVFCid60
      application-data-type=VFCVectorBECMVFCid61, implementation-data-type=VFCVectorBECMVFCid61
      application-data-type=VFCVectorBECMVFCid{7..9}, implementation-data-type=VFCVectorBECMVFCid{7..9}
      application-data-type=Vin, implementation-data-type=Vin
      application-data-type=WhlMotSysCooltT, implementation-data-type=WhlMotSysCooltT
      application-data-type=WhlMotSysUdc, implementation-data-type=WhlMotSysUdc
      application-data-type=ApplicationDataTypes/CellUMaxId, implementation-data-type=ImplementationDataTypes/CellUMaxId
package /CompuMethods
  compu method CarModSts1_1: 0=CarModSts1_CarModNorm, 1=CarModSts1_CarModTrnsp, 2=CarModSts1_CarModFcy, 3=CarModSts1_CarModCrash, 5=CarModSts1_CarModDyno; unit Unitless
  compu method CmptmtCoolgSts_1: 0=CmptmtCoolgSts_OffNoReq, 1=CmptmtCoolgSts_OffByEvaprTLo, 2=CmptmtCoolgSts_OffByPLo, 3=CmptmtCoolgSts_OffByAmbTOutOfRng, 4=CmptmtCoolgSts_OffBySysFailr, 5=CmptmtCoolgSts_OffByLoadCut, 6=CmptmtCoolgSts_OnWithBattCoolg, 7=CmptmtCoolgSts_On; unit Unitless
  compu method CrashFb_1: 0=CrashFb_Idle, 1=CrashFb_Evln, 2=CrashFb_Nok, 3=CrashFb_Ok; unit Unitless
  compu method EnableDisableCoding_1: 0=EnableDisableCoding_Disabled, 1=EnableDisableCoding_Enabled; unit Unitless
  compu method EngSt1_1: 0=EngSt1_Ini, 1=EngSt1_Awake, 2=EngSt1_Rdy, 3=EngSt1_PreStrtg, 4=EngSt1_StrtgInProgs, 5=EngSt1_RunngRunng, 6=EngSt1_RunngStb, 7=EngSt1_RunngStrtgInProgs, 8=EngSt1_RunngRemStrtd, 9=EngSt1_AftRun; unit Unitless
  compu method FauLevel_2: 0=FauLevel_Normal, 1=FauLevel_LevelI, 2=FauLevel_LevelII, 3=FauLevel_LevelIII; unit Unitless
  compu method filmHeatingSts: 0=filmHeatg_default, 1=heat_req, 2=heating, 3=heatingcomplete, 4=heatingstoped
  compu method GenQf1_1: 0=GenQf1_UndefindDataAccur, 1=GenQf1_TmpUndefdData, 2=GenQf1_DataAccurNotWithinSpcn, 3=GenQf1_AccurData; unit Unitless
  compu method HvActvnSts_1: 0=HvActvnSts_Open, 1=HvActvnSts_Clsd, 2=HvActvnSts_KeepSt, 3=HvActvnSts_OpenAndReqActvDcha; unit Unitless
  compu method HVBattChargnCmd_1: 0=HVBattChargnCmd_OK, 1=HVBattChargnCmd_NOK, 2=HVBattChargnCmd_INIT, 3=HVBattChargnCmd_HOLD; unit Unitless
  compu method HvBattCoolgReq_1: 0=HvBattCoolgReq_NotReqd, 1=HvBattCoolgReq_LoReq, 2=HvBattCoolgReq_MedReq, 3=HvBattCoolgReq_HiReq; unit Unitless
  compu method HvBattThermMod_2: 0=HvBattThermMod_Idle, 1=HvBattThermMod_ThermalBalancing, 2=HvBattThermMod_PassiveHeating, 3=HvBattThermMod_ActiveHeating, 4=HvBattThermMod_PassiveCooling, 5=HvBattThermMod_ActiveCooling, 6=HvBattThermMod_CombinedCooling, 7=HvBattThermMod_Reserved; unit Unitless
  compu method HvBattThermReqFb_3: 0=HvBattThermReqFb_Default, 1=HvBattThermReqFb_Heating, 2=HvBattThermReqFb_HeatFinished, 3=HvBattThermReqFb_RadiatorCooling, 4=HvBattThermReqFb_CompressorCooling, 5=HvBattThermReqFb_CoolingFinish, 6=HvBattThermReqFb_Inhibited, 7=HvBattThermReqFb_HeatingByEmotCoolt, 8=HvBattThermReqFb_Fault; unit Unitless
  compu method HvIsoSts_2: 0=Insulation_Default, 1=Insulation_Error_Battery_before_HV_Ready, 2=Insulation_Error_HV_bus_after_HV_Ready, 3=Insulation_OK; unit Unitless
  compu method IsgModTyp2_3: 0=IsgModTyp2_Inin, 1=IsgModTyp2_Stb, 2=IsgModTyp2_TqCtrl, 3=IsgModTyp2_SpdCtrl, 4=IsgModTyp2_UDcCtrl, 5=IsgModTyp2_PreChrg, 6=IsgModTyp2_PwrDwn, 7=IsgModTyp2_Flt, 8=IsgModTyp2_TcsCtrl, 9=IsgModTyp2_CluOpe; unit Unitless
  compu method Qf1_1: 0=Qf1_DevOfDataUndefd, 1=Qf1_DataTmpUndefdAndEvlnInProgs, 2=Qf1_DevOfDataNotWithinRngAllwd, 3=Qf1_DataCalcdWithDevDefd; unit Unitless
  compu method UsgModSts1_1: 0=UsgModSts1_UsgModAbdnd, 1=UsgModSts1_UsgModInActv, 2=UsgModSts1_UsgModCnvinc, 11=UsgModSts1_UsgModActv, 13=UsgModSts1_UsgModDrvg; unit Unitless
package /DataType/Unit
  unit U_kPa: display-name=kPa, factor-si-to-unit=1, offset-si-to-unit=0
package /DataTypes
  impl type AswCscTmp: category=VALUE, base-type=sint16_BMS, sw-calibration-access=READ-ONLY, type-emitter=RTE
  impl type VehCfgPrm_3: category=STRUCTURE, sw-calibration-access=READ-ONLY, type-emitter=RTE
    8 x element, all with category=TYPE_REFERENCE, implementation-data-type=uint8:
      BlkIDBytePosn1
      CCPBytePosn{2..8}
  impl type VehModMngtGlbSafe1_2: category=STRUCTURE
    10 x element, all with category=TYPE_REFERENCE, implementation-data-type=uint8:
      UsgModSts: range raw 0..7
      CarModSts1: range raw 0..7
      CarModSubtypWdCarModSubtyp
      EgyLvlElecMai: range raw 0..15
      EgyLvlElecSubtyp: range raw 0..15
      PwrLvlElecMai: range raw 0..15
      PwrLvlElecSubtyp: range raw 0..1
      FltEgyCnsWdSts: range raw 0..15
      Chks: range raw 0..15
      Cntr: range raw 0..15
package /DataTypes/Units
  unit kw: factor-si-to-unit=1, offset-si-to-unit=0
  unit kWh: display-name=kWh, factor-si-to-unit=0.1, offset-si-to-unit=0
package /MICROSAR/Dem_swc/DataTypes
  5 x impl type:
    Dem_DebounceResetStatusType: compu {0=DEM_DEBOUNCE_STATUS_FREEZE, 1=DEM_DEBOUNCE_STATUS_RESET}, range raw 0..255, implementation-data-type=uint8
    Dem_DTCFormatType: compu {0=DEM_DTC_FORMAT_OBD, 1=DEM_DTC_FORMAT_UDS, 2=DEM_DTC_FORMAT_J1939}, range raw 0..2, implementation-data-type=uint8
    Dem_EventStatusType:
      compu {0=DEM_EVENT_STATUS_PASSED, 1=DEM_EVENT_STATUS_FAILED, 2=DEM_EVENT_STATUS_PREPASSED, 3=DEM_EVENT_STATUS_PREFAILED, 4=DEM_EVENT_STATUS_FDC_THRESHOLD_REACHED, 5=DEM_EVENT_STATUS_PASSED_CONDITIONS_NOT_FULFILLED, 6=DEM_EVENT_STATUS_FAILED_CONDITIONS_NOT_FULFILLED, 7=DEM_EVENT_STATUS_PREPASSED_CONDITIONS_NOT_FULFILLED, 8=DEM_EVENT_STATUS_PREFAILED_CONDITIONS_NOT_FULFILLED}
      range raw 0..255
      implementation-data-type=uint8
    Dem_MaxDataValueType: category=ARRAY, sw-calibration-access=READ-ONLY
      element Dem_MaxDataValueTypeElement: array-size=240, array-size-semantics=FIXED-SIZE, implementation-data-type=uint8
    Dem_UdsStatusByteType:
      compu {mask 1: 1=DEM_UDS_STATUS_TF (bit 0: TestFailed), mask 2: 2=DEM_UDS_STATUS_TFTOC (bit 1: TestFailedThisOperationCycle), mask 4: 4=DEM_UDS_STATUS_PDTC (bit 2: PendingDTC), mask 8: 8=DEM_UDS_STATUS_CDTC (bit 3: ConfirmedDTC), mask 16: 16=DEM_UDS_STATUS_TNCSLC (bit 4: TestNotCompletedSinceLastClear), mask 32: 32=DEM_UDS_STATUS_TFSLC (bit 5: TestFailedSinceLastClear), mask 64: 64=DEM_UDS_STATUS_TNCTOC (bit 6: TestNotCompletedThisOperationCycle), mask 128: 128=DEM_UDS_STATUS_WIR (bit 7: WarningIndicatorRequested)}
      range raw 0..255
      implementation-data-type=uint8
package /MICROSAR/Dem_swc/Interfaces
  client server interface DiagnosticMonitor: is-service=true, service-kind=DIAGNOSTIC-EVENT-MANAGER
    12 x operation:
      GetDTCOfEvent: possible-error=[DEM_E_NO_DTC_AVAILABLE, DiagnosticMonitor/E_NOT_OK]
        arg DTCFormat: type=Dem_DTCFormatType, direction=IN, server-argument-impl-policy=USE-ARGUMENT-TYPE
        arg DTCOfEvent: type=uint32, direction=OUT, server-argument-impl-policy=USE-ARGUMENT-TYPE
      GetEventExtendedDataRecordEx: possible-error=[DEM_BUFFER_TOO_SMALL, DEM_NO_SUCH_ELEMENT, DiagnosticMonitor/E_NOT_OK]
        arg RecordNumber: type=uint8, direction=IN, server-argument-impl-policy=USE-ARGUMENT-TYPE
        arg DestBuffer: type=Dem_MaxDataValueType, direction=OUT, server-argument-impl-policy=USE-ARGUMENT-TYPE
        arg BufSize: type=uint16, direction=INOUT, server-argument-impl-policy=USE-ARGUMENT-TYPE
      GetEventFailed: possible-error=DiagnosticMonitor/E_NOT_OK
        arg EventFailed: type=ImplementationDataTypes/boolean, direction=OUT, server-argument-impl-policy=USE-ARGUMENT-TYPE
      GetEventFreezeFrameDataEx: possible-error=[DEM_BUFFER_TOO_SMALL, DEM_NO_SUCH_ELEMENT, DiagnosticMonitor/E_NOT_OK]
        4 x arg, all with server-argument-impl-policy=USE-ARGUMENT-TYPE:
          RecordNumber: type=uint8, direction=IN
          DataId: type=uint16, direction=IN
          DestBuffer: type=Dem_MaxDataValueType, direction=OUT
          BufSize: type=uint16, direction=INOUT
      GetEventStatus: possible-error=DiagnosticMonitor/E_NOT_OK
        arg UDSStatusByte: type=Dem_UdsStatusByteType, direction=OUT, server-argument-impl-policy=USE-ARGUMENT-TYPE
      GetEventTested: possible-error=DiagnosticMonitor/E_NOT_OK
        arg EventTested: type=ImplementationDataTypes/boolean, direction=OUT, server-argument-impl-policy=USE-ARGUMENT-TYPE
      GetEventUdsStatus: possible-error=DiagnosticMonitor/E_NOT_OK
        arg UDSStatusByte: type=Dem_UdsStatusByteType, direction=OUT, server-argument-impl-policy=USE-ARGUMENT-TYPE
      GetFaultDetectionCounter: possible-error=[DEM_E_NO_FDC_AVAILABLE, DiagnosticMonitor/E_NOT_OK]
        arg FaultDetectionCounter: type=sint8, direction=OUT, server-argument-impl-policy=USE-ARGUMENT-TYPE
      ResetEventDebounceStatus: possible-error=DiagnosticMonitor/E_NOT_OK
        arg DebounceResetStatus: type=Dem_DebounceResetStatusType, direction=IN, server-argument-impl-policy=USE-ARGUMENT-TYPE
      ResetEventStatus: possible-error=DiagnosticMonitor/E_NOT_OK
      SetEventDisabled: possible-error=DiagnosticMonitor/E_NOT_OK
      SetEventStatus: possible-error=DiagnosticMonitor/E_NOT_OK
        arg EventStatus: type=Dem_EventStatusType, direction=IN, server-argument-impl-policy=USE-ARGUMENT-TYPE
    5 x error:
      DEM_BUFFER_TOO_SMALL: error-code=21
      DEM_E_NO_DTC_AVAILABLE: error-code=10
      DEM_E_NO_FDC_AVAILABLE: error-code=14
      DEM_NO_SUCH_ELEMENT: error-code=48
      E_NOT_OK: error-code=1
package /MICROSAR/WdgM_swc/Interfaces
  client server interface WdgM_AliveSupervision: is-service=true, service-kind=WATCH-DOG-MANAGER
    operation CheckpointReached: possible-error=WdgM_AliveSupervision/E_NOT_OK  # Indicates to the Watchdog Manager that a Checkpoint within a Supervised Entity has been reached.
    error E_NOT_OK: error-code=1
package /Units
  19 x unit, all with factor-si-to-unit=1, offset-si-to-unit=0:
    Ah_1: display-name=Ah
    Ampr_1: display-name=A
    DegCgrd_1: display-name=degC
    KiloMtrPerHr_1: display-name=Km/h
    KiloPa_1: display-name=KiloPa
    KiloWatt_1: display-name=kW
    km_1: display-name=km
    kOhm_1: display-name=kOhm
    KwH_1
    LPerMins_1: display-name=L / min
    MtrPerSec_1: display-name=m/s
    NoUnit_1: display-name=Unitless
    Perc_1: display-name=%
    Rpm_1: display-name=rpm
    RpmPerSec_1: display-name=RpmPerSec
    Sec_1: display-name=s
    Volt_1: display-name=Volt
    Watt_1: display-name=W
    WattHr_1: display-name=Wh
